VERSION ""

NS_ :

BS_:

BU_: SCM_Main SWM_Master

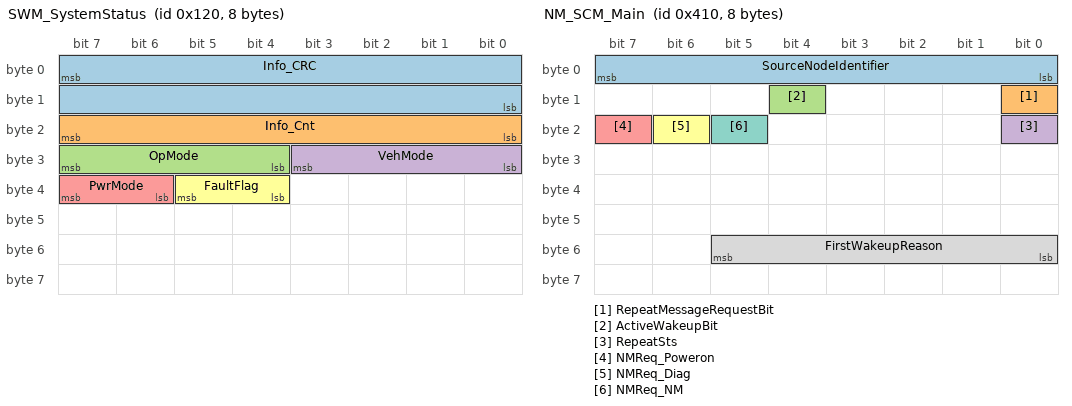
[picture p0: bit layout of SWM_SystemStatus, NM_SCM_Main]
BO_ 288 SWM_SystemStatus: 8 SWM_Master
 SG_ Info_CRC : 7|16@0+ (1,0) [0|65535] ""  SCM_Main
 SG_ Info_Cnt : 23|8@0+ (1,0) [0|255] ""  SCM_Main
 SG_ OpMode : 31|4@0+ (1,0) [0|15] ""  SCM_Main
 SG_ VehMode : 27|4@0+ (1,0) [0|15] ""  SCM_Main
 SG_ PwrMode : 39|2@0+ (1,0) [0|3] ""  SCM_Main
 SG_ FaultFlag : 37|2@0+ (1,0) [0|3] ""  SCM_Main

BO_ 528 SWM_ButtonCtrl: 32 SWM_Master
 SG_ BtnCtrl_CRC : 7|16@0+ (1,0) [0|65535] ""  SCM_Main
 SG_ BtnCtrl_RollCnt : 23|8@0+ (1,0) [0|255] ""  SCM_Main
 SG_ VolUp_Button : 29|2@0+ (1,0) [0|3] ""  SCM_Main
 SG_ VolUp_Intensity : 39|3@0+ (1,0) [0|7] "%"  SCM_Main
 SG_ VolUp_RampEnable : 50|3@0+ (1,0) [0|7] ""  SCM_Main
 SG_ VolDown_Button : 57|2@0+ (1,0) [0|3] ""  SCM_Main
 SG_ VolDown_Intensity : 69|7@0+ (1,0) [0|100] "%"  SCM_Main
 SG_ VolDown_RampEnable : 87|3@0+ (1,0) [0|7] ""  SCM_Main
 SG_ Mute_Button : 89|2@0+ (1,0) [0|3] ""  SCM_Main
 SG_ Mode_Button : 93|2@0+ (1,0) [0|3] ""  SCM_Main
 SG_ TrackNext_Button : 95|2@0+ (1,0) [0|3] ""  SCM_Main
 SG_ TrackPrev_Button : 123|4@0+ (1,0) [0|15] ""  SCM_Main
 SG_ Menu_Enter_Button : 131|4@0+ (1,0) [0|15] ""  SCM_Main
 SG_ Menu_Back_Button : 135|4@0+ (1,0) [0|15] ""  SCM_Main
 SG_ Menu_Up_Button : 139|2@0+ (1,0) [0|3] ""  SCM_Main
 SG_ Menu_Down_Button : 143|4@0+ (1,0) [0|15] ""  SCM_Main
 SG_ Menu_Left_Button : 149|2@0+ (1,0) [0|3] ""  SCM_Main
 SG_ Menu_Right_Button : 151|2@0+ (1,0) [0|3] ""  SCM_Main
 SG_ Cruise_OnOff : 155|2@0+ (1,0) [0|3] ""  SCM_Main
 SG_ Cruise_Set : 159|2@0+ (1,0) [0|3] ""  SCM_Main
 SG_ Cruise_Resume : 170|3@0+ (1,0) [0|7] ""  SCM_Main
 SG_ Cruise_Cancel : 172|2@0+ (1,0) [0|3] ""  SCM_Main
 SG_ Cruise_Accel : 203|3@0+ (1,0) [0|7] "%"  SCM_Main
 SG_ Cruise_Decel : 207|2@0+ (1,0) [0|3] ""  SCM_Main
 SG_ Phone_Answer : 213|3@0+ (1,0) [0|7] ""  SCM_Main
 SG_ Phone_Hangup : 199|3@0+ (1,0) [0|7] ""  SCM_Main
 SG_ Voice_Button : 251|4@0+ (1,0) [0|15] ""  SCM_Main

BO_ 480 EPS_SteeringData: 32 SWM_Master
 SG_ SteerData_CRC : 7|16@0+ (1,0) [0|65535] ""  SCM_Main
 SG_ SteerData_RollCnt : 23|8@0+ (1,0) [0|255] ""  SCM_Main
 SG_ TorqueSensor1 : 31|10@0+ (10,0) [0|6000] ""  SCM_Main
 SG_ TorqueSensor2 : 37|10@0+ (10,0) [0|8000] ""  SCM_Main
 SG_ SteerAngle : 62|14@0+ (0.1,-780) [-780|858.3] "deg"  SCM_Main
 SG_ SteerAngleSpeed : 64|15@0+ (0.1,-1024) [-1024|2252.7] "deg/s"  SCM_Main
 SG_ VehSpeedValid : 175|1@0+ (1,0) [0|1] ""  SCM_Main
 SG_ VehSpeed : 174|13@0+ (0.05625,0) [0|460.74375] "km/h"  SCM_Main
 SG_ RackForce_Left : 191|8@0+ (1,-80) [-80|175] "mm"  SCM_Main
 SG_ RackForce_Right : 199|8@0+ (1,-80) [-80|175] "mm"  SCM_Main
 SG_ RackForce_RearL : 207|8@0+ (1,-80) [-80|175] "mm"  SCM_Main
 SG_ RackForce_RearR : 215|8@0+ (1,-80) [-80|175] "mm"  SCM_Main
 SG_ GearPosition : 236|2@0+ (1,0) [0|3] ""  SCM_Main
 SG_ GearPosValid : 234|1@0+ (1,0) [0|1] ""  SCM_Main

BO_ 1216 SCM_AngleStatus: 32 SCM_Main
 SG_ AngleSts_CRC : 7|16@0+ (1,0) [0|65535] ""  SWM_Master
 SG_ AngleSts_RollCnt : 23|8@0+ (1,0) [0|255] ""  SWM_Master
 SG_ SteerAngleStatus : 31|2@0+ (1,0) [0|3] ""  SWM_Master
 SG_ SteerAngleValid : 39|3@0+ (1,0) [0|7] "%"  SWM_Master
 SG_ SteerAngleFault : 52|3@0+ (1,0) [0|7] ""  SWM_Master
 SG_ ClockSpringAngle : 59|2@0+ (1,0) [0|3] ""  SWM_Master
 SG_ ClockSpringFault : 69|2@0+ (1,0) [0|3] ""  SWM_Master
 SG_ ReturnLevel : 65|7@0+ (1,0) [0|100] "%"  SWM_Master
 SG_ ReturnFault : 83|3@0+ (1,0) [0|7] ""  SWM_Master
 SG_ TiltPosition : 89|2@0+ (1,0) [0|3] ""  SWM_Master
 SG_ TiltFault : 93|2@0+ (1,0) [0|3] ""  SWM_Master
 SG_ TelescopePosition : 99|2@0+ (1,0) [0|3] ""  SWM_Master
 SG_ TelescopeFault : 101|2@0+ (1,0) [0|3] ""  SWM_Master
 SG_ HeatingStatus : 103|2@0+ (1,0) [0|3] ""  SWM_Master
 SG_ HeatingFault : 133|4@0+ (1,0) [0|15] ""  SWM_Master
 SG_ LockStatus : 137|2@0+ (1,0) [0|3] ""  SWM_Master
 SG_ LockFault : 139|2@0+ (1,0) [0|3] ""  SWM_Master
 SG_ CalibrationStatus : 143|4@0+ (1,0) [0|15] ""  SWM_Master
 SG_ CalibrationFault : 145|2@0+ (1,0) [0|3] ""  SWM_Master
 SG_ ButtonSwitch_Status : 147|2@0+ (1,0) [0|3] ""  SWM_Master
 SG_ ButtonSwitch_Fault : 149|2@0+ (1,0) [0|3] ""  SWM_Master
 SG_ AFSFltSt : 151|2@0+ (1,0) [0|3] ""  SWM_Master
 SG_ SteerAssistEffectShowSt : 163|4@0+ (1,0) [0|15] ""  SWM_Master
 SG_ SWCEffectShowSt : 167|4@0+ (1,0) [0|15] ""  SWM_Master
 SG_ FLADSButtonFlt : 170|2@0+ (1,0) [0|3] ""  SWM_Master
 SG_ FLADSButtonBri : 173|3@0+ (1,0) [0|7] ""  SWM_Master
 SG_ FLADSButtonStatus : 175|2@0+ (1,0) [0|3] ""  SWM_Master
 SG_ MFLPosButtonStatus : 205|2@0+ (1,0) [0|3] ""  SWM_Master
 SG_ MFLPosButtonFlowStatus : 211|3@0+ (1,0) [0|7] ""  SWM_Master
 SG_ MFLPosButtonBri : 201|3@0+ (1,0) [0|7] "%"  SWM_Master
 SG_ MFLPosButtonFlt : 221|2@0+ (1,0) [0|3] ""  SWM_Master
 SG_ ALSPitchAg : 219|6@0+ (0.1,-4) [-4|2.3] ""  SWM_Master
 SG_ PosButtonVoiceSigSts : 189|4@0+ (1,0) [0|15] ""  SWM_Master

BO_ 1040 NM_SCM_Main: 8 SCM_Main
 SG_ SourceNodeIdentifier : 7|8@0+ (1,0) [0|255] "" Vector__XXX
 SG_ RepeatMessageRequestBit : 8|1@0+ (1,0) [0|1] "" Vector__XXX
 SG_ ActiveWakeupBit : 12|1@0+ (1,0) [0|1] "" Vector__XXX
 SG_ RepeatSts : 16|1@0+ (1,0) [0|1] "" Vector__XXX
 SG_ NMReq_Poweron : 23|1@0+ (1,0) [0|1] "" Vector__XXX
 SG_ NMReq_Diag : 22|1@0+ (1,0) [0|1] "" Vector__XXX
 SG_ NMReq_NM : 21|1@0+ (1,0) [0|1] "" Vector__XXX
 SG_ FirstWakeupReason : 53|6@0+ (1,0) [0|63] "" Vector__XXX

BO_ 2015 Diag_FunctionalReq: 64 SWM_Master
 SG_ FuncReq_Data : 7|64@0+ (1,0) [0|0] ""  SCM_Main

BO_ 1841 Diag_PhyReq_SCM: 64 SWM_Master
 SG_ PhyReq_SCM_Data : 7|64@0+ (1,0) [0|1.84467440737095E+019] ""  SCM_Main

BO_ 1969 Diag_Resp_SCM: 64 SCM_Main
 SG_ Resp_SCM_Data : 7|64@0+ (1,0) [0|1.84467440737095E+019] ""  SWM_Master

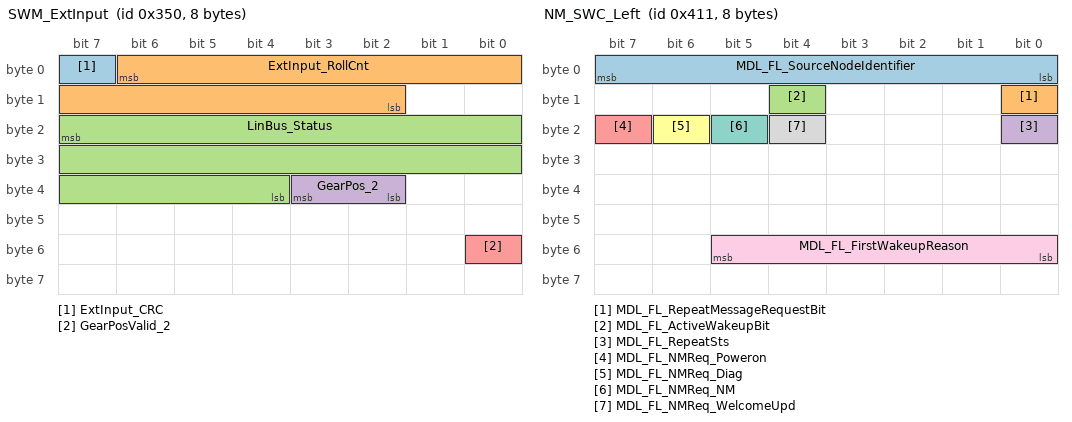
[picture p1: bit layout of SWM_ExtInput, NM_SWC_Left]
BO_ 848 SWM_ExtInput: 8 SWM_Master
 SG_ ExtInput_CRC : 7|1@0+ (1,0) [0|1] ""  SCM_Main
 SG_ ExtInput_RollCnt : 6|13@0+ (0.05625,0) [0|460.74375] "km/h"  SCM_Main
 SG_ LinBus_Status : 23|20@0+ (1,0) [0|1048575] "km"  SCM_Main
 SG_ GearPos_2 : 35|2@0+ (1,0) [0|3] ""  SCM_Main
 SG_ GearPosValid_2 : 48|1@0+ (1,0) [0|1] ""  SCM_Main

BO_ 336 SWM_Multimedia1: 32 SWM_Master
 SG_ Media1_CRC : 31|4@0+ (1,0) [0|15] ""  SCM_Main
 SG_ Media1_RollCnt : 27|4@0+ (1,0) [0|15] ""  SCM_Main
 SG_ DisplayBrightness : 39|4@0+ (1,0) [0|15] ""  SCM_Main
 SG_ DisplayContrast : 35|4@0+ (1,0) [0|15] ""  SCM_Main
 SG_ BackswitchLevel : 47|6@0+ (1,0) [0|63] ""  SCM_Main
 SG_ BackswitchAuto : 41|4@0+ (1,0) [0|15] ""  SCM_Main
 SG_ TouchSensitivity : 53|12@0+ (0.1,0) [0|409.5] "��"  SCM_Main
 SG_ TouchValid : 71|11@0+ (0.05,-40) [-40|62.35] "��"  SCM_Main
 SG_ GestureDetect : 76|11@0+ (0.05,-40) [-40|62.35] "��"  SCM_Main
 SG_ GestureType : 81|10@0+ (0.2,-50) [-50|154.6] "��/s"  SCM_Main
 SG_ ProximityDetect : 103|2@0+ (1,0) [0|3] ""  SCM_Main
 SG_ ProximityDist : 101|7@0+ (0.2,-12) [-12|13.4] "��"  SCM_Main
 SG_ AmbientSwitch_Left : 110|6@0+ (1,0) [0|63] ""  SCM_Main
 SG_ AmbientSwitch_Right : 104|4@0+ (1,0) [0|15] ""  SCM_Main
 SG_ ColorTemp_R : 116|12@0+ (0.1,0) [0|409.5] "��"  SCM_Main
 SG_ ColorTemp_G : 120|11@0+ (0.05,-40) [-40|62.35] "��"  SCM_Main
 SG_ ColorTemp_B : 141|11@0+ (0.05,-40) [-40|62.35] "��"  SCM_Main
 SG_ AnimSpeed : 146|10@0+ (0.2,-50) [-50|154.6] "��/s"  SCM_Main
 SG_ AnimMode : 152|2@0+ (1,0) [0|3] ""  SCM_Main
 SG_ ScreenSaver_On : 166|7@0+ (0.2,-12) [-12|13.4] "��"  SCM_Main
 SG_ ScreenSaver_Timeout : 175|6@0+ (1,0) [0|63] ""  SCM_Main
 SG_ ThemeSelect : 169|4@0+ (1,0) [0|15] ""  SCM_Main
 SG_ LayoutMode : 181|12@0+ (0.1,0) [0|409.5] "��"  SCM_Main
 SG_ FontSize : 185|11@0+ (0.05,-40) [-40|62.35] "��"  SCM_Main
 SG_ DensityMode : 206|11@0+ (0.05,-40) [-40|62.35] "��"  SCM_Main
 SG_ NightMode_Enable : 211|10@0+ (0.2,-50) [-50|154.6] "��/s"  SCM_Main
 SG_ NightMode_Sensor : 217|2@0+ (1,0) [0|3] ""  SCM_Main
 SG_ WakeupSource : 231|7@0+ (0.2,-12) [-12|13.4] "��"  SCM_Main
 SG_ SleepTimer : 224|7@0+ (0.2,-12) [-12|13.4] "��"  SCM_Main
 SG_ ADS_Adb2_Object_TopAngle : 233|7@0+ (0.2,-12) [-12|13.4] "��"  SCM_Main
 SG_ ADS_Adb3_Object_TopAngle : 242|7@0+ (0.2,-12) [-12|13.4] "��"  SCM_Main

BO_ 337 SWM_Multimedia2: 32 SWM_Master
 SG_ Media2_CRC : 47|6@0+ (1,0) [0|63] ""  SCM_Main
 SG_ Media2_RollCnt : 41|4@0+ (1,0) [0|15] ""  SCM_Main
 SG_ RadioPreset_1 : 53|12@0+ (0.1,0) [0|409.5] "��"  SCM_Main
 SG_ RadioPreset_2 : 71|11@0+ (0.05,-40) [-40|62.35] "��"  SCM_Main
 SG_ RadioPreset_3 : 76|11@0+ (0.05,-40) [-40|62.35] "��"  SCM_Main
 SG_ RadioPreset_4 : 81|10@0+ (0.2,-50) [-50|154.6] "��/s"  SCM_Main
 SG_ RadioPreset_5 : 103|2@0+ (1,0) [0|3] ""  SCM_Main
 SG_ RadioPreset_6 : 101|7@0+ (0.2,-12) [-12|13.4] "��"  SCM_Main
 SG_ SourceSelect : 110|6@0+ (1,0) [0|63] ""  SCM_Main
 SG_ SourceValid : 104|4@0+ (1,0) [0|15] ""  SCM_Main
 SG_ Volume_Master : 116|12@0+ (0.1,0) [0|409.5] "��"  SCM_Main
 SG_ Volume_Media : 120|11@0+ (0.05,-40) [-40|62.35] "��"  SCM_Main
 SG_ Volume_Nav : 141|11@0+ (0.05,-40) [-40|62.35] "��"  SCM_Main
 SG_ Volume_Phone : 146|10@0+ (0.2,-50) [-50|154.6] "��/s"  SCM_Main
 SG_ Bass_Level : 152|2@0+ (1,0) [0|3] ""  SCM_Main
 SG_ Treble_Level : 166|7@0+ (0.2,-12) [-12|13.4] "��"  SCM_Main
 SG_ Mid_Level : 175|6@0+ (1,0) [0|63] ""  SCM_Main
 SG_ Balance_Fade : 169|4@0+ (1,0) [0|15] ""  SCM_Main
 SG_ Surround_Mode : 181|12@0+ (0.1,0) [0|409.5] "��"  SCM_Main
 SG_ Surround_Level : 185|11@0+ (0.05,-40) [-40|62.35] "��"  SCM_Main
 SG_ EQ_Preset : 206|11@0+ (0.05,-40) [-40|62.35] "��"  SCM_Main
 SG_ EQ_Custom : 211|10@0+ (0.2,-50) [-50|154.6] "��/s"  SCM_Main
 SG_ Loudness_On : 217|2@0+ (1,0) [0|3] ""  SCM_Main
 SG_ Subwoofer_Level : 231|7@0+ (0.2,-12) [-12|13.4] "��"  SCM_Main
 SG_ Fader_Front : 224|7@0+ (0.2,-12) [-12|13.4] "��"  SCM_Main
 SG_ Fader_Rear : 233|7@0+ (0.2,-12) [-12|13.4] "��"  SCM_Main
 SG_ Balance_Left : 242|7@0+ (0.2,-12) [-12|13.4] "��"  SCM_Main

BO_ 338 SWM_Multimedia3: 32 SWM_Master
 SG_ Media3_CRC : 47|6@0+ (1,0) [0|63] ""  SCM_Main
 SG_ Media3_RollCnt : 41|4@0+ (1,0) [0|15] ""  SCM_Main
 SG_ Nav_ZoomIn : 53|12@0+ (0.1,0) [0|409.5] "��"  SCM_Main
 SG_ Nav_ZoomOut : 71|11@0+ (0.05,-40) [-40|62.35] "��"  SCM_Main
 SG_ Nav_Menu : 76|11@0+ (0.05,-40) [-40|62.35] "��"  SCM_Main
 SG_ Nav_Favorite : 81|10@0+ (0.2,-50) [-50|154.6] "��/s"  SCM_Main
 SG_ Nav_Home : 103|2@0+ (1,0) [0|3] ""  SCM_Main
 SG_ Nav_Destination : 101|7@0+ (0.2,-12) [-12|13.4] "��"  SCM_Main
 SG_ Nav_RouteCalc : 110|6@0+ (1,0) [0|63] ""  SCM_Main
 SG_ Nav_MuteGuidance : 104|4@0+ (1,0) [0|15] ""  SCM_Main
 SG_ Map_Orientation : 116|12@0+ (0.1,0) [0|409.5] "��"  SCM_Main
 SG_ Map_DayNight : 120|11@0+ (0.05,-40) [-40|62.35] "��"  SCM_Main
 SG_ Map_TrafficOn : 141|11@0+ (0.05,-40) [-40|62.35] "��"  SCM_Main
 SG_ Map_POI_Select : 146|10@0+ (0.2,-50) [-50|154.6] "��/s"  SCM_Main
 SG_ SpeedLimit_Display : 152|2@0+ (1,0) [0|3] ""  SCM_Main
 SG_ SpeedLimit_Warn : 166|7@0+ (0.2,-12) [-12|13.4] "��"  SCM_Main
 SG_ LaneGuidance_On : 175|6@0+ (1,0) [0|63] ""  SCM_Main
 SG_ LaneGuidance_Brightness : 169|4@0+ (1,0) [0|15] ""  SCM_Main
 SG_ HeadUpDisplay_On : 181|12@0+ (0.1,0) [0|409.5] "��"  SCM_Main
 SG_ HeadUpDisplay_Brightness : 185|11@0+ (0.05,-40) [-40|62.35] "��"  SCM_Main
 SG_ HeadUpDisplay_Pos : 206|11@0+ (0.05,-40) [-40|62.35] "��"  SCM_Main
 SG_ HeadUpDisplay_Rotation : 211|10@0+ (0.2,-50) [-50|154.6] "��/s"  SCM_Main
 SG_ ClusterNav_On : 217|2@0+ (1,0) [0|3] ""  SCM_Main
 SG_ ClusterNav_Mode : 231|7@0+ (0.2,-12) [-12|13.4] "��"  SCM_Main
 SG_ VoiceNav_On : 224|7@0+ (0.2,-12) [-12|13.4] "��"  SCM_Main
 SG_ VoiceNav_Volume : 233|7@0+ (0.2,-12) [-12|13.4] "��"  SCM_Main
 SG_ TrafficInfo_On : 242|7@0+ (0.2,-12) [-12|13.4] "��"  SCM_Main

BO_ 339 SWM_Multimedia4: 32 SWM_Master
 SG_ Media4_CRC : 47|6@0+ (1,0) [0|63] ""  SCM_Main
 SG_ Media4_RollCnt : 41|4@0+ (1,0) [0|15] ""  SCM_Main
 SG_ ADAS_LDWS_On : 53|12@0+ (0.1,0) [0|409.5] "��"  SCM_Main
 SG_ ADAS_LDWS_Sensitivity : 71|11@0+ (0.05,-40) [-40|62.35] "��"  SCM_Main
 SG_ ADAS_FCW_On : 76|11@0+ (0.05,-40) [-40|62.35] "��"  SCM_Main
 SG_ ADAS_FCW_Distance : 81|10@0+ (0.2,-50) [-50|154.6] "��/s"  SCM_Main
 SG_ ADAS_AEB_On : 103|2@0+ (1,0) [0|3] ""  SCM_Main
 SG_ ADAS_AEB_Sensitivity : 110|7@0+ (0.2,-12) [-12|13.4] "��"  SCM_Main
 SG_ ADAS_ACC_On : 101|7@0+ (0.2,-12) [-12|13.4] "��"  SCM_Main
 SG_ ADAS_ACC_Speed : 119|64@0+ (1,0) [0|1.84467440737095E+019] ""  SCM_Main

BO_ 1312 SCM_FaultInfo: 32 SCM_Main
 SG_ FaultInfo_CRC : 7|8@0+ (1,0) [0|255] ""  SWM_Master
 SG_ FaultInfo_RollCnt : 12|5@0+ (1,0) [0|31] ""  SWM_Master
 SG_ DTC_Severity : 15|3@0+ (1,0) [0|7] ""  SWM_Master
 SG_ DTC_HighByte : 23|12@0+ (1,0) [0|4095] ""  SWM_Master
 SG_ DTC_LowByte : 27|12@0+ (1,0) [0|4095] ""  SWM_Master
 SG_ DTC_FaultType : 47|12@0+ (1,0) [0|4095] ""  SWM_Master
 SG_ DTC_Status : 51|12@0+ (1,0) [0|4095] ""  SWM_Master
 SG_ DTC_Type : 71|12@0+ (1,0) [0|4095] ""  SWM_Master
 SG_ Fault_Age : 75|12@0+ (1,0) [0|4095] ""  SWM_Master
 SG_ Fault_Mileage : 95|12@0+ (1,0) [0|4095] ""  SWM_Master
 SG_ WarnButton_Status : 99|12@0+ (1,0) [0|4095] ""  SWM_Master
 SG_ WarnButton_Fault : 119|12@0+ (1,0) [0|4095] ""  SWM_Master
 SG_ Degraded_Mode : 123|12@0+ (1,0) [0|4095] ""  SWM_Master
 SG_ Recovery_Status : 143|12@0+ (1,0) [0|4095] ""  SWM_Master
 SG_ SelfTest_Result : 147|12@0+ (1,0) [0|4095] ""  SWM_Master
 SG_ SelfTest_Progress : 167|12@0+ (1,0) [0|4095] ""  SWM_Master
 SG_ FaultNum14 : 171|12@0+ (1,0) [0|4095] ""  SWM_Master
 SG_ FaultNum15 : 191|12@0+ (1,0) [0|4095] ""  SWM_Master
 SG_ FaultNum16 : 195|12@0+ (1,0) [0|4095] ""  SWM_Master
 SG_ FaultNum17 : 215|12@0+ (1,0) [0|4095] ""  SWM_Master
 SG_ FaultNum18 : 219|12@0+ (1,0) [0|4095] ""  SWM_Master
 SG_ FaultNum19 : 239|12@0+ (1,0) [0|4095] ""  SWM_Master
 SG_ FaultNum20 : 243|12@0+ (1,0) [0|4095] ""  SWM_Master

BO_ 1041 NM_SWC_Left: 8 Vector__XXX
 SG_ MDL_FL_SourceNodeIdentifier : 7|8@0+ (1,0) [0|255] ""  SWM_Master,SCM_Main
 SG_ MDL_FL_RepeatMessageRequestBit : 8|1@0+ (1,0) [0|1] ""  SWM_Master,SCM_Main
 SG_ MDL_FL_ActiveWakeupBit : 12|1@0+ (1,0) [0|1] ""  SWM_Master,SCM_Main
 SG_ MDL_FL_RepeatSts : 16|1@0+ (1,0) [0|1] ""  SWM_Master,SCM_Main
 SG_ MDL_FL_NMReq_Poweron : 23|1@0+ (1,0) [0|1] ""  SWM_Master,SCM_Main
 SG_ MDL_FL_NMReq_Diag : 22|1@0+ (1,0) [0|1] ""  SWM_Master,SCM_Main
 SG_ MDL_FL_NMReq_NM : 21|1@0+ (1,0) [0|1] ""  SWM_Master,SCM_Main
 SG_ MDL_FL_NMReq_WelcomeUpd : 20|1@0+ (1,0) [0|1] ""  SWM_Master,SCM_Main
 SG_ MDL_FL_FirstWakeupReason : 53|6@0+ (1,0) [0|63] ""  SWM_Master,SCM_Main

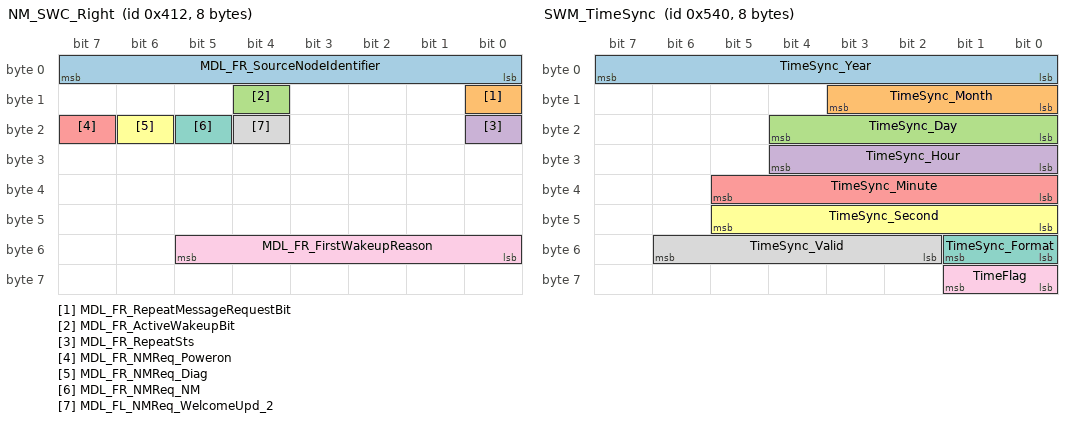
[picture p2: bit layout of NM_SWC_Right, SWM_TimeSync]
BO_ 1042 NM_SWC_Right: 8 Vector__XXX
 SG_ MDL_FR_SourceNodeIdentifier : 7|8@0+ (1,0) [0|255] ""  SWM_Master,SCM_Main
 SG_ MDL_FR_RepeatMessageRequestBit : 8|1@0+ (1,0) [0|1] ""  SWM_Master,SCM_Main
 SG_ MDL_FR_ActiveWakeupBit : 12|1@0+ (1,0) [0|1] ""  SWM_Master,SCM_Main
 SG_ MDL_FR_RepeatSts : 16|1@0+ (1,0) [0|1] ""  SWM_Master,SCM_Main
 SG_ MDL_FR_NMReq_Poweron : 23|1@0+ (1,0) [0|1] ""  SWM_Master,SCM_Main
 SG_ MDL_FR_NMReq_Diag : 22|1@0+ (1,0) [0|1] ""  SWM_Master,SCM_Main
 SG_ MDL_FR_NMReq_NM : 21|1@0+ (1,0) [0|1] ""  SWM_Master,SCM_Main
 SG_ MDL_FL_NMReq_WelcomeUpd_2 : 20|1@0+ (1,0) [0|1] ""  SWM_Master,SCM_Main
 SG_ MDL_FR_FirstWakeupReason : 53|6@0+ (1,0) [0|63] ""  SWM_Master,SCM_Main

BO_ 1344 SWM_TimeSync: 8 SWM_Master
 SG_ TimeSync_Year : 7|8@0+ (1,2000) [2000|2255] "Year"  SCM_Main
 SG_ TimeSync_Month : 11|4@0+ (1,0) [1|12] "Month"  SCM_Main
 SG_ TimeSync_Day : 20|5@0+ (1,0) [1|31] "Day"  SCM_Main
 SG_ TimeSync_Hour : 28|5@0+ (1,0) [0|23] "h"  SCM_Main
 SG_ TimeSync_Minute : 37|6@0+ (1,0) [0|59] "min"  SCM_Main
 SG_ TimeSync_Second : 45|6@0+ (1,0) [0|59] "s"  SCM_Main
 SG_ TimeSync_Format : 49|2@0+ (1,0) [0|3] ""  SCM_Main
 SG_ TimeSync_Valid : 54|5@0+ (1,0) [0|31] ""  SCM_Main
 SG_ TimeFlag : 57|2@0+ (1,0) [0|3] ""  SCM_Main

CM_ "Version:V1.2,Date:2026/2/6,Author:Pengwanli��lican,wangzhilin,Review:,Approval:,Description:(SCM_FL)1��0x280�ź�SWM_FrontADSButtonBriSet���ö��ֵ--Ѧ����;
Version:V1.2,Date:2026/2/6,Author:Pengwanli��lican,wangzhilin,Review:,Approval:,Description:(SCM_FL)SCM_FL���0x500�ź�SCM_FL_FLADSButtonBri��ö��ֵ--Ѧ����;
 ";
CM_ BO_ 288 "�����û�ģʽ����Դģʽ";
CM_ SG_ 288 Info_CRC "CRC16 Checksum (Data ID: 0x41D2)";
CM_ SG_ 288 Info_Cnt "RollingCounter";
CM_ SG_ 288 OpMode "�����û�ģʽ";
CM_ SG_ 288 VehMode "����ģʽ";
CM_ SG_ 288 PwrMode "������Դģʽ";
CM_ SG_ 288 FaultFlag "��Դģʽ����״̬";
CM_ BO_ 528 "VIU�ձ๦��";
CM_ SG_ 528 BtnCtrl_CRC "CRC16 checksum��Data ID: 0x4378��";
CM_ SG_ 528 BtnCtrl_RollCnt "Rolling Counter";
CM_ SG_ 528 VolUp_Button "��ǰλ�Ƶ����ر�����";
CM_ SG_ 528 VolUp_Intensity "��ǰλ����������";
CM_ SG_ 528 VolUp_RampEnable "��ǰλ����ˮʹ��";
CM_ SG_ 528 VolDown_Button "��ǰת��Ƶ����ر�����";
CM_ SG_ 528 VolDown_Intensity "��ǰת�����������";
CM_ SG_ 528 VolDown_RampEnable "��ǰת�����ˮʹ��";
CM_ SG_ 528 Mute_Button "Զ��Ƶ����ر�����";
CM_ SG_ 528 Mode_Button "����Ƶ����ر�����";
CM_ SG_ 528 TrackNext_Button "����Ӧǰ�յ�ϵͳʹ��";
CM_ SG_ 528 TrackPrev_Button "ǰ�ᴩ�Ƶ���Ч����������";
CM_ SG_ 528 Menu_Enter_Button "����Ƶ���Ч����������";
CM_ SG_ 528 Menu_Back_Button "ǰ�ᴩ�Ƶ���Ч��ѡ��";
CM_ SG_ 528 Menu_Up_Button "λ�õƹ���״̬";
CM_ SG_ 528 Menu_Down_Button "����Ƶ���Ч��ѡ��";
CM_ SG_ 528 Menu_Left_Button "����ӦԶ��ƹ��ܼ�������";
CM_ SG_ 528 Menu_Right_Button "����ƹ���״̬";
CM_ SG_ 528 Cruise_OnOff "ǰ�ᴩ�Ƶ���Ч��ģʽ����";
CM_ SG_ 528 Cruise_Set "����Ƶ���Ч��ģʽ����";
CM_ SG_ 528 Cruise_Resume "ǰADS����������";
CM_ SG_ 528 Cruise_Cancel "ǰADS�Ƶ����ر�����";
CM_ SG_ 528 Cruise_Accel "��ǰ��λ����������";
CM_ SG_ 528 Cruise_Decel "��ǰ��λ�Ƶ����ر�����";
CM_ SG_ 528 Phone_Answer "��ǰ��λ����ˮʹ������";
CM_ SG_ 528 Phone_Hangup "����Ƹ߶ȵ�λ";
CM_ SG_ 528 Voice_Button "��ǰλ��������������";
CM_ BO_ 480 "�ź�·��";
CM_ SG_ 480 SteerData_CRC "CRC16 checksum��Data ID: 0x42A4��";
CM_ SG_ 480 SteerData_RollCnt "Rolling Counter";
CM_ SG_ 480 TorqueSensor1 "ǰ���ֵ";
CM_ SG_ 480 TorqueSensor2 "����������ֵ";
CM_ SG_ 480 SteerAngle "ת��(���λ��ת�������ֳ������ϵ�ĽǶȣ������Ҹ�)Pinion angle(0x3CF1~0x3FFE:reserved)";
CM_ SG_ 480 SteerAngleSpeed "ת���ٶ�(���λ��ת�������ֳ������ϵ�ĽǶȣ������Ҹ�)Pinion angle(0x5001~0x7FFE:reserved)";
CM_ SG_ 480 VehSpeedValid "vehicle reference speed Valid
������Чλ";
CM_ SG_ 480 VehSpeed "vehicle reference speed
����";
CM_ SG_ 480 RackForce_Left "ʵ����ǰ������Ը߶�(����ڿջɱ�׼�߶����������½��ĸ߶�ֵ)";
CM_ SG_ 480 RackForce_Right "ʵ����ǰ������Ը߶�(����ڿջɱ�׼�߶����������½��ĸ߶�ֵ)";
CM_ SG_ 480 RackForce_RearL "ʵ���������Ը߶�(����ڿջɱ�׼�߶����������½��ĸ߶�ֵ)";
CM_ SG_ 480 RackForce_RearR "ʵ���Һ�����Ը߶�(����ڿջɱ�׼�߶����������½��ĸ߶�ֵ)";
CM_ SG_ 480 GearPosition "Actual gear engaged
��ʵ��λ";
CM_ SG_ 480 GearPosValid "Actual gear valid signal
��ʵ��λ��Чλ";
CM_ SG_ 1216 AngleSts_CRC "CRC16 checksum��Data ID: 0x455F��";
CM_ SG_ 1216 AngleSts_RollCnt "Rolling Counter";
CM_ SG_ 1216 SteerAngleStatus "��ǰλ�Ƶ����ر�״̬";
CM_ SG_ 1216 SteerAngleValid "��ǰλ������";
CM_ SG_ 1216 SteerAngleFault "��ǰλ����ˮ״̬";
CM_ SG_ 1216 ClockSpringAngle "��ǰλ�ƹ���";
CM_ SG_ 1216 ClockSpringFault "��ǰת��Ƶ����ر�״̬";
CM_ SG_ 1216 ReturnLevel "��ǰת�������";
CM_ SG_ 1216 ReturnFault "��ǰת�����ˮ״̬";
CM_ SG_ 1216 TiltPosition "�����Ƶ����ر�״̬";
CM_ SG_ 1216 TiltFault "��ǰת��ƹ���";
CM_ SG_ 1216 TelescopePosition "��Զ��ƹ���״̬";
CM_ SG_ 1216 TelescopeFault "��Զ��Ƶ����ر�״̬";
CM_ SG_ 1216 HeatingStatus "�����ƹ���";
CM_ SG_ 1216 HeatingFault "��ǰ�ᴩ�Ƶ���Ч��״̬";
CM_ SG_ 1216 LockStatus "������ӦԶ��ƹ��ܹ���״̬";
CM_ SG_ 1216 LockFault "������ӦԶ��ƹ��ܿ���״̬";
CM_ SG_ 1216 CalibrationStatus "�����Ƶ���Ч��״̬";
CM_ SG_ 1216 CalibrationFault "��ALS���ܹ���״̬";
CM_ SG_ 1216 ButtonSwitch_Status "��AFS����ʵ��ʹ��״̬";
CM_ SG_ 1216 ButtonSwitch_Fault "��AFS���ܿ���״̬";
CM_ SG_ 1216 AFSFltSt "��AFS���ܹ���״̬";
CM_ SG_ 1216 SteerAssistEffectShowSt "�����Ƶ�����ʾ״̬";
CM_ SG_ 1216 SWCEffectShowSt "��ǰ�ᴩ�Ƶ�����ʾ״̬";
CM_ SG_ 1216 FLADSButtonFlt "��ǰADS�ƹ���";
CM_ SG_ 1216 FLADSButtonBri "��ǰADS������";
CM_ SG_ 1216 FLADSButtonStatus "��ǰADS�Ƶ����ر�״̬";
CM_ SG_ 1216 MFLPosButtonStatus "��ǰ��λ�Ƶ����ر�״̬";
CM_ SG_ 1216 MFLPosButtonFlowStatus "��ǰ��λ����ˮ״̬";
CM_ SG_ 1216 MFLPosButtonBri "��ǰ��λ������";
CM_ SG_ 1216 MFLPosButtonFlt "��ǰ��λ�ƹ���";
CM_ SG_ 1216 ALSPitchAg "�󳵵Ƹ����Ƕ�";
CM_ SG_ 1216 PosButtonVoiceSigSts "��ǰ������Ч״̬";
CM_ SG_ 1040 SourceNodeIdentifier "Դ�ڵ�ID";
CM_ SG_ 1040 RepeatMessageRequestBit "�ظ���������λ";
CM_ SG_ 1040 ActiveWakeupBit "�������ѱ�־λ";
CM_ SG_ 1040 RepeatSts "�ظ�����״̬";
CM_ SG_ 1040 NMReq_Poweron "����Ӳ��ON��������";
CM_ SG_ 1040 NMReq_Diag "�������������";
CM_ SG_ 1040 NMReq_NM "��NM���Ļ�����������";
CM_ SG_ 1040 FirstWakeupReason "SCM_FL�״λ���ԭ��";
CM_ SG_ 2015 FuncReq_Data "Diagnostic Functional Request Data";
CM_ SG_ 1841 PhyReq_SCM_Data "Diag_PhyReq_SCM_FL_Data";
CM_ SG_ 1969 Resp_SCM_Data "Diag_Resp_SCM_FL_Data";
CM_ SG_ 848 ExtInput_CRC "vehicle reference speed Valid
������Чλ";
CM_ SG_ 848 ExtInput_RollCnt "vehicle reference speed
����";
CM_ SG_ 848 LinBus_Status "���������ڵĳ�������ʻ���";
CM_ SG_ 848 GearPos_2 "Actual gear engaged
��ʵ��λ";
CM_ SG_ 848 GearPosValid_2 "Actual gear valid signal
��ʵ��λ��Чλ";
CM_ SG_ 336 Media1_CRC "�����״̬";
CM_ SG_ 336 Media1_RollCnt "̽��Ŀ����";
CM_ SG_ 336 DisplayBrightness "��������";
CM_ SG_ 336 DisplayContrast "��ͨ����";
CM_ SG_ 336 BackswitchLevel "Ŀ��1���";
CM_ SG_ 336 BackswitchAuto "����";
CM_ SG_ 336 TouchSensitivity "����";
CM_ SG_ 336 TouchValid "��߽�Ƕ�";
CM_ SG_ 336 GestureDetect "�ұ߽�Ƕ�";
CM_ SG_ 336 GestureType "ˮƽ���ٶ�";
CM_ SG_ 336 ProximityDetect "����";
CM_ SG_ 336 ProximityDist "�±߽�Ƕ�";
CM_ SG_ 336 AmbientSwitch_Left "Ŀ��2���";
CM_ SG_ 336 AmbientSwitch_Right "����";
CM_ SG_ 336 ColorTemp_R "����";
CM_ SG_ 336 ColorTemp_G "��߽�Ƕ�";
CM_ SG_ 336 ColorTemp_B "�ұ߽�Ƕ�";
CM_ SG_ 336 AnimSpeed "ˮƽ���ٶ�";
CM_ SG_ 336 AnimMode "����";
CM_ SG_ 336 ScreenSaver_On "�±߽�Ƕ�";
CM_ SG_ 336 ScreenSaver_Timeout "Ŀ��3���";
CM_ SG_ 336 ThemeSelect "����";
CM_ SG_ 336 LayoutMode "����";
CM_ SG_ 336 FontSize "��߽�Ƕ�";
CM_ SG_ 336 DensityMode "�ұ߽�Ƕ�";
CM_ SG_ 336 NightMode_Enable "ˮƽ���ٶ�";
CM_ SG_ 336 NightMode_Sensor "����";
CM_ SG_ 336 WakeupSource "�±߽�Ƕ�";
CM_ SG_ 336 SleepTimer "Ŀ��1�ϱ߽�Ƕ�";
CM_ SG_ 336 ADS_Adb2_Object_TopAngle "Ŀ��2�ϱ߽�Ƕ�";
CM_ SG_ 336 ADS_Adb3_Object_TopAngle "Ŀ��3�ϱ߽�Ƕ�";
CM_ SG_ 337 Media2_CRC "Ŀ��4���";
CM_ SG_ 337 Media2_RollCnt "����";
CM_ SG_ 337 RadioPreset_1 "����";
CM_ SG_ 337 RadioPreset_2 "��߽�Ƕ�";
CM_ SG_ 337 RadioPreset_3 "�ұ߽�Ƕ�";
CM_ SG_ 337 RadioPreset_4 "ˮƽ���ٶ�";
CM_ SG_ 337 RadioPreset_5 "����";
CM_ SG_ 337 RadioPreset_6 "�±߽�Ƕ�";
CM_ SG_ 337 SourceSelect "Ŀ��5���";
CM_ SG_ 337 SourceValid "����";
CM_ SG_ 337 Volume_Master "����";
CM_ SG_ 337 Volume_Media "��߽�Ƕ�";
CM_ SG_ 337 Volume_Nav "�ұ߽�Ƕ�";
CM_ SG_ 337 Volume_Phone "ˮƽ���ٶ�";
CM_ SG_ 337 Bass_Level "����";
CM_ SG_ 337 Treble_Level "�±߽�Ƕ�";
CM_ SG_ 337 Mid_Level "Ŀ��6���";
CM_ SG_ 337 Balance_Fade "����";
CM_ SG_ 337 Surround_Mode "����";
CM_ SG_ 337 Surround_Level "��߽�Ƕ�";
CM_ SG_ 337 EQ_Preset "�ұ߽�Ƕ�";
CM_ SG_ 337 EQ_Custom "ˮƽ���ٶ�";
CM_ SG_ 337 Loudness_On "����";
CM_ SG_ 337 Subwoofer_Level "�±߽�Ƕ�";
CM_ SG_ 337 Fader_Front "Ŀ��4�ϱ߽�Ƕ�";
CM_ SG_ 337 Fader_Rear "Ŀ��5�ϱ߽�Ƕ�";
CM_ SG_ 337 Balance_Left "Ŀ��6�ϱ߽�Ƕ�";
CM_ SG_ 338 Media3_CRC "Ŀ��7���";
CM_ SG_ 338 Media3_RollCnt "����";
CM_ SG_ 338 Nav_ZoomIn "����";
CM_ SG_ 338 Nav_ZoomOut "��߽�Ƕ�";
CM_ SG_ 338 Nav_Menu "�ұ߽�Ƕ�";
CM_ SG_ 338 Nav_Favorite "ˮƽ���ٶ�";
CM_ SG_ 338 Nav_Home "����";
CM_ SG_ 338 Nav_Destination "�±߽�Ƕ�";
CM_ SG_ 338 Nav_RouteCalc "Ŀ��8���";
CM_ SG_ 338 Nav_MuteGuidance "����";
CM_ SG_ 338 Map_Orientation "����";
CM_ SG_ 338 Map_DayNight "��߽�Ƕ�";
CM_ SG_ 338 Map_TrafficOn "�ұ߽�Ƕ�";
CM_ SG_ 338 Map_POI_Select "ˮƽ���ٶ�";
CM_ SG_ 338 SpeedLimit_Display "����";
CM_ SG_ 338 SpeedLimit_Warn "�±߽�Ƕ�";
CM_ SG_ 338 LaneGuidance_On "Ŀ��9���";
CM_ SG_ 338 LaneGuidance_Brightness "����";
CM_ SG_ 338 HeadUpDisplay_On "����";
CM_ SG_ 338 HeadUpDisplay_Brightness "��߽�Ƕ�";
CM_ SG_ 338 HeadUpDisplay_Pos "�ұ߽�Ƕ�";
CM_ SG_ 338 HeadUpDisplay_Rotation "ˮƽ���ٶ�";
CM_ SG_ 338 ClusterNav_On "����";
CM_ SG_ 338 ClusterNav_Mode "�±߽�Ƕ�";
CM_ SG_ 338 VoiceNav_On "Ŀ��7�ϱ߽�Ƕ�";
CM_ SG_ 338 VoiceNav_Volume "Ŀ��8�ϱ߽�Ƕ�";
CM_ SG_ 338 TrafficInfo_On "Ŀ��9�ϱ߽�Ƕ�";
CM_ SG_ 339 Media4_CRC "Ŀ��10���";
CM_ SG_ 339 Media4_RollCnt "����";
CM_ SG_ 339 ADAS_LDWS_On "����";
CM_ SG_ 339 ADAS_LDWS_Sensitivity "��߽�Ƕ�";
CM_ SG_ 339 ADAS_FCW_On "�ұ߽�Ƕ�";
CM_ SG_ 339 ADAS_FCW_Distance "ˮƽ���ٶ�";
CM_ SG_ 339 ADAS_AEB_On "����";
CM_ SG_ 339 ADAS_AEB_Sensitivity "Ŀ��10�ϱ߽�Ƕ�";
CM_ SG_ 339 ADAS_ACC_On "�±߽�Ƕ�";
CM_ SG_ 339 ADAS_ACC_Speed "��֪ʱ���";
CM_ BO_ 1312 "SCM_FLԶ�̹�������ź�";
CM_ SG_ 1312 FaultInfo_CRC "��ǰ��������";
CM_ SG_ 1312 FaultInfo_RollCnt "֡���";
CM_ SG_ 1312 DTC_Severity "��Ӧ�̴���";
CM_ SG_ 1312 DTC_HighByte "���ϱ��1";
CM_ SG_ 1312 DTC_LowByte "���ϱ��2";
CM_ SG_ 1312 DTC_FaultType "���ϱ��3";
CM_ SG_ 1312 DTC_Status "���ϱ��4";
CM_ SG_ 1312 DTC_Type "���ϱ��5";
CM_ SG_ 1312 Fault_Age "���ϱ��6";
CM_ SG_ 1312 Fault_Mileage "���ϱ��7";
CM_ SG_ 1312 WarnButton_Status "���ϱ��8";
CM_ SG_ 1312 WarnButton_Fault "���ϱ��9";
CM_ SG_ 1312 Degraded_Mode "���ϱ��10";
CM_ SG_ 1312 Recovery_Status "���ϱ��11";
CM_ SG_ 1312 SelfTest_Result "���ϱ��12";
CM_ SG_ 1312 SelfTest_Progress "���ϱ��13";
CM_ SG_ 1312 FaultNum14 "���ϱ��14";
CM_ SG_ 1312 FaultNum15 "���ϱ��15";
CM_ SG_ 1312 FaultNum16 "���ϱ��16";
CM_ SG_ 1312 FaultNum17 "���ϱ��17";
CM_ SG_ 1312 FaultNum18 "���ϱ��18";
CM_ SG_ 1312 FaultNum19 "���ϱ��19";
CM_ SG_ 1312 FaultNum20 "���ϱ��20";
CM_ SG_ 1041 MDL_FL_SourceNodeIdentifier "Դ�ڵ�ID";
CM_ SG_ 1041 MDL_FL_RepeatMessageRequestBit "�ظ���������λ";
CM_ SG_ 1041 MDL_FL_ActiveWakeupBit "�������ѱ�־λ";
CM_ SG_ 1041 MDL_FL_RepeatSts "�ظ�����״̬";
CM_ SG_ 1041 MDL_FL_NMReq_Poweron "����Ӳ��ON��������";
CM_ SG_ 1041 MDL_FL_NMReq_Diag "�������������";
CM_ SG_ 1041 MDL_FL_NMReq_NM "��NM���Ļ�����������";
CM_ SG_ 1041 MDL_FL_NMReq_WelcomeUpd "��ӭ��������������";
CM_ SG_ 1041 MDL_FL_FirstWakeupReason "MDL_FL�״λ���ԭ��";
CM_ SG_ 1042 MDL_FR_SourceNodeIdentifier "Դ�ڵ�ID";
CM_ SG_ 1042 MDL_FR_RepeatMessageRequestBit "�ظ���������λ";
CM_ SG_ 1042 MDL_FR_ActiveWakeupBit "�������ѱ�־λ";
CM_ SG_ 1042 MDL_FR_RepeatSts "�ظ�����״̬";
CM_ SG_ 1042 MDL_FR_NMReq_Poweron "����Ӳ��ON��������";
CM_ SG_ 1042 MDL_FR_NMReq_Diag "�������������";
CM_ SG_ 1042 MDL_FR_NMReq_NM "��NM���Ļ�����������";
CM_ SG_ 1042 MDL_FL_NMReq_WelcomeUpd_2 "��ӭ��������������";
CM_ SG_ 1042 MDL_FR_FirstWakeupReason "MDL_FR�״λ���ԭ��";
CM_ SG_ 1344 TimeSync_Year "����ʱ��_��";
CM_ SG_ 1344 TimeSync_Month "����ʱ��_��";
CM_ SG_ 1344 TimeSync_Day "����ʱ��_��";
CM_ SG_ 1344 TimeSync_Hour "����ʱ��_ʱ";
CM_ SG_ 1344 TimeSync_Minute "����ʱ��_��";
CM_ SG_ 1344 TimeSync_Second "����ʱ��_��";
CM_ SG_ 1344 TimeSync_Format "��/��ʱ��";
CM_ SG_ 1344 TimeSync_Valid "ʱ�����";
CM_ SG_ 1344 TimeFlag "ʱ����Ч�Ա�־";
BA_DEF_ BO_  "NmMessage" ENUM  "No","Yes";
BA_DEF_ BO_  "DiagState" ENUM  "No","Yes";
BA_DEF_ BO_  "DiagResponse" ENUM  "No","Yes";
BA_DEF_ BO_  "GenMsgSendType" ENUM  "Cyclic","Event","IfActive","CE","CA","NoMsgSendType";
BA_DEF_ BO_  "GenMsgCycleTime" INT 0 0;
BA_DEF_ SG_  "GenSigSendType" ENUM  "Cyclic","OnChange","OnWrite","IfActive","OnChangeWithRepetition","OnWriteWithRepetition","IfActiveWithRepetition","NoSigSendType","OnChangeAndIfActive","OnChangeAndIfActiveWithRepetition","CA","CE","Event";
BA_DEF_ SG_  "GenSigStartValue" INT 0 0;
BA_DEF_ BO_  "GenMsgCycleTimeFast" INT 0 0;
BA_DEF_ BO_  "GenMsgNrOfRepetition" INT 0 0;
BA_DEF_  "DBName" STRING ;
BA_DEF_ BO_  "CANFD_BRS" ENUM  "0","1";
BA_DEF_ BO_  "VFrameFormat" ENUM  "StandardCAN","ExtendedCAN","reserved","reserved","reserved","reserved","reserved","reserved","reserved","reserved","reserved","reserved","reserved","reserved","StandardCAN_FD","ExtendedCAN_FD";
BA_DEF_  "NmMessageCount" INT 0 255;
BA_DEF_  "NmBaseAddress" HEX 1024 1087;
BA_DEF_  "BusType" STRING ;
BA_DEF_ SG_  "sigSecLevel" ENUM  "QM","A","B","C","D";
BA_DEF_DEF_  "NmMessage" "No";
BA_DEF_DEF_  "DiagState" "No";
BA_DEF_DEF_  "DiagResponse" "No";
BA_DEF_DEF_  "GenMsgSendType" "Cyclic";
BA_DEF_DEF_  "GenMsgCycleTime" 0;
BA_DEF_DEF_  "GenSigSendType" "Cyclic";
BA_DEF_DEF_  "GenSigStartValue" 0;
BA_DEF_DEF_  "GenMsgCycleTimeFast" 0;
BA_DEF_DEF_  "GenMsgNrOfRepetition" 0;
BA_DEF_DEF_  "DBName" "";
BA_DEF_DEF_  "CANFD_BRS" "1";
BA_DEF_DEF_  "VFrameFormat" "StandardCAN_FD";
BA_DEF_DEF_  "NmMessageCount" 128;
BA_DEF_DEF_  "NmBaseAddress" 1024;
BA_DEF_DEF_  "BusType" "CAN FD";
BA_DEF_DEF_  "sigSecLevel" "QM";
BA_ "DBName" "BAIC_X90KS_FBUS_Matrix_CANFD_V12";
BA_ "GenMsgCycleTime" BO_ 288 20;
BA_ "GenMsgNrOfRepetition" BO_ 528 3;
BA_ "GenMsgCycleTimeFast" BO_ 528 20;
BA_ "GenMsgCycleTime" BO_ 528 100;
BA_ "GenMsgSendType" BO_ 528 3;
BA_ "GenMsgCycleTime" BO_ 480 50;
BA_ "GenMsgNrOfRepetition" BO_ 1216 3;
BA_ "GenMsgCycleTimeFast" BO_ 1216 20;
BA_ "GenMsgCycleTime" BO_ 1216 100;
BA_ "GenMsgSendType" BO_ 1216 3;
BA_ "VFrameFormat" BO_ 1040 0;
BA_ "CANFD_BRS" BO_ 1040 0;
BA_ "GenMsgSendType" BO_ 1040 1;
BA_ "NmMessage" BO_ 1040 1;
BA_ "GenMsgSendType" BO_ 2015 1;
BA_ "DiagResponse" BO_ 2015 1;
BA_ "DiagState" BO_ 2015 1;
BA_ "GenMsgSendType" BO_ 1841 1;
BA_ "DiagResponse" BO_ 1841 1;
BA_ "DiagState" BO_ 1841 1;
BA_ "GenMsgSendType" BO_ 1969 1;
BA_ "DiagResponse" BO_ 1969 1;
BA_ "DiagState" BO_ 1969 1;
BA_ "GenMsgCycleTime" BO_ 848 100;
BA_ "GenMsgCycleTime" BO_ 336 20;
BA_ "GenMsgCycleTime" BO_ 337 20;
BA_ "GenMsgCycleTime" BO_ 338 20;
BA_ "GenMsgCycleTime" BO_ 339 20;
BA_ "GenMsgCycleTime" BO_ 1312 500;
BA_ "VFrameFormat" BO_ 1041 0;
BA_ "CANFD_BRS" BO_ 1041 0;
BA_ "GenMsgSendType" BO_ 1041 1;
BA_ "NmMessage" BO_ 1041 1;
BA_ "VFrameFormat" BO_ 1042 0;
BA_ "CANFD_BRS" BO_ 1042 0;
BA_ "GenMsgSendType" BO_ 1042 1;
BA_ "NmMessage" BO_ 1042 1;
BA_ "GenMsgCycleTime" BO_ 1344 500;
BA_ "GenSigStartValue" SG_ 288 OpMode 1;
BA_ "GenSigStartValue" SG_ 288 VehMode 14;
BA_ "GenSigSendType" SG_ 528 VolUp_Button 4;
BA_ "GenSigSendType" SG_ 528 VolUp_Intensity 4;
BA_ "GenSigSendType" SG_ 528 VolUp_RampEnable 4;
BA_ "GenSigSendType" SG_ 528 VolDown_Button 4;
BA_ "GenSigSendType" SG_ 528 VolDown_Intensity 4;
BA_ "GenSigSendType" SG_ 528 VolDown_RampEnable 4;
BA_ "GenSigSendType" SG_ 528 Mute_Button 4;
BA_ "GenSigSendType" SG_ 528 Mode_Button 4;
BA_ "GenSigSendType" SG_ 528 TrackNext_Button 4;
BA_ "GenSigSendType" SG_ 528 TrackPrev_Button 4;
BA_ "GenSigSendType" SG_ 528 Menu_Enter_Button 4;
BA_ "GenSigSendType" SG_ 528 Menu_Back_Button 4;
BA_ "GenSigSendType" SG_ 528 Menu_Up_Button 4;
BA_ "GenSigSendType" SG_ 528 Menu_Down_Button 4;
BA_ "GenSigSendType" SG_ 528 Menu_Left_Button 4;
BA_ "GenSigSendType" SG_ 528 Menu_Right_Button 4;
BA_ "GenSigSendType" SG_ 528 Cruise_OnOff 4;
BA_ "GenSigSendType" SG_ 528 Cruise_Set 4;
BA_ "GenSigSendType" SG_ 528 Cruise_Resume 4;
BA_ "GenSigSendType" SG_ 528 Cruise_Cancel 4;
BA_ "GenSigSendType" SG_ 528 Cruise_Accel 4;
BA_ "GenSigSendType" SG_ 528 Cruise_Decel 4;
BA_ "GenSigSendType" SG_ 528 Phone_Answer 4;
BA_ "GenSigSendType" SG_ 528 Phone_Hangup 4;
BA_ "GenSigSendType" SG_ 528 Voice_Button 4;
BA_ "GenSigStartValue" SG_ 480 TorqueSensor1 1022;
BA_ "GenSigStartValue" SG_ 480 TorqueSensor2 1022;
BA_ "GenSigStartValue" SG_ 480 SteerAngle 7800;
BA_ "GenSigStartValue" SG_ 480 SteerAngleSpeed 10240;
BA_ "GenSigSendType" SG_ 1216 SteerAngleStatus 4;
BA_ "GenSigSendType" SG_ 1216 SteerAngleValid 4;
BA_ "GenSigSendType" SG_ 1216 SteerAngleFault 4;
BA_ "GenSigSendType" SG_ 1216 ClockSpringAngle 4;
BA_ "GenSigSendType" SG_ 1216 ClockSpringFault 4;
BA_ "GenSigSendType" SG_ 1216 ReturnLevel 4;
BA_ "GenSigSendType" SG_ 1216 ReturnFault 4;
BA_ "GenSigSendType" SG_ 1216 TiltPosition 4;
BA_ "GenSigSendType" SG_ 1216 TiltFault 4;
BA_ "GenSigSendType" SG_ 1216 TelescopePosition 4;
BA_ "GenSigSendType" SG_ 1216 TelescopeFault 4;
BA_ "GenSigSendType" SG_ 1216 HeatingStatus 4;
BA_ "GenSigSendType" SG_ 1216 HeatingFault 4;
BA_ "GenSigSendType" SG_ 1216 LockStatus 4;
BA_ "GenSigSendType" SG_ 1216 LockFault 4;
BA_ "GenSigSendType" SG_ 1216 CalibrationStatus 4;
BA_ "GenSigSendType" SG_ 1216 CalibrationFault 4;
BA_ "GenSigSendType" SG_ 1216 ButtonSwitch_Status 4;
BA_ "GenSigSendType" SG_ 1216 ButtonSwitch_Fault 4;
BA_ "GenSigSendType" SG_ 1216 AFSFltSt 4;
BA_ "GenSigSendType" SG_ 1216 SteerAssistEffectShowSt 4;
BA_ "GenSigSendType" SG_ 1216 SWCEffectShowSt 4;
BA_ "GenSigSendType" SG_ 1216 FLADSButtonFlt 4;
BA_ "GenSigSendType" SG_ 1216 FLADSButtonBri 4;
BA_ "GenSigSendType" SG_ 1216 FLADSButtonStatus 4;
BA_ "GenSigSendType" SG_ 1216 MFLPosButtonStatus 4;
BA_ "GenSigSendType" SG_ 1216 MFLPosButtonFlowStatus 4;
BA_ "GenSigSendType" SG_ 1216 MFLPosButtonBri 4;
BA_ "GenSigSendType" SG_ 1216 MFLPosButtonFlt 4;
BA_ "GenSigSendType" SG_ 1216 ALSPitchAg 4;
BA_ "GenSigSendType" SG_ 1216 PosButtonVoiceSigSts 4;
BA_ "GenSigSendType" SG_ 1040 SourceNodeIdentifier 2;
BA_ "GenSigSendType" SG_ 1040 RepeatMessageRequestBit 2;
BA_ "GenSigSendType" SG_ 1040 ActiveWakeupBit 2;
BA_ "GenSigSendType" SG_ 1040 RepeatSts 2;
BA_ "GenSigSendType" SG_ 1040 NMReq_Poweron 2;
BA_ "GenSigSendType" SG_ 1040 NMReq_Diag 2;
BA_ "GenSigSendType" SG_ 1040 NMReq_NM 2;
BA_ "GenSigSendType" SG_ 1040 FirstWakeupReason 2;
BA_ "GenSigSendType" SG_ 2015 FuncReq_Data 2;
BA_ "GenSigSendType" SG_ 1841 PhyReq_SCM_Data 2;
BA_ "GenSigSendType" SG_ 1969 Resp_SCM_Data 2;
BA_ "GenSigStartValue" SG_ 1041 MDL_FL_SourceNodeIdentifier 93;
BA_ "GenSigSendType" SG_ 1041 MDL_FL_SourceNodeIdentifier 2;
BA_ "GenSigSendType" SG_ 1041 MDL_FL_RepeatMessageRequestBit 2;
BA_ "GenSigSendType" SG_ 1041 MDL_FL_ActiveWakeupBit 2;
BA_ "GenSigSendType" SG_ 1041 MDL_FL_RepeatSts 2;
BA_ "GenSigSendType" SG_ 1041 MDL_FL_NMReq_Poweron 2;
BA_ "GenSigSendType" SG_ 1041 MDL_FL_NMReq_Diag 2;
BA_ "GenSigSendType" SG_ 1041 MDL_FL_NMReq_NM 2;
BA_ "GenSigSendType" SG_ 1041 MDL_FL_NMReq_WelcomeUpd 2;
BA_ "GenSigSendType" SG_ 1041 MDL_FL_FirstWakeupReason 2;
BA_ "GenSigStartValue" SG_ 1042 MDL_FR_SourceNodeIdentifier 98;
BA_ "GenSigSendType" SG_ 1042 MDL_FR_SourceNodeIdentifier 2;
BA_ "GenSigSendType" SG_ 1042 MDL_FR_RepeatMessageRequestBit 2;
BA_ "GenSigSendType" SG_ 1042 MDL_FR_ActiveWakeupBit 2;
BA_ "GenSigSendType" SG_ 1042 MDL_FR_RepeatSts 2;
BA_ "GenSigSendType" SG_ 1042 MDL_FR_NMReq_Poweron 2;
BA_ "GenSigSendType" SG_ 1042 MDL_FR_NMReq_Diag 2;
BA_ "GenSigSendType" SG_ 1042 MDL_FR_NMReq_NM 2;
BA_ "GenSigSendType" SG_ 1042 MDL_FL_NMReq_WelcomeUpd_2 2;
BA_ "GenSigSendType" SG_ 1042 MDL_FR_FirstWakeupReason 2;
BA_ "GenSigStartValue" SG_ 1344 TimeSync_Month 1;
BA_ "GenSigStartValue" SG_ 1344 TimeSync_Day 1;
VAL_ 288 OpMode 15 " Invalid" 14 " reserved" 13 " reserved" 12 " reserved" 11 " reserved" 10 " reserved" 9 " reserved" 8 " reserved" 7 " reserved" 6 " RemoteDriving" 5 " Remote" 4 " OTA Updating" 3 " Driving" 2 " Convenience" 1 " Inactive" 0 " Abandoned" ;
VAL_ 288 VehMode 15 " Invalid" 14 " Initial" 13 " Reserved" 12 " Reserved" 11 " Reserved" 10 " Reserved" 9 " Reserved" 8 " Reserved" 7 " Reserved" 6 " Reserved" 5 " ExhibitionOutDoor" 4 " ExhibitionInDoor" 3 " Normal" 2 " Dynotest" 1 " Transport" 0 " Factory" ;
VAL_ 288 PwrMode 3 " Invalid" 2 " Reserved" 1 " ON" 0 " OFF" ;
VAL_ 288 FaultFlag 3 " Invalid" 2 " Reserved" 1 " True" 0 " False" ;
VAL_ 528 VolUp_Button 3 " Invalid" 2 " On" 1 " Off" 0 " Initial" ;
VAL_ 528 VolUp_Intensity 7 " Invalid" 3 " Daytime2" 2 " Daytime1" 1 " Night" 0 " Initial" ;
VAL_ 528 VolUp_RampEnable 7 " Invalid" 6 " Reserved" 5 " Reserved" 4 " Reserved" 3 " Enable(Right To Left)" 2 " Enable(Left To Right)" 1 " Disable" 0 " Initial" ;
VAL_ 528 VolDown_Button 3 " Invalid" 2 " On" 1 " Off" 0 " Initial" ;
VAL_ 528 VolDown_Intensity 127 " Invalid" 126 " Reserved" 125 " Reserved" 124 " Reserved" 123 " Reserved" 122 " Reserved" 121 " Reserved" 120 " Reserved" 119 " Reserved" 118 " Reserved" 117 " Reserved" 116 " Reserved" 115 " Reserved" 114 " Reserved" 113 " Reserved" 112 " Reserved" 111 " Reserved" 110 " Reserved" 109 " Reserved" 108 " Reserved" 107 " Reserved" 106 " Reserved" 105 " Reserved" 104 " Reserved" 103 " Reserved" 102 " Reserved" 101 " 100%" 100 " 99%" 1 " 0%" 0 " Initial" ;
VAL_ 528 VolDown_RampEnable 7 " Invalid" 6 " Reserved" 5 " Reserved" 4 " Reserved" 3 " Enable(Right To Left)" 2 " Enable(Left To Right)" 1 " Disable" 0 " Initial" ;
VAL_ 528 Mute_Button 3 " Invalid" 2 " On" 1 " Off" 0 " Initial" ;
VAL_ 528 Mode_Button 3 " Invalid" 2 " On" 1 " Off" 0 " Initial" ;
VAL_ 528 TrackNext_Button 3 " Invalid" 2 " Enable" 1 " Disable" 0 " Initial" ;
VAL_ 528 TrackPrev_Button 15 " Invalid" 5 " Again" 4 " Pause" 3 " On" 2 " Off" 1 " No Request" 0 " Initial" ;
VAL_ 528 Menu_Enter_Button 15 " Invalid" 5 " Again" 4 " Pause" 3 " On" 2 " Off" 1 " No Request" 0 " Initial" ;
VAL_ 528 Menu_Back_Button 15 " Invalid" 14 " Effect 14" 3 " Effect 3" 2 " Effect 2" 1 " Effect 1" 0 " Initial" ;
VAL_ 528 Menu_Up_Button 3 " Invalid" 2 " On" 1 " Off" 0 " Initial" ;
VAL_ 528 Menu_Down_Button 15 " Invalid" 14 " Effect 14" 3 " Effect 3" 2 " Effect 2" 1 " Effect 1" 0 " Initial" ;
VAL_ 528 Menu_Left_Button 3 " Invalid" 2 " On" 1 " Off" 0 " Initial" ;
VAL_ 528 Menu_Right_Button 3 " Invalid" 2 " On" 1 " Off" 0 " Initial" ;
VAL_ 528 Cruise_OnOff 3 " Repeat" 2 " Hold" 1 " Off" 0 " Initial" ;
VAL_ 528 Cruise_Set 3 " Repeat" 2 " Hold" 1 " Off" 0 " Initial" ;
VAL_ 528 Cruise_Resume 7 " Invalid" 2 " Daytime1" 1 " Night" 0 " Initial" ;
VAL_ 528 Cruise_Cancel 3 " Invalid" 2 " On " 1 " Off" 0 " Initial" ;
VAL_ 528 Cruise_Accel 7 " Invalid" 3 " Daytime2" 2 " Daytime1" 1 " Night" 0 " Initial" ;
VAL_ 528 Cruise_Decel 3 " Invalid" 2 " On" 1 " Off" 0 " Initial" ;
VAL_ 528 Phone_Answer 7 " Invalid" 6 " Reserved" 5 " Reserved" 4 " Reserved" 3 " Enable(Right To Left)" 2 " Enable(Left To Right)" 1 " Disable" 0 " Initial" ;
VAL_ 528 Phone_Hangup 7 " Invalid" 4 "��" 3 "�Ͻ�" 2 "��Զ" 1 "?Զ" 0 " Initial" ;
VAL_ 528 Voice_Button 15 " Invalid" 11 "Standby" 10 "Sleep" 9 "active_service" 8 "weather_report" 7 "broadcast" 6 "listen_weakly" 5 "CustomSwitch" 4 "listen" 3 "calling_wake_up " 2 "wake_up" 1 "Exit" 0 "Initial" ;
VAL_ 480 TorqueSensor1 1023 "Invalid" ;
VAL_ 480 TorqueSensor2 1023 "Invalid" ;
VAL_ 480 SteerAngle 16383 "Invalid" ;
VAL_ 480 SteerAngleSpeed 32767 "Invalid" ;
VAL_ 480 VehSpeedValid 1 "Valid" 0 "Invalid" ;
VAL_ 480 VehSpeed 8191 "Invalid" ;
VAL_ 480 RackForce_Left 255 "Invalid" ;
VAL_ 480 RackForce_Right 255 "Invalid" ;
VAL_ 480 RackForce_RearL 255 "Invalid" ;
VAL_ 480 RackForce_RearR 255 "Invalid" ;
VAL_ 480 GearPosition 3 "D" 2 "N" 1 "R" 0 "P" ;
VAL_ 480 GearPosValid 1 "Valid" 0 "Invalid" ;
VAL_ 1216 SteerAngleStatus 3 " Invalid" 2 " On" 1 " Off" 0 " Initial" ;
VAL_ 1216 SteerAngleValid 7 " Invalid" 3 " Daytime2" 2 " Daytime1" 1 " Night" 0 " Initial" ;
VAL_ 1216 SteerAngleFault 7 " Invalid" 6 " Reserved" 5 " Reserved" 4 " Flow Finished" 3 " Flow (Right To Left)" 2 " Flow(Left To Right)" 1 " Disable" 0 " Initial" ;
VAL_ 1216 ClockSpringAngle 3 " Invalid" 2 " Fault" 1 " No Fault" 0 " Initial" ;
VAL_ 1216 ClockSpringFault 3 " Invalid" 2 " On" 1 " Off" 0 " Initial" ;
VAL_ 1216 ReturnLevel 127 " Invalid" 126 " Reserved" 125 " Reserved" 124 " Reserved" 123 " Reserved" 122 " Reserved" 121 " Reserved" 120 " Reserved" 119 " Reserved" 118 " Reserved" 117 " Reserved" 116 " Reserved" 115 " Reserved" 114 " Reserved" 113 " Reserved" 112 " Reserved" 111 " Reserved" 110 " Reserved" 109 " Reserved" 108 " Reserved" 107 " Reserved" 106 " Reserved" 105 " Reserved" 104 " Reserved" 103 " Reserved" 102 " Reserved" 101 " 100%" 100 " 99%" 1 " 0%" 0 " Initial" ;
VAL_ 1216 ReturnFault 7 " Invalid" 6 " Reserved" 5 " Reserved" 4 " Flow Finished" 3 " Flow (Right To Left)" 2 " Flow(Left To Right)" 1 " Disable" 0 " Initial" ;
VAL_ 1216 TiltPosition 3 " Invalid" 2 " On" 1 " Off" 0 " Initial" ;
VAL_ 1216 TiltFault 3 " Invalid" 2 " Fault" 1 " No Fault" 0 " Initial" ;
VAL_ 1216 TelescopePosition 3 " Invalid" 2 " Fault" 1 " No Fault" 0 " Initial" ;
VAL_ 1216 TelescopeFault 3 " Invalid" 2 " On" 1 " Off" 0 " Initial" ;
VAL_ 1216 HeatingStatus 3 " Invalid" 2 " Fault" 1 " No Fault" 0 " Initial" ;
VAL_ 1216 HeatingFault 15 " Invalid" 14 " Effect 14" 3 " Effect 3" 2 " Effect 2" 1 " Effect 1" 0 " Initial" ;
VAL_ 1216 LockStatus 3 " MotorFault" 2 " LockFault" 1 " No Fault" 0 " Initial" ;
VAL_ 1216 LockFault 3 " Fault" 2 " On" 1 " Off" 0 " Initial" ;
VAL_ 1216 CalibrationStatus 15 " Invalid" 14 " Effect 14" 3 " Effect 3" 2 " Effect 2" 1 " Effect 1" 0 " Initial" ;
VAL_ 1216 CalibrationFault 3 " Invalid" 2 " Fault" 1 " No Fault" 0 " Initial" ;
VAL_ 1216 ButtonSwitch_Status 3 " Invalid" 2 " Enable" 1 " Disable" 0 " Initial" ;
VAL_ 1216 ButtonSwitch_Fault 3 " Invalid" 2 " On" 1 " Off" 0 " Initial" ;
VAL_ 1216 AFSFltSt 3 " Invalid" 2 " Fault" 1 " No Fault" 0 " Initial" ;
VAL_ 1216 SteerAssistEffectShowSt 15 " Invalid" 3 " Hold" 2 " Pause" 1 " Running" 0 " OFF" ;
VAL_ 1216 SWCEffectShowSt 15 " Invalid" 3 " Hold" 2 " Pause" 1 " Running" 0 " OFF" ;
VAL_ 1216 FLADSButtonFlt 3 "Invalid" 2 "Fault" 1 "No Fault" 0 "Initial" ;
VAL_ 1216 FLADSButtonBri 7 " Invalid" 2 " Daytime1" 1 " Night" 0 " Initial" ;
VAL_ 1216 FLADSButtonStatus 3 "Invalid" 2 "On " 1 "Off" 0 "Initial" ;
VAL_ 1216 MFLPosButtonStatus 3 " Invalid" 2 " On" 1 " Off" 0 " Initial" ;
VAL_ 1216 MFLPosButtonFlowStatus 7 " Invalid" 6 " Reserved" 5 " Reserved" 4 " Flow Finished" 3 " Flow (Right To Left)" 2 " Flow(Left To Right)" 1 " Disable" 0 " Initial" ;
VAL_ 1216 MFLPosButtonBri 7 " Invalid" 3 " Daytime2" 2 " Daytime1" 1 " Night" 0 " Initial" ;
VAL_ 1216 MFLPosButtonFlt 3 " Invalid" 2 " Fault" 1 " No Fault" 0 " Initial" ;
VAL_ 1216 ALSPitchAg 63 " Invalid" 60 " 2.0" 59 " 1.9" 1 " -3.9" 0 " -4.0" ;
VAL_ 1216 PosButtonVoiceSigSts 15 " Invalid" 11 "Standby" 10 "Sleep" 9 "active_service" 8 "weather_report" 7 "broadcast" 6 "listen_weakly" 5 "CustomSwitch" 4 "listen" 3 "calling_wake_up " 2 "wake_up" 1 "Exit" 0 "Initial" ;
VAL_ 1040 RepeatMessageRequestBit 1 "�ñ��ķ��ͽڵ����������ڵ�����ظ�����״̬" 0 "�ñ��ķ��ͽڵ�δ���������ڵ�����ظ�����״̬" ;
VAL_ 1040 ActiveWakeupBit 1 "�ñ��ķ��ͽڵ�������������" 0 "�ñ��ķ��ͽڵ�δ�����������磨�������ڵ㻽�ѣ�" ;
VAL_ 1040 RepeatSts 1 "�ڵ㴦���ظ�����״̬" 0 "�ڵ㲻���ظ�����״̬" ;
VAL_ 1040 NMReq_Poweron 1 " Active" 0 " Inactive" ;
VAL_ 1040 NMReq_Diag 1 " Active" 0 " Inactive" ;
VAL_ 1040 NMReq_NM 1 " Active" 0 " Inactive" ;
VAL_ 1040 FirstWakeupReason 63 " Invalid" 2 " NM����" 1 " ����Ӳ��ON" 0 " Initial" ;
VAL_ 848 ExtInput_CRC 1 "Valid" 0 "Invalid" ;
VAL_ 848 ExtInput_RollCnt 8191 "Invalid" ;
VAL_ 848 LinBus_Status 1048575 "Invalid" ;
VAL_ 848 GearPos_2 3 "D" 2 "N" 1 "R" 0 "P" ;
VAL_ 848 GearPosValid_2 1 "Valid" 0 "Invalid" ;
VAL_ 336 Media1_CRC 15 " Not Available" 14 " Initating" 13 " Reserved" 12 " Reserved" 11 " Reserved" 10 " Reserved" 9 " Reserved" 8 " Reserved" 7 " Reserved" 6 " Reserved" 5 " Reserved" 4 " Off" 3 " On Faliure" 2 " On Reduced Sight" 1 " On Active" 0 " On Passive" ;
VAL_ 336 Media1_RollCnt 15 " Not Available" 14 " Initating" 13 " Reserved" 12 " Reserved" 11 " >10 Object Detected" 10 " 10 Object Detected" 9 " 9 Object Detected" 8 " 8 Object Detected" 7 " 7 Object Detected" 6 " 6 Object Detected" 5 " 5 Object Detected" 4 " 4 Object Detected" 3 " 3 Object Detected" 2 " 2 Object Detected" 1 " 1 Object Detected" 0 " No Object Detected" ;
VAL_ 336 DisplayBrightness 15 " Not Available" 14 " Initating" 13 " Reserved" 12 " Reserved" 11 " Reserved" 10 " Reserved" 9 " Reserved" 8 " Reserved" 7 " Reserved" 6 " Reserved" 5 " Reserved" 4 " Reserved" 3 " Night without Road Button" 2 " Night with Road Button" 1 " Day" 0 " No Object Detected" ;
VAL_ 336 DisplayContrast 15 " Not Available" 14 " Initating" 13 " Reserved" 12 " Reserved" 11 " Reserved" 10 " Reserved" 9 " Reserved" 8 " Reserved" 7 " Reserved" 6 " Reserved" 5 " Reserved" 4 " Reserved" 3 " Reserved" 2 " Left Hand Traffic" 1 " Right Hand Traffic" 0 " Unknow" ;
VAL_ 336 BackswitchLevel 63 " Not Available" 62 " Initating" 0 " No Object" ;
VAL_ 336 BackswitchAuto 12 " β��˫��" 11 " β�Ƶ���" 10 " ǰ��˫��" 9 " ǰ�Ƶ���" 8 " Unknown" 7 " Billboard" 6 " Mixed" 5 " Pedestrain" 4 " Bike" 3 " Bus" 2 " Truck" 1 " Car" 0 " NoVehicle" ;
VAL_ 336 TouchValid 2047 "reserved" 2046 "reserved" 2045 "reserved" 2044 "reserved" 2043 "reserved" 2042 "reserved" 2041 "reserved" 2040 "reserved" 2039 "reserved" 2038 "reserved" 2037 "reserved" 2036 "reserved" 2035 "reserved" 2034 "reserved" 2033 "reserved" 2032 "reserved" 2031 "reserved" 2030 "reserved" 2029 "reserved" 2028 "reserved" 2027 "reserved" 2026 "reserved" 2025 "reserved" 2024 "reserved" 2023 "reserved" 2022 "reserved" 2021 "reserved" 2020 "reserved" 2019 "reserved" 2018 "reserved" 2017 "reserved" 2016 "reserved" 2015 "reserved" 2014 "reserved" 2013 "reserved" 2012 "reserved" 2011 "reserved" 2010 "reserved" 2009 "reserved" 2008 "reserved" 2007 "reserved" 2006 "reserved" 2005 "reserved" 2004 "reserved" 2003 "reserved" 2002 "reserved" 2001 "reserved" 2000 "reserved" 1999 "reserved" 1998 "reserved" 1997 "reserved" 1996 "reserved" 1995 "reserved" 1994 "reserved" 1993 "reserved" 1992 "reserved" 1991 "reserved" 1990 "reserved" 1989 "reserved" 1988 "reserved" 1987 "reserved" 1986 "reserved" 1985 "reserved" 1984 "reserved" 1983 "reserved" 1982 "reserved" 1981 "reserved" 1980 "reserved" 1979 "reserved" 1978 "reserved" 1977 "reserved" 1976 "reserved" 1975 "reserved" 1974 "reserved" 1973 "reserved" 1972 "reserved" 1971 "reserved" 1970 "reserved" 1969 "reserved" 1968 "reserved" 1967 "reserved" 1966 "reserved" 1965 "reserved" 1964 "reserved" 1963 "reserved" 1962 "reserved" 1961 "reserved" 1960 "reserved" 1959 "reserved" 1958 "reserved" 1957 "reserved" 1956 "reserved" 1955 "reserved" 1954 "reserved" 1953 "reserved" 1952 "reserved" 1951 "reserved" 1950 "reserved" 1949 "reserved" 1948 "reserved" 1947 "reserved" 1946 "reserved" 1945 "reserved" 1944 "reserved" 1943 "reserved" 1942 "reserved" 1941 "reserved" 1940 "reserved" 1939 "reserved" 1938 "reserved" 1937 "reserved" 1936 "reserved" 1935 "reserved" 1934 "reserved" 1933 "reserved" 1932 "reserved" 1931 "reserved" 1930 "reserved" 1929 "reserved" 1928 "reserved" 1927 "reserved" 1926 "reserved" 1925 "reserved" 1924 "reserved" 1923 "reserved" 1922 "reserved" 1921 "reserved" 1920 "reserved" 1919 "reserved" 1918 "reserved" 1917 "reserved" 1916 "reserved" 1915 "reserved" 1914 "reserved" 1913 "reserved" 1912 "reserved" 1911 "reserved" 1910 "reserved" 1909 "reserved" 1908 "reserved" 1907 "reserved" 1906 "reserved" 1905 "reserved" 1904 "reserved" 1903 "reserved" 1902 "reserved" 1901 "reserved" 1900 "reserved" 1899 "reserved" 1898 "reserved" 1897 "reserved" 1896 "reserved" 1895 "reserved" 1894 "reserved" 1893 "reserved" 1892 "reserved" 1891 "reserved" 1890 "reserved" 1889 "reserved" 1888 "reserved" 1887 "reserved" 1886 "reserved" 1885 "reserved" 1884 "reserved" 1883 "reserved" 1882 "reserved" 1881 "reserved" 1880 "reserved" 1879 "reserved" 1878 "reserved" 1877 "reserved" 1876 "reserved" 1875 "reserved" 1874 "reserved" 1873 "reserved" 1872 "reserved" 1871 "reserved" 1870 "reserved" 1869 "reserved" 1868 "reserved" 1867 "reserved" 1866 "reserved" 1865 "reserved" 1864 "reserved" 1863 "reserved" 1862 "reserved" 1861 "reserved" 1860 "reserved" 1859 "reserved" 1858 "reserved" 1857 "reserved" 1856 "reserved" 1855 "reserved" 1854 "reserved" 1853 "reserved" 1852 "reserved" 1851 "reserved" 1850 "reserved" 1849 "reserved" 1848 "reserved" 1847 "reserved" 1846 "reserved" 1845 "reserved" 1844 "reserved" 1843 "reserved" 1842 "reserved" 1841 "reserved" 1840 "reserved" 1839 "reserved" 1838 "reserved" 1837 "reserved" 1836 "reserved" 1835 "reserved" 1834 "reserved" 1833 "reserved" 1832 "reserved" 1831 "reserved" 1830 "reserved" 1829 "reserved" 1828 "reserved" 1827 "reserved" 1826 "reserved" 1825 "reserved" 1824 "reserved" 1823 "reserved" 1822 "reserved" 1821 "reserved" 1820 "reserved" 1819 "reserved" 1818 "reserved" 1817 "reserved" 1816 "reserved" 1815 "reserved" 1814 "reserved" 1813 "reserved" 1812 "reserved" 1811 "reserved" 1810 "reserved" 1809 "reserved" 1808 "reserved" 1807 "reserved" 1806 "reserved" 1805 "reserved" 1804 "reserved" 1803 "reserved" 1802 "reserved" 1801 "reserved" 1800 "reserved" 1799 "reserved" 1798 "reserved" 1797 "reserved" 1796 "reserved" 1795 "reserved" 1794 "reserved" 1793 "reserved" 1792 "reserved" 1791 "reserved" 1790 "reserved" 1789 "reserved" 1788 "reserved" 1787 "reserved" 1786 "reserved" 1785 "reserved" 1784 "reserved" 1783 "reserved" 1782 "reserved" 1781 "reserved" 1780 "reserved" 1779 "reserved" 1778 "reserved" 1777 "reserved" 1776 "reserved" 1775 "reserved" 1774 "reserved" 1773 "reserved" 1772 "reserved" 1771 "reserved" 1770 "reserved" 1769 "reserved" 1768 "reserved" 1767 "reserved" 1766 "reserved" 1765 "reserved" 1764 "reserved" 1763 "reserved" 1762 "reserved" 1761 "reserved" 1760 "reserved" 1759 "reserved" 1758 "reserved" 1757 "reserved" 1756 "reserved" 1755 "reserved" 1754 "reserved" 1753 "reserved" 1752 "reserved" 1751 "reserved" 1750 "reserved" 1749 "reserved" 1748 "reserved" 1747 "reserved" 1746 "reserved" 1745 "reserved" 1744 "reserved" 1743 "reserved" 1742 "reserved" 1741 "reserved" 1740 "reserved" 1739 "reserved" 1738 "reserved" 1737 "reserved" 1736 "reserved" 1735 "reserved" 1734 "reserved" 1733 "reserved" 1732 "reserved" 1731 "reserved" 1730 "reserved" 1729 "reserved" 1728 "reserved" 1727 "reserved" 1726 "reserved" 1725 "reserved" 1724 "reserved" 1723 "reserved" 1722 "reserved" 1721 "reserved" 1720 "reserved" 1719 "reserved" 1718 "reserved" 1717 "reserved" 1716 "reserved" 1715 "reserved" 1714 "reserved" 1713 "reserved" 1712 "reserved" 1711 "reserved" 1710 "reserved" 1709 "reserved" 1708 "reserved" 1707 "reserved" 1706 "reserved" 1705 "reserved" 1704 "reserved" 1703 "reserved" 1702 "reserved" 1701 "reserved" 1700 "reserved" 1699 "reserved" 1698 "reserved" 1697 "reserved" 1696 "reserved" 1695 "reserved" 1694 "reserved" 1693 "reserved" 1692 "reserved" 1691 "reserved" 1690 "reserved" 1689 "reserved" 1688 "reserved" 1687 "reserved" 1686 "reserved" 1685 "reserved" 1684 "reserved" 1683 "reserved" 1682 "reserved" 1681 "reserved" 1680 "reserved" 1679 "reserved" 1678 "reserved" 1677 "reserved" 1676 "reserved" 1675 "reserved" 1674 "reserved" 1673 "reserved" 1672 "reserved" 1671 "reserved" 1670 "reserved" 1669 "reserved" 1668 "reserved" 1667 "reserved" 1666 "reserved" 1665 "reserved" 1664 "reserved" 1663 "reserved" 1662 "reserved" 1661 "reserved" 1660 "reserved" 1659 "reserved" 1658 "reserved" 1657 "reserved" 1656 "reserved" 1655 "reserved" 1654 "reserved" 1653 "reserved" 1652 "reserved" 1651 "reserved" 1650 "reserved" 1649 "reserved" 1648 "reserved" 1647 "reserved" 1646 "reserved" 1645 "reserved" 1644 "reserved" 1643 "reserved" 1642 "reserved" 1641 "reserved" 1640 "reserved" 1639 "reserved" 1638 "reserved" 1637 "reserved" 1636 "reserved" 1635 "reserved" 1634 "reserved" 1633 "reserved" 1632 "reserved" 1631 "reserved" 1630 "reserved" 1629 "reserved" 1628 "reserved" 1627 "reserved" 1626 "reserved" 1625 "reserved" 1624 "reserved" 1623 "reserved" 1622 "reserved" 1621 "reserved" 1620 "reserved" 1619 "reserved" 1618 "reserved" 1617 "reserved" 1616 "reserved" 1615 "reserved" 1614 "reserved" 1613 "reserved" 1612 "reserved" 1611 "reserved" 1610 "reserved" 1609 "reserved" 1608 "reserved" 1607 "reserved" 1606 "reserved" 1605 "reserved" 1604 "reserved" 1603 "reserved" 1602 "reserved" 1601 "reserved" ;
VAL_ 336 GestureDetect 2047 "reserved" 2046 "reserved" 2045 "reserved" 2044 "reserved" 2043 "reserved" 2042 "reserved" 2041 "reserved" 2040 "reserved" 2039 "reserved" 2038 "reserved" 2037 "reserved" 2036 "reserved" 2035 "reserved" 2034 "reserved" 2033 "reserved" 2032 "reserved" 2031 "reserved" 2030 "reserved" 2029 "reserved" 2028 "reserved" 2027 "reserved" 2026 "reserved" 2025 "reserved" 2024 "reserved" 2023 "reserved" 2022 "reserved" 2021 "reserved" 2020 "reserved" 2019 "reserved" 2018 "reserved" 2017 "reserved" 2016 "reserved" 2015 "reserved" 2014 "reserved" 2013 "reserved" 2012 "reserved" 2011 "reserved" 2010 "reserved" 2009 "reserved" 2008 "reserved" 2007 "reserved" 2006 "reserved" 2005 "reserved" 2004 "reserved" 2003 "reserved" 2002 "reserved" 2001 "reserved" 2000 "reserved" 1999 "reserved" 1998 "reserved" 1997 "reserved" 1996 "reserved" 1995 "reserved" 1994 "reserved" 1993 "reserved" 1992 "reserved" 1991 "reserved" 1990 "reserved" 1989 "reserved" 1988 "reserved" 1987 "reserved" 1986 "reserved" 1985 "reserved" 1984 "reserved" 1983 "reserved" 1982 "reserved" 1981 "reserved" 1980 "reserved" 1979 "reserved" 1978 "reserved" 1977 "reserved" 1976 "reserved" 1975 "reserved" 1974 "reserved" 1973 "reserved" 1972 "reserved" 1971 "reserved" 1970 "reserved" 1969 "reserved" 1968 "reserved" 1967 "reserved" 1966 "reserved" 1965 "reserved" 1964 "reserved" 1963 "reserved" 1962 "reserved" 1961 "reserved" 1960 "reserved" 1959 "reserved" 1958 "reserved" 1957 "reserved" 1956 "reserved" 1955 "reserved" 1954 "reserved" 1953 "reserved" 1952 "reserved" 1951 "reserved" 1950 "reserved" 1949 "reserved" 1948 "reserved" 1947 "reserved" 1946 "reserved" 1945 "reserved" 1944 "reserved" 1943 "reserved" 1942 "reserved" 1941 "reserved" 1940 "reserved" 1939 "reserved" 1938 "reserved" 1937 "reserved" 1936 "reserved" 1935 "reserved" 1934 "reserved" 1933 "reserved" 1932 "reserved" 1931 "reserved" 1930 "reserved" 1929 "reserved" 1928 "reserved" 1927 "reserved" 1926 "reserved" 1925 "reserved" 1924 "reserved" 1923 "reserved" 1922 "reserved" 1921 "reserved" 1920 "reserved" 1919 "reserved" 1918 "reserved" 1917 "reserved" 1916 "reserved" 1915 "reserved" 1914 "reserved" 1913 "reserved" 1912 "reserved" 1911 "reserved" 1910 "reserved" 1909 "reserved" 1908 "reserved" 1907 "reserved" 1906 "reserved" 1905 "reserved" 1904 "reserved" 1903 "reserved" 1902 "reserved" 1901 "reserved" 1900 "reserved" 1899 "reserved" 1898 "reserved" 1897 "reserved" 1896 "reserved" 1895 "reserved" 1894 "reserved" 1893 "reserved" 1892 "reserved" 1891 "reserved" 1890 "reserved" 1889 "reserved" 1888 "reserved" 1887 "reserved" 1886 "reserved" 1885 "reserved" 1884 "reserved" 1883 "reserved" 1882 "reserved" 1881 "reserved" 1880 "reserved" 1879 "reserved" 1878 "reserved" 1877 "reserved" 1876 "reserved" 1875 "reserved" 1874 "reserved" 1873 "reserved" 1872 "reserved" 1871 "reserved" 1870 "reserved" 1869 "reserved" 1868 "reserved" 1867 "reserved" 1866 "reserved" 1865 "reserved" 1864 "reserved" 1863 "reserved" 1862 "reserved" 1861 "reserved" 1860 "reserved" 1859 "reserved" 1858 "reserved" 1857 "reserved" 1856 "reserved" 1855 "reserved" 1854 "reserved" 1853 "reserved" 1852 "reserved" 1851 "reserved" 1850 "reserved" 1849 "reserved" 1848 "reserved" 1847 "reserved" 1846 "reserved" 1845 "reserved" 1844 "reserved" 1843 "reserved" 1842 "reserved" 1841 "reserved" 1840 "reserved" 1839 "reserved" 1838 "reserved" 1837 "reserved" 1836 "reserved" 1835 "reserved" 1834 "reserved" 1833 "reserved" 1832 "reserved" 1831 "reserved" 1830 "reserved" 1829 "reserved" 1828 "reserved" 1827 "reserved" 1826 "reserved" 1825 "reserved" 1824 "reserved" 1823 "reserved" 1822 "reserved" 1821 "reserved" 1820 "reserved" 1819 "reserved" 1818 "reserved" 1817 "reserved" 1816 "reserved" 1815 "reserved" 1814 "reserved" 1813 "reserved" 1812 "reserved" 1811 "reserved" 1810 "reserved" 1809 "reserved" 1808 "reserved" 1807 "reserved" 1806 "reserved" 1805 "reserved" 1804 "reserved" 1803 "reserved" 1802 "reserved" 1801 "reserved" 1800 "reserved" 1799 "reserved" 1798 "reserved" 1797 "reserved" 1796 "reserved" 1795 "reserved" 1794 "reserved" 1793 "reserved" 1792 "reserved" 1791 "reserved" 1790 "reserved" 1789 "reserved" 1788 "reserved" 1787 "reserved" 1786 "reserved" 1785 "reserved" 1784 "reserved" 1783 "reserved" 1782 "reserved" 1781 "reserved" 1780 "reserved" 1779 "reserved" 1778 "reserved" 1777 "reserved" 1776 "reserved" 1775 "reserved" 1774 "reserved" 1773 "reserved" 1772 "reserved" 1771 "reserved" 1770 "reserved" 1769 "reserved" 1768 "reserved" 1767 "reserved" 1766 "reserved" 1765 "reserved" 1764 "reserved" 1763 "reserved" 1762 "reserved" 1761 "reserved" 1760 "reserved" 1759 "reserved" 1758 "reserved" 1757 "reserved" 1756 "reserved" 1755 "reserved" 1754 "reserved" 1753 "reserved" 1752 "reserved" 1751 "reserved" 1750 "reserved" 1749 "reserved" 1748 "reserved" 1747 "reserved" 1746 "reserved" 1745 "reserved" 1744 "reserved" 1743 "reserved" 1742 "reserved" 1741 "reserved" 1740 "reserved" 1739 "reserved" 1738 "reserved" 1737 "reserved" 1736 "reserved" 1735 "reserved" 1734 "reserved" 1733 "reserved" 1732 "reserved" 1731 "reserved" 1730 "reserved" 1729 "reserved" 1728 "reserved" 1727 "reserved" 1726 "reserved" 1725 "reserved" 1724 "reserved" 1723 "reserved" 1722 "reserved" 1721 "reserved" 1720 "reserved" 1719 "reserved" 1718 "reserved" 1717 "reserved" 1716 "reserved" 1715 "reserved" 1714 "reserved" 1713 "reserved" 1712 "reserved" 1711 "reserved" 1710 "reserved" 1709 "reserved" 1708 "reserved" 1707 "reserved" 1706 "reserved" 1705 "reserved" 1704 "reserved" 1703 "reserved" 1702 "reserved" 1701 "reserved" 1700 "reserved" 1699 "reserved" 1698 "reserved" 1697 "reserved" 1696 "reserved" 1695 "reserved" 1694 "reserved" 1693 "reserved" 1692 "reserved" 1691 "reserved" 1690 "reserved" 1689 "reserved" 1688 "reserved" 1687 "reserved" 1686 "reserved" 1685 "reserved" 1684 "reserved" 1683 "reserved" 1682 "reserved" 1681 "reserved" 1680 "reserved" 1679 "reserved" 1678 "reserved" 1677 "reserved" 1676 "reserved" 1675 "reserved" 1674 "reserved" 1673 "reserved" 1672 "reserved" 1671 "reserved" 1670 "reserved" 1669 "reserved" 1668 "reserved" 1667 "reserved" 1666 "reserved" 1665 "reserved" 1664 "reserved" 1663 "reserved" 1662 "reserved" 1661 "reserved" 1660 "reserved" 1659 "reserved" 1658 "reserved" 1657 "reserved" 1656 "reserved" 1655 "reserved" 1654 "reserved" 1653 "reserved" 1652 "reserved" 1651 "reserved" 1650 "reserved" 1649 "reserved" 1648 "reserved" 1647 "reserved" 1646 "reserved" 1645 "reserved" 1644 "reserved" 1643 "reserved" 1642 "reserved" 1641 "reserved" 1640 "reserved" 1639 "reserved" 1638 "reserved" 1637 "reserved" 1636 "reserved" 1635 "reserved" 1634 "reserved" 1633 "reserved" 1632 "reserved" 1631 "reserved" 1630 "reserved" 1629 "reserved" 1628 "reserved" 1627 "reserved" 1626 "reserved" 1625 "reserved" 1624 "reserved" 1623 "reserved" 1622 "reserved" 1621 "reserved" 1620 "reserved" 1619 "reserved" 1618 "reserved" 1617 "reserved" 1616 "reserved" 1615 "reserved" 1614 "reserved" 1613 "reserved" 1612 "reserved" 1611 "reserved" 1610 "reserved" 1609 "reserved" 1608 "reserved" 1607 "reserved" 1606 "reserved" 1605 "reserved" 1604 "reserved" 1603 "reserved" 1602 "reserved" 1601 "reserved" ;
VAL_ 336 GestureType 1023 "reserved" 1022 "reserved" 1021 "reserved" 1020 "reserved" 1019 "reserved" 1018 "reserved" 1017 "reserved" 1016 "reserved" 1015 "reserved" 1014 "reserved" 1013 "reserved" 1012 "reserved" 1011 "reserved" 1010 "reserved" 1009 "reserved" 1008 "reserved" 1007 "reserved" 1006 "reserved" 1005 "reserved" 1004 "reserved" 1003 "reserved" 1002 "reserved" 1001 "reserved" ;
VAL_ 336 ProximityDetect 3 "Others" 2 "Preceding" 1 "Oncoming" 0 "Idle" ;
VAL_ 336 AmbientSwitch_Left 63 " Not Available" 62 " Initating" 0 " No Object" ;
VAL_ 336 AmbientSwitch_Right 12 " β��˫��" 11 " β�Ƶ���" 10 " ǰ��˫��" 9 " ǰ�Ƶ���" 8 " Unknown" 7 " Billboard" 6 " Mixed" 5 " Pedestrain" 4 " Bike" 3 " Bus" 2 " Truck" 1 " Car" 0 " NoVehicle" ;
VAL_ 336 ColorTemp_G 2047 "reserved" 2046 "reserved" 2045 "reserved" 2044 "reserved" 2043 "reserved" 2042 "reserved" 2041 "reserved" 2040 "reserved" 2039 "reserved" 2038 "reserved" 2037 "reserved" 2036 "reserved" 2035 "reserved" 2034 "reserved" 2033 "reserved" 2032 "reserved" 2031 "reserved" 2030 "reserved" 2029 "reserved" 2028 "reserved" 2027 "reserved" 2026 "reserved" 2025 "reserved" 2024 "reserved" 2023 "reserved" 2022 "reserved" 2021 "reserved" 2020 "reserved" 2019 "reserved" 2018 "reserved" 2017 "reserved" 2016 "reserved" 2015 "reserved" 2014 "reserved" 2013 "reserved" 2012 "reserved" 2011 "reserved" 2010 "reserved" 2009 "reserved" 2008 "reserved" 2007 "reserved" 2006 "reserved" 2005 "reserved" 2004 "reserved" 2003 "reserved" 2002 "reserved" 2001 "reserved" 2000 "reserved" 1999 "reserved" 1998 "reserved" 1997 "reserved" 1996 "reserved" 1995 "reserved" 1994 "reserved" 1993 "reserved" 1992 "reserved" 1991 "reserved" 1990 "reserved" 1989 "reserved" 1988 "reserved" 1987 "reserved" 1986 "reserved" 1985 "reserved" 1984 "reserved" 1983 "reserved" 1982 "reserved" 1981 "reserved" 1980 "reserved" 1979 "reserved" 1978 "reserved" 1977 "reserved" 1976 "reserved" 1975 "reserved" 1974 "reserved" 1973 "reserved" 1972 "reserved" 1971 "reserved" 1970 "reserved" 1969 "reserved" 1968 "reserved" 1967 "reserved" 1966 "reserved" 1965 "reserved" 1964 "reserved" 1963 "reserved" 1962 "reserved" 1961 "reserved" 1960 "reserved" 1959 "reserved" 1958 "reserved" 1957 "reserved" 1956 "reserved" 1955 "reserved" 1954 "reserved" 1953 "reserved" 1952 "reserved" 1951 "reserved" 1950 "reserved" 1949 "reserved" 1948 "reserved" 1947 "reserved" 1946 "reserved" 1945 "reserved" 1944 "reserved" 1943 "reserved" 1942 "reserved" 1941 "reserved" 1940 "reserved" 1939 "reserved" 1938 "reserved" 1937 "reserved" 1936 "reserved" 1935 "reserved" 1934 "reserved" 1933 "reserved" 1932 "reserved" 1931 "reserved" 1930 "reserved" 1929 "reserved" 1928 "reserved" 1927 "reserved" 1926 "reserved" 1925 "reserved" 1924 "reserved" 1923 "reserved" 1922 "reserved" 1921 "reserved" 1920 "reserved" 1919 "reserved" 1918 "reserved" 1917 "reserved" 1916 "reserved" 1915 "reserved" 1914 "reserved" 1913 "reserved" 1912 "reserved" 1911 "reserved" 1910 "reserved" 1909 "reserved" 1908 "reserved" 1907 "reserved" 1906 "reserved" 1905 "reserved" 1904 "reserved" 1903 "reserved" 1902 "reserved" 1901 "reserved" 1900 "reserved" 1899 "reserved" 1898 "reserved" 1897 "reserved" 1896 "reserved" 1895 "reserved" 1894 "reserved" 1893 "reserved" 1892 "reserved" 1891 "reserved" 1890 "reserved" 1889 "reserved" 1888 "reserved" 1887 "reserved" 1886 "reserved" 1885 "reserved" 1884 "reserved" 1883 "reserved" 1882 "reserved" 1881 "reserved" 1880 "reserved" 1879 "reserved" 1878 "reserved" 1877 "reserved" 1876 "reserved" 1875 "reserved" 1874 "reserved" 1873 "reserved" 1872 "reserved" 1871 "reserved" 1870 "reserved" 1869 "reserved" 1868 "reserved" 1867 "reserved" 1866 "reserved" 1865 "reserved" 1864 "reserved" 1863 "reserved" 1862 "reserved" 1861 "reserved" 1860 "reserved" 1859 "reserved" 1858 "reserved" 1857 "reserved" 1856 "reserved" 1855 "reserved" 1854 "reserved" 1853 "reserved" 1852 "reserved" 1851 "reserved" 1850 "reserved" 1849 "reserved" 1848 "reserved" 1847 "reserved" 1846 "reserved" 1845 "reserved" 1844 "reserved" 1843 "reserved" 1842 "reserved" 1841 "reserved" 1840 "reserved" 1839 "reserved" 1838 "reserved" 1837 "reserved" 1836 "reserved" 1835 "reserved" 1834 "reserved" 1833 "reserved" 1832 "reserved" 1831 "reserved" 1830 "reserved" 1829 "reserved" 1828 "reserved" 1827 "reserved" 1826 "reserved" 1825 "reserved" 1824 "reserved" 1823 "reserved" 1822 "reserved" 1821 "reserved" 1820 "reserved" 1819 "reserved" 1818 "reserved" 1817 "reserved" 1816 "reserved" 1815 "reserved" 1814 "reserved" 1813 "reserved" 1812 "reserved" 1811 "reserved" 1810 "reserved" 1809 "reserved" 1808 "reserved" 1807 "reserved" 1806 "reserved" 1805 "reserved" 1804 "reserved" 1803 "reserved" 1802 "reserved" 1801 "reserved" 1800 "reserved" 1799 "reserved" 1798 "reserved" 1797 "reserved" 1796 "reserved" 1795 "reserved" 1794 "reserved" 1793 "reserved" 1792 "reserved" 1791 "reserved" 1790 "reserved" 1789 "reserved" 1788 "reserved" 1787 "reserved" 1786 "reserved" 1785 "reserved" 1784 "reserved" 1783 "reserved" 1782 "reserved" 1781 "reserved" 1780 "reserved" 1779 "reserved" 1778 "reserved" 1777 "reserved" 1776 "reserved" 1775 "reserved" 1774 "reserved" 1773 "reserved" 1772 "reserved" 1771 "reserved" 1770 "reserved" 1769 "reserved" 1768 "reserved" 1767 "reserved" 1766 "reserved" 1765 "reserved" 1764 "reserved" 1763 "reserved" 1762 "reserved" 1761 "reserved" 1760 "reserved" 1759 "reserved" 1758 "reserved" 1757 "reserved" 1756 "reserved" 1755 "reserved" 1754 "reserved" 1753 "reserved" 1752 "reserved" 1751 "reserved" 1750 "reserved" 1749 "reserved" 1748 "reserved" 1747 "reserved" 1746 "reserved" 1745 "reserved" 1744 "reserved" 1743 "reserved" 1742 "reserved" 1741 "reserved" 1740 "reserved" 1739 "reserved" 1738 "reserved" 1737 "reserved" 1736 "reserved" 1735 "reserved" 1734 "reserved" 1733 "reserved" 1732 "reserved" 1731 "reserved" 1730 "reserved" 1729 "reserved" 1728 "reserved" 1727 "reserved" 1726 "reserved" 1725 "reserved" 1724 "reserved" 1723 "reserved" 1722 "reserved" 1721 "reserved" 1720 "reserved" 1719 "reserved" 1718 "reserved" 1717 "reserved" 1716 "reserved" 1715 "reserved" 1714 "reserved" 1713 "reserved" 1712 "reserved" 1711 "reserved" 1710 "reserved" 1709 "reserved" 1708 "reserved" 1707 "reserved" 1706 "reserved" 1705 "reserved" 1704 "reserved" 1703 "reserved" 1702 "reserved" 1701 "reserved" 1700 "reserved" 1699 "reserved" 1698 "reserved" 1697 "reserved" 1696 "reserved" 1695 "reserved" 1694 "reserved" 1693 "reserved" 1692 "reserved" 1691 "reserved" 1690 "reserved" 1689 "reserved" 1688 "reserved" 1687 "reserved" 1686 "reserved" 1685 "reserved" 1684 "reserved" 1683 "reserved" 1682 "reserved" 1681 "reserved" 1680 "reserved" 1679 "reserved" 1678 "reserved" 1677 "reserved" 1676 "reserved" 1675 "reserved" 1674 "reserved" 1673 "reserved" 1672 "reserved" 1671 "reserved" 1670 "reserved" 1669 "reserved" 1668 "reserved" 1667 "reserved" 1666 "reserved" 1665 "reserved" 1664 "reserved" 1663 "reserved" 1662 "reserved" 1661 "reserved" 1660 "reserved" 1659 "reserved" 1658 "reserved" 1657 "reserved" 1656 "reserved" 1655 "reserved" 1654 "reserved" 1653 "reserved" 1652 "reserved" 1651 "reserved" 1650 "reserved" 1649 "reserved" 1648 "reserved" 1647 "reserved" 1646 "reserved" 1645 "reserved" 1644 "reserved" 1643 "reserved" 1642 "reserved" 1641 "reserved" 1640 "reserved" 1639 "reserved" 1638 "reserved" 1637 "reserved" 1636 "reserved" 1635 "reserved" 1634 "reserved" 1633 "reserved" 1632 "reserved" 1631 "reserved" 1630 "reserved" 1629 "reserved" 1628 "reserved" 1627 "reserved" 1626 "reserved" 1625 "reserved" 1624 "reserved" 1623 "reserved" 1622 "reserved" 1621 "reserved" 1620 "reserved" 1619 "reserved" 1618 "reserved" 1617 "reserved" 1616 "reserved" 1615 "reserved" 1614 "reserved" 1613 "reserved" 1612 "reserved" 1611 "reserved" 1610 "reserved" 1609 "reserved" 1608 "reserved" 1607 "reserved" 1606 "reserved" 1605 "reserved" 1604 "reserved" 1603 "reserved" 1602 "reserved" 1601 "reserved" ;
VAL_ 336 ColorTemp_B 2047 "reserved" 2046 "reserved" 2045 "reserved" 2044 "reserved" 2043 "reserved" 2042 "reserved" 2041 "reserved" 2040 "reserved" 2039 "reserved" 2038 "reserved" 2037 "reserved" 2036 "reserved" 2035 "reserved" 2034 "reserved" 2033 "reserved" 2032 "reserved" 2031 "reserved" 2030 "reserved" 2029 "reserved" 2028 "reserved" 2027 "reserved" 2026 "reserved" 2025 "reserved" 2024 "reserved" 2023 "reserved" 2022 "reserved" 2021 "reserved" 2020 "reserved" 2019 "reserved" 2018 "reserved" 2017 "reserved" 2016 "reserved" 2015 "reserved" 2014 "reserved" 2013 "reserved" 2012 "reserved" 2011 "reserved" 2010 "reserved" 2009 "reserved" 2008 "reserved" 2007 "reserved" 2006 "reserved" 2005 "reserved" 2004 "reserved" 2003 "reserved" 2002 "reserved" 2001 "reserved" 2000 "reserved" 1999 "reserved" 1998 "reserved" 1997 "reserved" 1996 "reserved" 1995 "reserved" 1994 "reserved" 1993 "reserved" 1992 "reserved" 1991 "reserved" 1990 "reserved" 1989 "reserved" 1988 "reserved" 1987 "reserved" 1986 "reserved" 1985 "reserved" 1984 "reserved" 1983 "reserved" 1982 "reserved" 1981 "reserved" 1980 "reserved" 1979 "reserved" 1978 "reserved" 1977 "reserved" 1976 "reserved" 1975 "reserved" 1974 "reserved" 1973 "reserved" 1972 "reserved" 1971 "reserved" 1970 "reserved" 1969 "reserved" 1968 "reserved" 1967 "reserved" 1966 "reserved" 1965 "reserved" 1964 "reserved" 1963 "reserved" 1962 "reserved" 1961 "reserved" 1960 "reserved" 1959 "reserved" 1958 "reserved" 1957 "reserved" 1956 "reserved" 1955 "reserved" 1954 "reserved" 1953 "reserved" 1952 "reserved" 1951 "reserved" 1950 "reserved" 1949 "reserved" 1948 "reserved" 1947 "reserved" 1946 "reserved" 1945 "reserved" 1944 "reserved" 1943 "reserved" 1942 "reserved" 1941 "reserved" 1940 "reserved" 1939 "reserved" 1938 "reserved" 1937 "reserved" 1936 "reserved" 1935 "reserved" 1934 "reserved" 1933 "reserved" 1932 "reserved" 1931 "reserved" 1930 "reserved" 1929 "reserved" 1928 "reserved" 1927 "reserved" 1926 "reserved" 1925 "reserved" 1924 "reserved" 1923 "reserved" 1922 "reserved" 1921 "reserved" 1920 "reserved" 1919 "reserved" 1918 "reserved" 1917 "reserved" 1916 "reserved" 1915 "reserved" 1914 "reserved" 1913 "reserved" 1912 "reserved" 1911 "reserved" 1910 "reserved" 1909 "reserved" 1908 "reserved" 1907 "reserved" 1906 "reserved" 1905 "reserved" 1904 "reserved" 1903 "reserved" 1902 "reserved" 1901 "reserved" 1900 "reserved" 1899 "reserved" 1898 "reserved" 1897 "reserved" 1896 "reserved" 1895 "reserved" 1894 "reserved" 1893 "reserved" 1892 "reserved" 1891 "reserved" 1890 "reserved" 1889 "reserved" 1888 "reserved" 1887 "reserved" 1886 "reserved" 1885 "reserved" 1884 "reserved" 1883 "reserved" 1882 "reserved" 1881 "reserved" 1880 "reserved" 1879 "reserved" 1878 "reserved" 1877 "reserved" 1876 "reserved" 1875 "reserved" 1874 "reserved" 1873 "reserved" 1872 "reserved" 1871 "reserved" 1870 "reserved" 1869 "reserved" 1868 "reserved" 1867 "reserved" 1866 "reserved" 1865 "reserved" 1864 "reserved" 1863 "reserved" 1862 "reserved" 1861 "reserved" 1860 "reserved" 1859 "reserved" 1858 "reserved" 1857 "reserved" 1856 "reserved" 1855 "reserved" 1854 "reserved" 1853 "reserved" 1852 "reserved" 1851 "reserved" 1850 "reserved" 1849 "reserved" 1848 "reserved" 1847 "reserved" 1846 "reserved" 1845 "reserved" 1844 "reserved" 1843 "reserved" 1842 "reserved" 1841 "reserved" 1840 "reserved" 1839 "reserved" 1838 "reserved" 1837 "reserved" 1836 "reserved" 1835 "reserved" 1834 "reserved" 1833 "reserved" 1832 "reserved" 1831 "reserved" 1830 "reserved" 1829 "reserved" 1828 "reserved" 1827 "reserved" 1826 "reserved" 1825 "reserved" 1824 "reserved" 1823 "reserved" 1822 "reserved" 1821 "reserved" 1820 "reserved" 1819 "reserved" 1818 "reserved" 1817 "reserved" 1816 "reserved" 1815 "reserved" 1814 "reserved" 1813 "reserved" 1812 "reserved" 1811 "reserved" 1810 "reserved" 1809 "reserved" 1808 "reserved" 1807 "reserved" 1806 "reserved" 1805 "reserved" 1804 "reserved" 1803 "reserved" 1802 "reserved" 1801 "reserved" 1800 "reserved" 1799 "reserved" 1798 "reserved" 1797 "reserved" 1796 "reserved" 1795 "reserved" 1794 "reserved" 1793 "reserved" 1792 "reserved" 1791 "reserved" 1790 "reserved" 1789 "reserved" 1788 "reserved" 1787 "reserved" 1786 "reserved" 1785 "reserved" 1784 "reserved" 1783 "reserved" 1782 "reserved" 1781 "reserved" 1780 "reserved" 1779 "reserved" 1778 "reserved" 1777 "reserved" 1776 "reserved" 1775 "reserved" 1774 "reserved" 1773 "reserved" 1772 "reserved" 1771 "reserved" 1770 "reserved" 1769 "reserved" 1768 "reserved" 1767 "reserved" 1766 "reserved" 1765 "reserved" 1764 "reserved" 1763 "reserved" 1762 "reserved" 1761 "reserved" 1760 "reserved" 1759 "reserved" 1758 "reserved" 1757 "reserved" 1756 "reserved" 1755 "reserved" 1754 "reserved" 1753 "reserved" 1752 "reserved" 1751 "reserved" 1750 "reserved" 1749 "reserved" 1748 "reserved" 1747 "reserved" 1746 "reserved" 1745 "reserved" 1744 "reserved" 1743 "reserved" 1742 "reserved" 1741 "reserved" 1740 "reserved" 1739 "reserved" 1738 "reserved" 1737 "reserved" 1736 "reserved" 1735 "reserved" 1734 "reserved" 1733 "reserved" 1732 "reserved" 1731 "reserved" 1730 "reserved" 1729 "reserved" 1728 "reserved" 1727 "reserved" 1726 "reserved" 1725 "reserved" 1724 "reserved" 1723 "reserved" 1722 "reserved" 1721 "reserved" 1720 "reserved" 1719 "reserved" 1718 "reserved" 1717 "reserved" 1716 "reserved" 1715 "reserved" 1714 "reserved" 1713 "reserved" 1712 "reserved" 1711 "reserved" 1710 "reserved" 1709 "reserved" 1708 "reserved" 1707 "reserved" 1706 "reserved" 1705 "reserved" 1704 "reserved" 1703 "reserved" 1702 "reserved" 1701 "reserved" 1700 "reserved" 1699 "reserved" 1698 "reserved" 1697 "reserved" 1696 "reserved" 1695 "reserved" 1694 "reserved" 1693 "reserved" 1692 "reserved" 1691 "reserved" 1690 "reserved" 1689 "reserved" 1688 "reserved" 1687 "reserved" 1686 "reserved" 1685 "reserved" 1684 "reserved" 1683 "reserved" 1682 "reserved" 1681 "reserved" 1680 "reserved" 1679 "reserved" 1678 "reserved" 1677 "reserved" 1676 "reserved" 1675 "reserved" 1674 "reserved" 1673 "reserved" 1672 "reserved" 1671 "reserved" 1670 "reserved" 1669 "reserved" 1668 "reserved" 1667 "reserved" 1666 "reserved" 1665 "reserved" 1664 "reserved" 1663 "reserved" 1662 "reserved" 1661 "reserved" 1660 "reserved" 1659 "reserved" 1658 "reserved" 1657 "reserved" 1656 "reserved" 1655 "reserved" 1654 "reserved" 1653 "reserved" 1652 "reserved" 1651 "reserved" 1650 "reserved" 1649 "reserved" 1648 "reserved" 1647 "reserved" 1646 "reserved" 1645 "reserved" 1644 "reserved" 1643 "reserved" 1642 "reserved" 1641 "reserved" 1640 "reserved" 1639 "reserved" 1638 "reserved" 1637 "reserved" 1636 "reserved" 1635 "reserved" 1634 "reserved" 1633 "reserved" 1632 "reserved" 1631 "reserved" 1630 "reserved" 1629 "reserved" 1628 "reserved" 1627 "reserved" 1626 "reserved" 1625 "reserved" 1624 "reserved" 1623 "reserved" 1622 "reserved" 1621 "reserved" 1620 "reserved" 1619 "reserved" 1618 "reserved" 1617 "reserved" 1616 "reserved" 1615 "reserved" 1614 "reserved" 1613 "reserved" 1612 "reserved" 1611 "reserved" 1610 "reserved" 1609 "reserved" 1608 "reserved" 1607 "reserved" 1606 "reserved" 1605 "reserved" 1604 "reserved" 1603 "reserved" 1602 "reserved" 1601 "reserved" ;
VAL_ 336 AnimSpeed 1023 "reserved" 1022 "reserved" 1021 "reserved" 1020 "reserved" 1019 "reserved" 1018 "reserved" 1017 "reserved" 1016 "reserved" 1015 "reserved" 1014 "reserved" 1013 "reserved" 1012 "reserved" 1011 "reserved" 1010 "reserved" 1009 "reserved" 1008 "reserved" 1007 "reserved" 1006 "reserved" 1005 "reserved" 1004 "reserved" 1003 "reserved" 1002 "reserved" 1001 "reserved" ;
VAL_ 336 AnimMode 3 "Others" 2 "Preceding" 1 "Oncoming" 0 "Idle" ;
VAL_ 336 ScreenSaver_Timeout 63 " Not Available" 62 " Initating" 0 " No Object" ;
VAL_ 336 ThemeSelect 12 " β��˫��" 11 " β�Ƶ���" 10 " ǰ��˫��" 9 " ǰ�Ƶ���" 8 " Unknown" 7 " Billboard" 6 " Mixed" 5 " Pedestrain" 4 " Bike" 3 " Bus" 2 " Truck" 1 " Car" 0 " NoVehicle" ;
VAL_ 336 FontSize 2047 "reserved" 2046 "reserved" 2045 "reserved" 2044 "reserved" 2043 "reserved" 2042 "reserved" 2041 "reserved" 2040 "reserved" 2039 "reserved" 2038 "reserved" 2037 "reserved" 2036 "reserved" 2035 "reserved" 2034 "reserved" 2033 "reserved" 2032 "reserved" 2031 "reserved" 2030 "reserved" 2029 "reserved" 2028 "reserved" 2027 "reserved" 2026 "reserved" 2025 "reserved" 2024 "reserved" 2023 "reserved" 2022 "reserved" 2021 "reserved" 2020 "reserved" 2019 "reserved" 2018 "reserved" 2017 "reserved" 2016 "reserved" 2015 "reserved" 2014 "reserved" 2013 "reserved" 2012 "reserved" 2011 "reserved" 2010 "reserved" 2009 "reserved" 2008 "reserved" 2007 "reserved" 2006 "reserved" 2005 "reserved" 2004 "reserved" 2003 "reserved" 2002 "reserved" 2001 "reserved" 2000 "reserved" 1999 "reserved" 1998 "reserved" 1997 "reserved" 1996 "reserved" 1995 "reserved" 1994 "reserved" 1993 "reserved" 1992 "reserved" 1991 "reserved" 1990 "reserved" 1989 "reserved" 1988 "reserved" 1987 "reserved" 1986 "reserved" 1985 "reserved" 1984 "reserved" 1983 "reserved" 1982 "reserved" 1981 "reserved" 1980 "reserved" 1979 "reserved" 1978 "reserved" 1977 "reserved" 1976 "reserved" 1975 "reserved" 1974 "reserved" 1973 "reserved" 1972 "reserved" 1971 "reserved" 1970 "reserved" 1969 "reserved" 1968 "reserved" 1967 "reserved" 1966 "reserved" 1965 "reserved" 1964 "reserved" 1963 "reserved" 1962 "reserved" 1961 "reserved" 1960 "reserved" 1959 "reserved" 1958 "reserved" 1957 "reserved" 1956 "reserved" 1955 "reserved" 1954 "reserved" 1953 "reserved" 1952 "reserved" 1951 "reserved" 1950 "reserved" 1949 "reserved" 1948 "reserved" 1947 "reserved" 1946 "reserved" 1945 "reserved" 1944 "reserved" 1943 "reserved" 1942 "reserved" 1941 "reserved" 1940 "reserved" 1939 "reserved" 1938 "reserved" 1937 "reserved" 1936 "reserved" 1935 "reserved" 1934 "reserved" 1933 "reserved" 1932 "reserved" 1931 "reserved" 1930 "reserved" 1929 "reserved" 1928 "reserved" 1927 "reserved" 1926 "reserved" 1925 "reserved" 1924 "reserved" 1923 "reserved" 1922 "reserved" 1921 "reserved" 1920 "reserved" 1919 "reserved" 1918 "reserved" 1917 "reserved" 1916 "reserved" 1915 "reserved" 1914 "reserved" 1913 "reserved" 1912 "reserved" 1911 "reserved" 1910 "reserved" 1909 "reserved" 1908 "reserved" 1907 "reserved" 1906 "reserved" 1905 "reserved" 1904 "reserved" 1903 "reserved" 1902 "reserved" 1901 "reserved" 1900 "reserved" 1899 "reserved" 1898 "reserved" 1897 "reserved" 1896 "reserved" 1895 "reserved" 1894 "reserved" 1893 "reserved" 1892 "reserved" 1891 "reserved" 1890 "reserved" 1889 "reserved" 1888 "reserved" 1887 "reserved" 1886 "reserved" 1885 "reserved" 1884 "reserved" 1883 "reserved" 1882 "reserved" 1881 "reserved" 1880 "reserved" 1879 "reserved" 1878 "reserved" 1877 "reserved" 1876 "reserved" 1875 "reserved" 1874 "reserved" 1873 "reserved" 1872 "reserved" 1871 "reserved" 1870 "reserved" 1869 "reserved" 1868 "reserved" 1867 "reserved" 1866 "reserved" 1865 "reserved" 1864 "reserved" 1863 "reserved" 1862 "reserved" 1861 "reserved" 1860 "reserved" 1859 "reserved" 1858 "reserved" 1857 "reserved" 1856 "reserved" 1855 "reserved" 1854 "reserved" 1853 "reserved" 1852 "reserved" 1851 "reserved" 1850 "reserved" 1849 "reserved" 1848 "reserved" 1847 "reserved" 1846 "reserved" 1845 "reserved" 1844 "reserved" 1843 "reserved" 1842 "reserved" 1841 "reserved" 1840 "reserved" 1839 "reserved" 1838 "reserved" 1837 "reserved" 1836 "reserved" 1835 "reserved" 1834 "reserved" 1833 "reserved" 1832 "reserved" 1831 "reserved" 1830 "reserved" 1829 "reserved" 1828 "reserved" 1827 "reserved" 1826 "reserved" 1825 "reserved" 1824 "reserved" 1823 "reserved" 1822 "reserved" 1821 "reserved" 1820 "reserved" 1819 "reserved" 1818 "reserved" 1817 "reserved" 1816 "reserved" 1815 "reserved" 1814 "reserved" 1813 "reserved" 1812 "reserved" 1811 "reserved" 1810 "reserved" 1809 "reserved" 1808 "reserved" 1807 "reserved" 1806 "reserved" 1805 "reserved" 1804 "reserved" 1803 "reserved" 1802 "reserved" 1801 "reserved" 1800 "reserved" 1799 "reserved" 1798 "reserved" 1797 "reserved" 1796 "reserved" 1795 "reserved" 1794 "reserved" 1793 "reserved" 1792 "reserved" 1791 "reserved" 1790 "reserved" 1789 "reserved" 1788 "reserved" 1787 "reserved" 1786 "reserved" 1785 "reserved" 1784 "reserved" 1783 "reserved" 1782 "reserved" 1781 "reserved" 1780 "reserved" 1779 "reserved" 1778 "reserved" 1777 "reserved" 1776 "reserved" 1775 "reserved" 1774 "reserved" 1773 "reserved" 1772 "reserved" 1771 "reserved" 1770 "reserved" 1769 "reserved" 1768 "reserved" 1767 "reserved" 1766 "reserved" 1765 "reserved" 1764 "reserved" 1763 "reserved" 1762 "reserved" 1761 "reserved" 1760 "reserved" 1759 "reserved" 1758 "reserved" 1757 "reserved" 1756 "reserved" 1755 "reserved" 1754 "reserved" 1753 "reserved" 1752 "reserved" 1751 "reserved" 1750 "reserved" 1749 "reserved" 1748 "reserved" 1747 "reserved" 1746 "reserved" 1745 "reserved" 1744 "reserved" 1743 "reserved" 1742 "reserved" 1741 "reserved" 1740 "reserved" 1739 "reserved" 1738 "reserved" 1737 "reserved" 1736 "reserved" 1735 "reserved" 1734 "reserved" 1733 "reserved" 1732 "reserved" 1731 "reserved" 1730 "reserved" 1729 "reserved" 1728 "reserved" 1727 "reserved" 1726 "reserved" 1725 "reserved" 1724 "reserved" 1723 "reserved" 1722 "reserved" 1721 "reserved" 1720 "reserved" 1719 "reserved" 1718 "reserved" 1717 "reserved" 1716 "reserved" 1715 "reserved" 1714 "reserved" 1713 "reserved" 1712 "reserved" 1711 "reserved" 1710 "reserved" 1709 "reserved" 1708 "reserved" 1707 "reserved" 1706 "reserved" 1705 "reserved" 1704 "reserved" 1703 "reserved" 1702 "reserved" 1701 "reserved" 1700 "reserved" 1699 "reserved" 1698 "reserved" 1697 "reserved" 1696 "reserved" 1695 "reserved" 1694 "reserved" 1693 "reserved" 1692 "reserved" 1691 "reserved" 1690 "reserved" 1689 "reserved" 1688 "reserved" 1687 "reserved" 1686 "reserved" 1685 "reserved" 1684 "reserved" 1683 "reserved" 1682 "reserved" 1681 "reserved" 1680 "reserved" 1679 "reserved" 1678 "reserved" 1677 "reserved" 1676 "reserved" 1675 "reserved" 1674 "reserved" 1673 "reserved" 1672 "reserved" 1671 "reserved" 1670 "reserved" 1669 "reserved" 1668 "reserved" 1667 "reserved" 1666 "reserved" 1665 "reserved" 1664 "reserved" 1663 "reserved" 1662 "reserved" 1661 "reserved" 1660 "reserved" 1659 "reserved" 1658 "reserved" 1657 "reserved" 1656 "reserved" 1655 "reserved" 1654 "reserved" 1653 "reserved" 1652 "reserved" 1651 "reserved" 1650 "reserved" 1649 "reserved" 1648 "reserved" 1647 "reserved" 1646 "reserved" 1645 "reserved" 1644 "reserved" 1643 "reserved" 1642 "reserved" 1641 "reserved" 1640 "reserved" 1639 "reserved" 1638 "reserved" 1637 "reserved" 1636 "reserved" 1635 "reserved" 1634 "reserved" 1633 "reserved" 1632 "reserved" 1631 "reserved" 1630 "reserved" 1629 "reserved" 1628 "reserved" 1627 "reserved" 1626 "reserved" 1625 "reserved" 1624 "reserved" 1623 "reserved" 1622 "reserved" 1621 "reserved" 1620 "reserved" 1619 "reserved" 1618 "reserved" 1617 "reserved" 1616 "reserved" 1615 "reserved" 1614 "reserved" 1613 "reserved" 1612 "reserved" 1611 "reserved" 1610 "reserved" 1609 "reserved" 1608 "reserved" 1607 "reserved" 1606 "reserved" 1605 "reserved" 1604 "reserved" 1603 "reserved" 1602 "reserved" 1601 "reserved" ;
VAL_ 336 DensityMode 2047 "reserved" 2046 "reserved" 2045 "reserved" 2044 "reserved" 2043 "reserved" 2042 "reserved" 2041 "reserved" 2040 "reserved" 2039 "reserved" 2038 "reserved" 2037 "reserved" 2036 "reserved" 2035 "reserved" 2034 "reserved" 2033 "reserved" 2032 "reserved" 2031 "reserved" 2030 "reserved" 2029 "reserved" 2028 "reserved" 2027 "reserved" 2026 "reserved" 2025 "reserved" 2024 "reserved" 2023 "reserved" 2022 "reserved" 2021 "reserved" 2020 "reserved" 2019 "reserved" 2018 "reserved" 2017 "reserved" 2016 "reserved" 2015 "reserved" 2014 "reserved" 2013 "reserved" 2012 "reserved" 2011 "reserved" 2010 "reserved" 2009 "reserved" 2008 "reserved" 2007 "reserved" 2006 "reserved" 2005 "reserved" 2004 "reserved" 2003 "reserved" 2002 "reserved" 2001 "reserved" 2000 "reserved" 1999 "reserved" 1998 "reserved" 1997 "reserved" 1996 "reserved" 1995 "reserved" 1994 "reserved" 1993 "reserved" 1992 "reserved" 1991 "reserved" 1990 "reserved" 1989 "reserved" 1988 "reserved" 1987 "reserved" 1986 "reserved" 1985 "reserved" 1984 "reserved" 1983 "reserved" 1982 "reserved" 1981 "reserved" 1980 "reserved" 1979 "reserved" 1978 "reserved" 1977 "reserved" 1976 "reserved" 1975 "reserved" 1974 "reserved" 1973 "reserved" 1972 "reserved" 1971 "reserved" 1970 "reserved" 1969 "reserved" 1968 "reserved" 1967 "reserved" 1966 "reserved" 1965 "reserved" 1964 "reserved" 1963 "reserved" 1962 "reserved" 1961 "reserved" 1960 "reserved" 1959 "reserved" 1958 "reserved" 1957 "reserved" 1956 "reserved" 1955 "reserved" 1954 "reserved" 1953 "reserved" 1952 "reserved" 1951 "reserved" 1950 "reserved" 1949 "reserved" 1948 "reserved" 1947 "reserved" 1946 "reserved" 1945 "reserved" 1944 "reserved" 1943 "reserved" 1942 "reserved" 1941 "reserved" 1940 "reserved" 1939 "reserved" 1938 "reserved" 1937 "reserved" 1936 "reserved" 1935 "reserved" 1934 "reserved" 1933 "reserved" 1932 "reserved" 1931 "reserved" 1930 "reserved" 1929 "reserved" 1928 "reserved" 1927 "reserved" 1926 "reserved" 1925 "reserved" 1924 "reserved" 1923 "reserved" 1922 "reserved" 1921 "reserved" 1920 "reserved" 1919 "reserved" 1918 "reserved" 1917 "reserved" 1916 "reserved" 1915 "reserved" 1914 "reserved" 1913 "reserved" 1912 "reserved" 1911 "reserved" 1910 "reserved" 1909 "reserved" 1908 "reserved" 1907 "reserved" 1906 "reserved" 1905 "reserved" 1904 "reserved" 1903 "reserved" 1902 "reserved" 1901 "reserved" 1900 "reserved" 1899 "reserved" 1898 "reserved" 1897 "reserved" 1896 "reserved" 1895 "reserved" 1894 "reserved" 1893 "reserved" 1892 "reserved" 1891 "reserved" 1890 "reserved" 1889 "reserved" 1888 "reserved" 1887 "reserved" 1886 "reserved" 1885 "reserved" 1884 "reserved" 1883 "reserved" 1882 "reserved" 1881 "reserved" 1880 "reserved" 1879 "reserved" 1878 "reserved" 1877 "reserved" 1876 "reserved" 1875 "reserved" 1874 "reserved" 1873 "reserved" 1872 "reserved" 1871 "reserved" 1870 "reserved" 1869 "reserved" 1868 "reserved" 1867 "reserved" 1866 "reserved" 1865 "reserved" 1864 "reserved" 1863 "reserved" 1862 "reserved" 1861 "reserved" 1860 "reserved" 1859 "reserved" 1858 "reserved" 1857 "reserved" 1856 "reserved" 1855 "reserved" 1854 "reserved" 1853 "reserved" 1852 "reserved" 1851 "reserved" 1850 "reserved" 1849 "reserved" 1848 "reserved" 1847 "reserved" 1846 "reserved" 1845 "reserved" 1844 "reserved" 1843 "reserved" 1842 "reserved" 1841 "reserved" 1840 "reserved" 1839 "reserved" 1838 "reserved" 1837 "reserved" 1836 "reserved" 1835 "reserved" 1834 "reserved" 1833 "reserved" 1832 "reserved" 1831 "reserved" 1830 "reserved" 1829 "reserved" 1828 "reserved" 1827 "reserved" 1826 "reserved" 1825 "reserved" 1824 "reserved" 1823 "reserved" 1822 "reserved" 1821 "reserved" 1820 "reserved" 1819 "reserved" 1818 "reserved" 1817 "reserved" 1816 "reserved" 1815 "reserved" 1814 "reserved" 1813 "reserved" 1812 "reserved" 1811 "reserved" 1810 "reserved" 1809 "reserved" 1808 "reserved" 1807 "reserved" 1806 "reserved" 1805 "reserved" 1804 "reserved" 1803 "reserved" 1802 "reserved" 1801 "reserved" 1800 "reserved" 1799 "reserved" 1798 "reserved" 1797 "reserved" 1796 "reserved" 1795 "reserved" 1794 "reserved" 1793 "reserved" 1792 "reserved" 1791 "reserved" 1790 "reserved" 1789 "reserved" 1788 "reserved" 1787 "reserved" 1786 "reserved" 1785 "reserved" 1784 "reserved" 1783 "reserved" 1782 "reserved" 1781 "reserved" 1780 "reserved" 1779 "reserved" 1778 "reserved" 1777 "reserved" 1776 "reserved" 1775 "reserved" 1774 "reserved" 1773 "reserved" 1772 "reserved" 1771 "reserved" 1770 "reserved" 1769 "reserved" 1768 "reserved" 1767 "reserved" 1766 "reserved" 1765 "reserved" 1764 "reserved" 1763 "reserved" 1762 "reserved" 1761 "reserved" 1760 "reserved" 1759 "reserved" 1758 "reserved" 1757 "reserved" 1756 "reserved" 1755 "reserved" 1754 "reserved" 1753 "reserved" 1752 "reserved" 1751 "reserved" 1750 "reserved" 1749 "reserved" 1748 "reserved" 1747 "reserved" 1746 "reserved" 1745 "reserved" 1744 "reserved" 1743 "reserved" 1742 "reserved" 1741 "reserved" 1740 "reserved" 1739 "reserved" 1738 "reserved" 1737 "reserved" 1736 "reserved" 1735 "reserved" 1734 "reserved" 1733 "reserved" 1732 "reserved" 1731 "reserved" 1730 "reserved" 1729 "reserved" 1728 "reserved" 1727 "reserved" 1726 "reserved" 1725 "reserved" 1724 "reserved" 1723 "reserved" 1722 "reserved" 1721 "reserved" 1720 "reserved" 1719 "reserved" 1718 "reserved" 1717 "reserved" 1716 "reserved" 1715 "reserved" 1714 "reserved" 1713 "reserved" 1712 "reserved" 1711 "reserved" 1710 "reserved" 1709 "reserved" 1708 "reserved" 1707 "reserved" 1706 "reserved" 1705 "reserved" 1704 "reserved" 1703 "reserved" 1702 "reserved" 1701 "reserved" 1700 "reserved" 1699 "reserved" 1698 "reserved" 1697 "reserved" 1696 "reserved" 1695 "reserved" 1694 "reserved" 1693 "reserved" 1692 "reserved" 1691 "reserved" 1690 "reserved" 1689 "reserved" 1688 "reserved" 1687 "reserved" 1686 "reserved" 1685 "reserved" 1684 "reserved" 1683 "reserved" 1682 "reserved" 1681 "reserved" 1680 "reserved" 1679 "reserved" 1678 "reserved" 1677 "reserved" 1676 "reserved" 1675 "reserved" 1674 "reserved" 1673 "reserved" 1672 "reserved" 1671 "reserved" 1670 "reserved" 1669 "reserved" 1668 "reserved" 1667 "reserved" 1666 "reserved" 1665 "reserved" 1664 "reserved" 1663 "reserved" 1662 "reserved" 1661 "reserved" 1660 "reserved" 1659 "reserved" 1658 "reserved" 1657 "reserved" 1656 "reserved" 1655 "reserved" 1654 "reserved" 1653 "reserved" 1652 "reserved" 1651 "reserved" 1650 "reserved" 1649 "reserved" 1648 "reserved" 1647 "reserved" 1646 "reserved" 1645 "reserved" 1644 "reserved" 1643 "reserved" 1642 "reserved" 1641 "reserved" 1640 "reserved" 1639 "reserved" 1638 "reserved" 1637 "reserved" 1636 "reserved" 1635 "reserved" 1634 "reserved" 1633 "reserved" 1632 "reserved" 1631 "reserved" 1630 "reserved" 1629 "reserved" 1628 "reserved" 1627 "reserved" 1626 "reserved" 1625 "reserved" 1624 "reserved" 1623 "reserved" 1622 "reserved" 1621 "reserved" 1620 "reserved" 1619 "reserved" 1618 "reserved" 1617 "reserved" 1616 "reserved" 1615 "reserved" 1614 "reserved" 1613 "reserved" 1612 "reserved" 1611 "reserved" 1610 "reserved" 1609 "reserved" 1608 "reserved" 1607 "reserved" 1606 "reserved" 1605 "reserved" 1604 "reserved" 1603 "reserved" 1602 "reserved" 1601 "reserved" ;
VAL_ 336 NightMode_Enable 1023 "reserved" 1022 "reserved" 1021 "reserved" 1020 "reserved" 1019 "reserved" 1018 "reserved" 1017 "reserved" 1016 "reserved" 1015 "reserved" 1014 "reserved" 1013 "reserved" 1012 "reserved" 1011 "reserved" 1010 "reserved" 1009 "reserved" 1008 "reserved" 1007 "reserved" 1006 "reserved" 1005 "reserved" 1004 "reserved" 1003 "reserved" 1002 "reserved" 1001 "reserved" ;
VAL_ 336 NightMode_Sensor 3 "Others" 2 "Preceding" 1 "Oncoming" 0 "Idle" ;
VAL_ 337 Media2_CRC 63 " Not Available" 62 " Initating" 0 " No Object" ;
VAL_ 337 Media2_RollCnt 12 " β��˫��" 11 " β�Ƶ���" 10 " ǰ��˫��" 9 " ǰ�Ƶ���" 8 " Unknown" 7 " Billboard" 6 " Mixed" 5 " Pedestrain" 4 " Bike" 3 " Bus" 2 " Truck" 1 " Car" 0 " NoVehicle" ;
VAL_ 337 RadioPreset_2 2047 "reserved" 2046 "reserved" 2045 "reserved" 2044 "reserved" 2043 "reserved" 2042 "reserved" 2041 "reserved" 2040 "reserved" 2039 "reserved" 2038 "reserved" 2037 "reserved" 2036 "reserved" 2035 "reserved" 2034 "reserved" 2033 "reserved" 2032 "reserved" 2031 "reserved" 2030 "reserved" 2029 "reserved" 2028 "reserved" 2027 "reserved" 2026 "reserved" 2025 "reserved" 2024 "reserved" 2023 "reserved" 2022 "reserved" 2021 "reserved" 2020 "reserved" 2019 "reserved" 2018 "reserved" 2017 "reserved" 2016 "reserved" 2015 "reserved" 2014 "reserved" 2013 "reserved" 2012 "reserved" 2011 "reserved" 2010 "reserved" 2009 "reserved" 2008 "reserved" 2007 "reserved" 2006 "reserved" 2005 "reserved" 2004 "reserved" 2003 "reserved" 2002 "reserved" 2001 "reserved" 2000 "reserved" 1999 "reserved" 1998 "reserved" 1997 "reserved" 1996 "reserved" 1995 "reserved" 1994 "reserved" 1993 "reserved" 1992 "reserved" 1991 "reserved" 1990 "reserved" 1989 "reserved" 1988 "reserved" 1987 "reserved" 1986 "reserved" 1985 "reserved" 1984 "reserved" 1983 "reserved" 1982 "reserved" 1981 "reserved" 1980 "reserved" 1979 "reserved" 1978 "reserved" 1977 "reserved" 1976 "reserved" 1975 "reserved" 1974 "reserved" 1973 "reserved" 1972 "reserved" 1971 "reserved" 1970 "reserved" 1969 "reserved" 1968 "reserved" 1967 "reserved" 1966 "reserved" 1965 "reserved" 1964 "reserved" 1963 "reserved" 1962 "reserved" 1961 "reserved" 1960 "reserved" 1959 "reserved" 1958 "reserved" 1957 "reserved" 1956 "reserved" 1955 "reserved" 1954 "reserved" 1953 "reserved" 1952 "reserved" 1951 "reserved" 1950 "reserved" 1949 "reserved" 1948 "reserved" 1947 "reserved" 1946 "reserved" 1945 "reserved" 1944 "reserved" 1943 "reserved" 1942 "reserved" 1941 "reserved" 1940 "reserved" 1939 "reserved" 1938 "reserved" 1937 "reserved" 1936 "reserved" 1935 "reserved" 1934 "reserved" 1933 "reserved" 1932 "reserved" 1931 "reserved" 1930 "reserved" 1929 "reserved" 1928 "reserved" 1927 "reserved" 1926 "reserved" 1925 "reserved" 1924 "reserved" 1923 "reserved" 1922 "reserved" 1921 "reserved" 1920 "reserved" 1919 "reserved" 1918 "reserved" 1917 "reserved" 1916 "reserved" 1915 "reserved" 1914 "reserved" 1913 "reserved" 1912 "reserved" 1911 "reserved" 1910 "reserved" 1909 "reserved" 1908 "reserved" 1907 "reserved" 1906 "reserved" 1905 "reserved" 1904 "reserved" 1903 "reserved" 1902 "reserved" 1901 "reserved" 1900 "reserved" 1899 "reserved" 1898 "reserved" 1897 "reserved" 1896 "reserved" 1895 "reserved" 1894 "reserved" 1893 "reserved" 1892 "reserved" 1891 "reserved" 1890 "reserved" 1889 "reserved" 1888 "reserved" 1887 "reserved" 1886 "reserved" 1885 "reserved" 1884 "reserved" 1883 "reserved" 1882 "reserved" 1881 "reserved" 1880 "reserved" 1879 "reserved" 1878 "reserved" 1877 "reserved" 1876 "reserved" 1875 "reserved" 1874 "reserved" 1873 "reserved" 1872 "reserved" 1871 "reserved" 1870 "reserved" 1869 "reserved" 1868 "reserved" 1867 "reserved" 1866 "reserved" 1865 "reserved" 1864 "reserved" 1863 "reserved" 1862 "reserved" 1861 "reserved" 1860 "reserved" 1859 "reserved" 1858 "reserved" 1857 "reserved" 1856 "reserved" 1855 "reserved" 1854 "reserved" 1853 "reserved" 1852 "reserved" 1851 "reserved" 1850 "reserved" 1849 "reserved" 1848 "reserved" 1847 "reserved" 1846 "reserved" 1845 "reserved" 1844 "reserved" 1843 "reserved" 1842 "reserved" 1841 "reserved" 1840 "reserved" 1839 "reserved" 1838 "reserved" 1837 "reserved" 1836 "reserved" 1835 "reserved" 1834 "reserved" 1833 "reserved" 1832 "reserved" 1831 "reserved" 1830 "reserved" 1829 "reserved" 1828 "reserved" 1827 "reserved" 1826 "reserved" 1825 "reserved" 1824 "reserved" 1823 "reserved" 1822 "reserved" 1821 "reserved" 1820 "reserved" 1819 "reserved" 1818 "reserved" 1817 "reserved" 1816 "reserved" 1815 "reserved" 1814 "reserved" 1813 "reserved" 1812 "reserved" 1811 "reserved" 1810 "reserved" 1809 "reserved" 1808 "reserved" 1807 "reserved" 1806 "reserved" 1805 "reserved" 1804 "reserved" 1803 "reserved" 1802 "reserved" 1801 "reserved" 1800 "reserved" 1799 "reserved" 1798 "reserved" 1797 "reserved" 1796 "reserved" 1795 "reserved" 1794 "reserved" 1793 "reserved" 1792 "reserved" 1791 "reserved" 1790 "reserved" 1789 "reserved" 1788 "reserved" 1787 "reserved" 1786 "reserved" 1785 "reserved" 1784 "reserved" 1783 "reserved" 1782 "reserved" 1781 "reserved" 1780 "reserved" 1779 "reserved" 1778 "reserved" 1777 "reserved" 1776 "reserved" 1775 "reserved" 1774 "reserved" 1773 "reserved" 1772 "reserved" 1771 "reserved" 1770 "reserved" 1769 "reserved" 1768 "reserved" 1767 "reserved" 1766 "reserved" 1765 "reserved" 1764 "reserved" 1763 "reserved" 1762 "reserved" 1761 "reserved" 1760 "reserved" 1759 "reserved" 1758 "reserved" 1757 "reserved" 1756 "reserved" 1755 "reserved" 1754 "reserved" 1753 "reserved" 1752 "reserved" 1751 "reserved" 1750 "reserved" 1749 "reserved" 1748 "reserved" 1747 "reserved" 1746 "reserved" 1745 "reserved" 1744 "reserved" 1743 "reserved" 1742 "reserved" 1741 "reserved" 1740 "reserved" 1739 "reserved" 1738 "reserved" 1737 "reserved" 1736 "reserved" 1735 "reserved" 1734 "reserved" 1733 "reserved" 1732 "reserved" 1731 "reserved" 1730 "reserved" 1729 "reserved" 1728 "reserved" 1727 "reserved" 1726 "reserved" 1725 "reserved" 1724 "reserved" 1723 "reserved" 1722 "reserved" 1721 "reserved" 1720 "reserved" 1719 "reserved" 1718 "reserved" 1717 "reserved" 1716 "reserved" 1715 "reserved" 1714 "reserved" 1713 "reserved" 1712 "reserved" 1711 "reserved" 1710 "reserved" 1709 "reserved" 1708 "reserved" 1707 "reserved" 1706 "reserved" 1705 "reserved" 1704 "reserved" 1703 "reserved" 1702 "reserved" 1701 "reserved" 1700 "reserved" 1699 "reserved" 1698 "reserved" 1697 "reserved" 1696 "reserved" 1695 "reserved" 1694 "reserved" 1693 "reserved" 1692 "reserved" 1691 "reserved" 1690 "reserved" 1689 "reserved" 1688 "reserved" 1687 "reserved" 1686 "reserved" 1685 "reserved" 1684 "reserved" 1683 "reserved" 1682 "reserved" 1681 "reserved" 1680 "reserved" 1679 "reserved" 1678 "reserved" 1677 "reserved" 1676 "reserved" 1675 "reserved" 1674 "reserved" 1673 "reserved" 1672 "reserved" 1671 "reserved" 1670 "reserved" 1669 "reserved" 1668 "reserved" 1667 "reserved" 1666 "reserved" 1665 "reserved" 1664 "reserved" 1663 "reserved" 1662 "reserved" 1661 "reserved" 1660 "reserved" 1659 "reserved" 1658 "reserved" 1657 "reserved" 1656 "reserved" 1655 "reserved" 1654 "reserved" 1653 "reserved" 1652 "reserved" 1651 "reserved" 1650 "reserved" 1649 "reserved" 1648 "reserved" 1647 "reserved" 1646 "reserved" 1645 "reserved" 1644 "reserved" 1643 "reserved" 1642 "reserved" 1641 "reserved" 1640 "reserved" 1639 "reserved" 1638 "reserved" 1637 "reserved" 1636 "reserved" 1635 "reserved" 1634 "reserved" 1633 "reserved" 1632 "reserved" 1631 "reserved" 1630 "reserved" 1629 "reserved" 1628 "reserved" 1627 "reserved" 1626 "reserved" 1625 "reserved" 1624 "reserved" 1623 "reserved" 1622 "reserved" 1621 "reserved" 1620 "reserved" 1619 "reserved" 1618 "reserved" 1617 "reserved" 1616 "reserved" 1615 "reserved" 1614 "reserved" 1613 "reserved" 1612 "reserved" 1611 "reserved" 1610 "reserved" 1609 "reserved" 1608 "reserved" 1607 "reserved" 1606 "reserved" 1605 "reserved" 1604 "reserved" 1603 "reserved" 1602 "reserved" 1601 "reserved" ;
VAL_ 337 RadioPreset_3 2047 "reserved" 2046 "reserved" 2045 "reserved" 2044 "reserved" 2043 "reserved" 2042 "reserved" 2041 "reserved" 2040 "reserved" 2039 "reserved" 2038 "reserved" 2037 "reserved" 2036 "reserved" 2035 "reserved" 2034 "reserved" 2033 "reserved" 2032 "reserved" 2031 "reserved" 2030 "reserved" 2029 "reserved" 2028 "reserved" 2027 "reserved" 2026 "reserved" 2025 "reserved" 2024 "reserved" 2023 "reserved" 2022 "reserved" 2021 "reserved" 2020 "reserved" 2019 "reserved" 2018 "reserved" 2017 "reserved" 2016 "reserved" 2015 "reserved" 2014 "reserved" 2013 "reserved" 2012 "reserved" 2011 "reserved" 2010 "reserved" 2009 "reserved" 2008 "reserved" 2007 "reserved" 2006 "reserved" 2005 "reserved" 2004 "reserved" 2003 "reserved" 2002 "reserved" 2001 "reserved" 2000 "reserved" 1999 "reserved" 1998 "reserved" 1997 "reserved" 1996 "reserved" 1995 "reserved" 1994 "reserved" 1993 "reserved" 1992 "reserved" 1991 "reserved" 1990 "reserved" 1989 "reserved" 1988 "reserved" 1987 "reserved" 1986 "reserved" 1985 "reserved" 1984 "reserved" 1983 "reserved" 1982 "reserved" 1981 "reserved" 1980 "reserved" 1979 "reserved" 1978 "reserved" 1977 "reserved" 1976 "reserved" 1975 "reserved" 1974 "reserved" 1973 "reserved" 1972 "reserved" 1971 "reserved" 1970 "reserved" 1969 "reserved" 1968 "reserved" 1967 "reserved" 1966 "reserved" 1965 "reserved" 1964 "reserved" 1963 "reserved" 1962 "reserved" 1961 "reserved" 1960 "reserved" 1959 "reserved" 1958 "reserved" 1957 "reserved" 1956 "reserved" 1955 "reserved" 1954 "reserved" 1953 "reserved" 1952 "reserved" 1951 "reserved" 1950 "reserved" 1949 "reserved" 1948 "reserved" 1947 "reserved" 1946 "reserved" 1945 "reserved" 1944 "reserved" 1943 "reserved" 1942 "reserved" 1941 "reserved" 1940 "reserved" 1939 "reserved" 1938 "reserved" 1937 "reserved" 1936 "reserved" 1935 "reserved" 1934 "reserved" 1933 "reserved" 1932 "reserved" 1931 "reserved" 1930 "reserved" 1929 "reserved" 1928 "reserved" 1927 "reserved" 1926 "reserved" 1925 "reserved" 1924 "reserved" 1923 "reserved" 1922 "reserved" 1921 "reserved" 1920 "reserved" 1919 "reserved" 1918 "reserved" 1917 "reserved" 1916 "reserved" 1915 "reserved" 1914 "reserved" 1913 "reserved" 1912 "reserved" 1911 "reserved" 1910 "reserved" 1909 "reserved" 1908 "reserved" 1907 "reserved" 1906 "reserved" 1905 "reserved" 1904 "reserved" 1903 "reserved" 1902 "reserved" 1901 "reserved" 1900 "reserved" 1899 "reserved" 1898 "reserved" 1897 "reserved" 1896 "reserved" 1895 "reserved" 1894 "reserved" 1893 "reserved" 1892 "reserved" 1891 "reserved" 1890 "reserved" 1889 "reserved" 1888 "reserved" 1887 "reserved" 1886 "reserved" 1885 "reserved" 1884 "reserved" 1883 "reserved" 1882 "reserved" 1881 "reserved" 1880 "reserved" 1879 "reserved" 1878 "reserved" 1877 "reserved" 1876 "reserved" 1875 "reserved" 1874 "reserved" 1873 "reserved" 1872 "reserved" 1871 "reserved" 1870 "reserved" 1869 "reserved" 1868 "reserved" 1867 "reserved" 1866 "reserved" 1865 "reserved" 1864 "reserved" 1863 "reserved" 1862 "reserved" 1861 "reserved" 1860 "reserved" 1859 "reserved" 1858 "reserved" 1857 "reserved" 1856 "reserved" 1855 "reserved" 1854 "reserved" 1853 "reserved" 1852 "reserved" 1851 "reserved" 1850 "reserved" 1849 "reserved" 1848 "reserved" 1847 "reserved" 1846 "reserved" 1845 "reserved" 1844 "reserved" 1843 "reserved" 1842 "reserved" 1841 "reserved" 1840 "reserved" 1839 "reserved" 1838 "reserved" 1837 "reserved" 1836 "reserved" 1835 "reserved" 1834 "reserved" 1833 "reserved" 1832 "reserved" 1831 "reserved" 1830 "reserved" 1829 "reserved" 1828 "reserved" 1827 "reserved" 1826 "reserved" 1825 "reserved" 1824 "reserved" 1823 "reserved" 1822 "reserved" 1821 "reserved" 1820 "reserved" 1819 "reserved" 1818 "reserved" 1817 "reserved" 1816 "reserved" 1815 "reserved" 1814 "reserved" 1813 "reserved" 1812 "reserved" 1811 "reserved" 1810 "reserved" 1809 "reserved" 1808 "reserved" 1807 "reserved" 1806 "reserved" 1805 "reserved" 1804 "reserved" 1803 "reserved" 1802 "reserved" 1801 "reserved" 1800 "reserved" 1799 "reserved" 1798 "reserved" 1797 "reserved" 1796 "reserved" 1795 "reserved" 1794 "reserved" 1793 "reserved" 1792 "reserved" 1791 "reserved" 1790 "reserved" 1789 "reserved" 1788 "reserved" 1787 "reserved" 1786 "reserved" 1785 "reserved" 1784 "reserved" 1783 "reserved" 1782 "reserved" 1781 "reserved" 1780 "reserved" 1779 "reserved" 1778 "reserved" 1777 "reserved" 1776 "reserved" 1775 "reserved" 1774 "reserved" 1773 "reserved" 1772 "reserved" 1771 "reserved" 1770 "reserved" 1769 "reserved" 1768 "reserved" 1767 "reserved" 1766 "reserved" 1765 "reserved" 1764 "reserved" 1763 "reserved" 1762 "reserved" 1761 "reserved" 1760 "reserved" 1759 "reserved" 1758 "reserved" 1757 "reserved" 1756 "reserved" 1755 "reserved" 1754 "reserved" 1753 "reserved" 1752 "reserved" 1751 "reserved" 1750 "reserved" 1749 "reserved" 1748 "reserved" 1747 "reserved" 1746 "reserved" 1745 "reserved" 1744 "reserved" 1743 "reserved" 1742 "reserved" 1741 "reserved" 1740 "reserved" 1739 "reserved" 1738 "reserved" 1737 "reserved" 1736 "reserved" 1735 "reserved" 1734 "reserved" 1733 "reserved" 1732 "reserved" 1731 "reserved" 1730 "reserved" 1729 "reserved" 1728 "reserved" 1727 "reserved" 1726 "reserved" 1725 "reserved" 1724 "reserved" 1723 "reserved" 1722 "reserved" 1721 "reserved" 1720 "reserved" 1719 "reserved" 1718 "reserved" 1717 "reserved" 1716 "reserved" 1715 "reserved" 1714 "reserved" 1713 "reserved" 1712 "reserved" 1711 "reserved" 1710 "reserved" 1709 "reserved" 1708 "reserved" 1707 "reserved" 1706 "reserved" 1705 "reserved" 1704 "reserved" 1703 "reserved" 1702 "reserved" 1701 "reserved" 1700 "reserved" 1699 "reserved" 1698 "reserved" 1697 "reserved" 1696 "reserved" 1695 "reserved" 1694 "reserved" 1693 "reserved" 1692 "reserved" 1691 "reserved" 1690 "reserved" 1689 "reserved" 1688 "reserved" 1687 "reserved" 1686 "reserved" 1685 "reserved" 1684 "reserved" 1683 "reserved" 1682 "reserved" 1681 "reserved" 1680 "reserved" 1679 "reserved" 1678 "reserved" 1677 "reserved" 1676 "reserved" 1675 "reserved" 1674 "reserved" 1673 "reserved" 1672 "reserved" 1671 "reserved" 1670 "reserved" 1669 "reserved" 1668 "reserved" 1667 "reserved" 1666 "reserved" 1665 "reserved" 1664 "reserved" 1663 "reserved" 1662 "reserved" 1661 "reserved" 1660 "reserved" 1659 "reserved" 1658 "reserved" 1657 "reserved" 1656 "reserved" 1655 "reserved" 1654 "reserved" 1653 "reserved" 1652 "reserved" 1651 "reserved" 1650 "reserved" 1649 "reserved" 1648 "reserved" 1647 "reserved" 1646 "reserved" 1645 "reserved" 1644 "reserved" 1643 "reserved" 1642 "reserved" 1641 "reserved" 1640 "reserved" 1639 "reserved" 1638 "reserved" 1637 "reserved" 1636 "reserved" 1635 "reserved" 1634 "reserved" 1633 "reserved" 1632 "reserved" 1631 "reserved" 1630 "reserved" 1629 "reserved" 1628 "reserved" 1627 "reserved" 1626 "reserved" 1625 "reserved" 1624 "reserved" 1623 "reserved" 1622 "reserved" 1621 "reserved" 1620 "reserved" 1619 "reserved" 1618 "reserved" 1617 "reserved" 1616 "reserved" 1615 "reserved" 1614 "reserved" 1613 "reserved" 1612 "reserved" 1611 "reserved" 1610 "reserved" 1609 "reserved" 1608 "reserved" 1607 "reserved" 1606 "reserved" 1605 "reserved" 1604 "reserved" 1603 "reserved" 1602 "reserved" 1601 "reserved" ;
VAL_ 337 RadioPreset_4 1023 "reserved" 1022 "reserved" 1021 "reserved" 1020 "reserved" 1019 "reserved" 1018 "reserved" 1017 "reserved" 1016 "reserved" 1015 "reserved" 1014 "reserved" 1013 "reserved" 1012 "reserved" 1011 "reserved" 1010 "reserved" 1009 "reserved" 1008 "reserved" 1007 "reserved" 1006 "reserved" 1005 "reserved" 1004 "reserved" 1003 "reserved" 1002 "reserved" 1001 "reserved" ;
VAL_ 337 RadioPreset_5 3 "Others" 2 "Preceding" 1 "Oncoming" 0 "Idle" ;
VAL_ 337 SourceSelect 63 " Not Available" 62 " Initating" 0 " No Object" ;
VAL_ 337 SourceValid 12 " β��˫��" 11 " β�Ƶ���" 10 " ǰ��˫��" 9 " ǰ�Ƶ���" 8 " Unknown" 7 " Billboard" 6 " Mixed" 5 " Pedestrain" 4 " Bike" 3 " Bus" 2 " Truck" 1 " Car" 0 " NoVehicle" ;
VAL_ 337 Volume_Media 2047 "reserved" 2046 "reserved" 2045 "reserved" 2044 "reserved" 2043 "reserved" 2042 "reserved" 2041 "reserved" 2040 "reserved" 2039 "reserved" 2038 "reserved" 2037 "reserved" 2036 "reserved" 2035 "reserved" 2034 "reserved" 2033 "reserved" 2032 "reserved" 2031 "reserved" 2030 "reserved" 2029 "reserved" 2028 "reserved" 2027 "reserved" 2026 "reserved" 2025 "reserved" 2024 "reserved" 2023 "reserved" 2022 "reserved" 2021 "reserved" 2020 "reserved" 2019 "reserved" 2018 "reserved" 2017 "reserved" 2016 "reserved" 2015 "reserved" 2014 "reserved" 2013 "reserved" 2012 "reserved" 2011 "reserved" 2010 "reserved" 2009 "reserved" 2008 "reserved" 2007 "reserved" 2006 "reserved" 2005 "reserved" 2004 "reserved" 2003 "reserved" 2002 "reserved" 2001 "reserved" 2000 "reserved" 1999 "reserved" 1998 "reserved" 1997 "reserved" 1996 "reserved" 1995 "reserved" 1994 "reserved" 1993 "reserved" 1992 "reserved" 1991 "reserved" 1990 "reserved" 1989 "reserved" 1988 "reserved" 1987 "reserved" 1986 "reserved" 1985 "reserved" 1984 "reserved" 1983 "reserved" 1982 "reserved" 1981 "reserved" 1980 "reserved" 1979 "reserved" 1978 "reserved" 1977 "reserved" 1976 "reserved" 1975 "reserved" 1974 "reserved" 1973 "reserved" 1972 "reserved" 1971 "reserved" 1970 "reserved" 1969 "reserved" 1968 "reserved" 1967 "reserved" 1966 "reserved" 1965 "reserved" 1964 "reserved" 1963 "reserved" 1962 "reserved" 1961 "reserved" 1960 "reserved" 1959 "reserved" 1958 "reserved" 1957 "reserved" 1956 "reserved" 1955 "reserved" 1954 "reserved" 1953 "reserved" 1952 "reserved" 1951 "reserved" 1950 "reserved" 1949 "reserved" 1948 "reserved" 1947 "reserved" 1946 "reserved" 1945 "reserved" 1944 "reserved" 1943 "reserved" 1942 "reserved" 1941 "reserved" 1940 "reserved" 1939 "reserved" 1938 "reserved" 1937 "reserved" 1936 "reserved" 1935 "reserved" 1934 "reserved" 1933 "reserved" 1932 "reserved" 1931 "reserved" 1930 "reserved" 1929 "reserved" 1928 "reserved" 1927 "reserved" 1926 "reserved" 1925 "reserved" 1924 "reserved" 1923 "reserved" 1922 "reserved" 1921 "reserved" 1920 "reserved" 1919 "reserved" 1918 "reserved" 1917 "reserved" 1916 "reserved" 1915 "reserved" 1914 "reserved" 1913 "reserved" 1912 "reserved" 1911 "reserved" 1910 "reserved" 1909 "reserved" 1908 "reserved" 1907 "reserved" 1906 "reserved" 1905 "reserved" 1904 "reserved" 1903 "reserved" 1902 "reserved" 1901 "reserved" 1900 "reserved" 1899 "reserved" 1898 "reserved" 1897 "reserved" 1896 "reserved" 1895 "reserved" 1894 "reserved" 1893 "reserved" 1892 "reserved" 1891 "reserved" 1890 "reserved" 1889 "reserved" 1888 "reserved" 1887 "reserved" 1886 "reserved" 1885 "reserved" 1884 "reserved" 1883 "reserved" 1882 "reserved" 1881 "reserved" 1880 "reserved" 1879 "reserved" 1878 "reserved" 1877 "reserved" 1876 "reserved" 1875 "reserved" 1874 "reserved" 1873 "reserved" 1872 "reserved" 1871 "reserved" 1870 "reserved" 1869 "reserved" 1868 "reserved" 1867 "reserved" 1866 "reserved" 1865 "reserved" 1864 "reserved" 1863 "reserved" 1862 "reserved" 1861 "reserved" 1860 "reserved" 1859 "reserved" 1858 "reserved" 1857 "reserved" 1856 "reserved" 1855 "reserved" 1854 "reserved" 1853 "reserved" 1852 "reserved" 1851 "reserved" 1850 "reserved" 1849 "reserved" 1848 "reserved" 1847 "reserved" 1846 "reserved" 1845 "reserved" 1844 "reserved" 1843 "reserved" 1842 "reserved" 1841 "reserved" 1840 "reserved" 1839 "reserved" 1838 "reserved" 1837 "reserved" 1836 "reserved" 1835 "reserved" 1834 "reserved" 1833 "reserved" 1832 "reserved" 1831 "reserved" 1830 "reserved" 1829 "reserved" 1828 "reserved" 1827 "reserved" 1826 "reserved" 1825 "reserved" 1824 "reserved" 1823 "reserved" 1822 "reserved" 1821 "reserved" 1820 "reserved" 1819 "reserved" 1818 "reserved" 1817 "reserved" 1816 "reserved" 1815 "reserved" 1814 "reserved" 1813 "reserved" 1812 "reserved" 1811 "reserved" 1810 "reserved" 1809 "reserved" 1808 "reserved" 1807 "reserved" 1806 "reserved" 1805 "reserved" 1804 "reserved" 1803 "reserved" 1802 "reserved" 1801 "reserved" 1800 "reserved" 1799 "reserved" 1798 "reserved" 1797 "reserved" 1796 "reserved" 1795 "reserved" 1794 "reserved" 1793 "reserved" 1792 "reserved" 1791 "reserved" 1790 "reserved" 1789 "reserved" 1788 "reserved" 1787 "reserved" 1786 "reserved" 1785 "reserved" 1784 "reserved" 1783 "reserved" 1782 "reserved" 1781 "reserved" 1780 "reserved" 1779 "reserved" 1778 "reserved" 1777 "reserved" 1776 "reserved" 1775 "reserved" 1774 "reserved" 1773 "reserved" 1772 "reserved" 1771 "reserved" 1770 "reserved" 1769 "reserved" 1768 "reserved" 1767 "reserved" 1766 "reserved" 1765 "reserved" 1764 "reserved" 1763 "reserved" 1762 "reserved" 1761 "reserved" 1760 "reserved" 1759 "reserved" 1758 "reserved" 1757 "reserved" 1756 "reserved" 1755 "reserved" 1754 "reserved" 1753 "reserved" 1752 "reserved" 1751 "reserved" 1750 "reserved" 1749 "reserved" 1748 "reserved" 1747 "reserved" 1746 "reserved" 1745 "reserved" 1744 "reserved" 1743 "reserved" 1742 "reserved" 1741 "reserved" 1740 "reserved" 1739 "reserved" 1738 "reserved" 1737 "reserved" 1736 "reserved" 1735 "reserved" 1734 "reserved" 1733 "reserved" 1732 "reserved" 1731 "reserved" 1730 "reserved" 1729 "reserved" 1728 "reserved" 1727 "reserved" 1726 "reserved" 1725 "reserved" 1724 "reserved" 1723 "reserved" 1722 "reserved" 1721 "reserved" 1720 "reserved" 1719 "reserved" 1718 "reserved" 1717 "reserved" 1716 "reserved" 1715 "reserved" 1714 "reserved" 1713 "reserved" 1712 "reserved" 1711 "reserved" 1710 "reserved" 1709 "reserved" 1708 "reserved" 1707 "reserved" 1706 "reserved" 1705 "reserved" 1704 "reserved" 1703 "reserved" 1702 "reserved" 1701 "reserved" 1700 "reserved" 1699 "reserved" 1698 "reserved" 1697 "reserved" 1696 "reserved" 1695 "reserved" 1694 "reserved" 1693 "reserved" 1692 "reserved" 1691 "reserved" 1690 "reserved" 1689 "reserved" 1688 "reserved" 1687 "reserved" 1686 "reserved" 1685 "reserved" 1684 "reserved" 1683 "reserved" 1682 "reserved" 1681 "reserved" 1680 "reserved" 1679 "reserved" 1678 "reserved" 1677 "reserved" 1676 "reserved" 1675 "reserved" 1674 "reserved" 1673 "reserved" 1672 "reserved" 1671 "reserved" 1670 "reserved" 1669 "reserved" 1668 "reserved" 1667 "reserved" 1666 "reserved" 1665 "reserved" 1664 "reserved" 1663 "reserved" 1662 "reserved" 1661 "reserved" 1660 "reserved" 1659 "reserved" 1658 "reserved" 1657 "reserved" 1656 "reserved" 1655 "reserved" 1654 "reserved" 1653 "reserved" 1652 "reserved" 1651 "reserved" 1650 "reserved" 1649 "reserved" 1648 "reserved" 1647 "reserved" 1646 "reserved" 1645 "reserved" 1644 "reserved" 1643 "reserved" 1642 "reserved" 1641 "reserved" 1640 "reserved" 1639 "reserved" 1638 "reserved" 1637 "reserved" 1636 "reserved" 1635 "reserved" 1634 "reserved" 1633 "reserved" 1632 "reserved" 1631 "reserved" 1630 "reserved" 1629 "reserved" 1628 "reserved" 1627 "reserved" 1626 "reserved" 1625 "reserved" 1624 "reserved" 1623 "reserved" 1622 "reserved" 1621 "reserved" 1620 "reserved" 1619 "reserved" 1618 "reserved" 1617 "reserved" 1616 "reserved" 1615 "reserved" 1614 "reserved" 1613 "reserved" 1612 "reserved" 1611 "reserved" 1610 "reserved" 1609 "reserved" 1608 "reserved" 1607 "reserved" 1606 "reserved" 1605 "reserved" 1604 "reserved" 1603 "reserved" 1602 "reserved" 1601 "reserved" ;
VAL_ 337 Volume_Nav 2047 "reserved" 2046 "reserved" 2045 "reserved" 2044 "reserved" 2043 "reserved" 2042 "reserved" 2041 "reserved" 2040 "reserved" 2039 "reserved" 2038 "reserved" 2037 "reserved" 2036 "reserved" 2035 "reserved" 2034 "reserved" 2033 "reserved" 2032 "reserved" 2031 "reserved" 2030 "reserved" 2029 "reserved" 2028 "reserved" 2027 "reserved" 2026 "reserved" 2025 "reserved" 2024 "reserved" 2023 "reserved" 2022 "reserved" 2021 "reserved" 2020 "reserved" 2019 "reserved" 2018 "reserved" 2017 "reserved" 2016 "reserved" 2015 "reserved" 2014 "reserved" 2013 "reserved" 2012 "reserved" 2011 "reserved" 2010 "reserved" 2009 "reserved" 2008 "reserved" 2007 "reserved" 2006 "reserved" 2005 "reserved" 2004 "reserved" 2003 "reserved" 2002 "reserved" 2001 "reserved" 2000 "reserved" 1999 "reserved" 1998 "reserved" 1997 "reserved" 1996 "reserved" 1995 "reserved" 1994 "reserved" 1993 "reserved" 1992 "reserved" 1991 "reserved" 1990 "reserved" 1989 "reserved" 1988 "reserved" 1987 "reserved" 1986 "reserved" 1985 "reserved" 1984 "reserved" 1983 "reserved" 1982 "reserved" 1981 "reserved" 1980 "reserved" 1979 "reserved" 1978 "reserved" 1977 "reserved" 1976 "reserved" 1975 "reserved" 1974 "reserved" 1973 "reserved" 1972 "reserved" 1971 "reserved" 1970 "reserved" 1969 "reserved" 1968 "reserved" 1967 "reserved" 1966 "reserved" 1965 "reserved" 1964 "reserved" 1963 "reserved" 1962 "reserved" 1961 "reserved" 1960 "reserved" 1959 "reserved" 1958 "reserved" 1957 "reserved" 1956 "reserved" 1955 "reserved" 1954 "reserved" 1953 "reserved" 1952 "reserved" 1951 "reserved" 1950 "reserved" 1949 "reserved" 1948 "reserved" 1947 "reserved" 1946 "reserved" 1945 "reserved" 1944 "reserved" 1943 "reserved" 1942 "reserved" 1941 "reserved" 1940 "reserved" 1939 "reserved" 1938 "reserved" 1937 "reserved" 1936 "reserved" 1935 "reserved" 1934 "reserved" 1933 "reserved" 1932 "reserved" 1931 "reserved" 1930 "reserved" 1929 "reserved" 1928 "reserved" 1927 "reserved" 1926 "reserved" 1925 "reserved" 1924 "reserved" 1923 "reserved" 1922 "reserved" 1921 "reserved" 1920 "reserved" 1919 "reserved" 1918 "reserved" 1917 "reserved" 1916 "reserved" 1915 "reserved" 1914 "reserved" 1913 "reserved" 1912 "reserved" 1911 "reserved" 1910 "reserved" 1909 "reserved" 1908 "reserved" 1907 "reserved" 1906 "reserved" 1905 "reserved" 1904 "reserved" 1903 "reserved" 1902 "reserved" 1901 "reserved" 1900 "reserved" 1899 "reserved" 1898 "reserved" 1897 "reserved" 1896 "reserved" 1895 "reserved" 1894 "reserved" 1893 "reserved" 1892 "reserved" 1891 "reserved" 1890 "reserved" 1889 "reserved" 1888 "reserved" 1887 "reserved" 1886 "reserved" 1885 "reserved" 1884 "reserved" 1883 "reserved" 1882 "reserved" 1881 "reserved" 1880 "reserved" 1879 "reserved" 1878 "reserved" 1877 "reserved" 1876 "reserved" 1875 "reserved" 1874 "reserved" 1873 "reserved" 1872 "reserved" 1871 "reserved" 1870 "reserved" 1869 "reserved" 1868 "reserved" 1867 "reserved" 1866 "reserved" 1865 "reserved" 1864 "reserved" 1863 "reserved" 1862 "reserved" 1861 "reserved" 1860 "reserved" 1859 "reserved" 1858 "reserved" 1857 "reserved" 1856 "reserved" 1855 "reserved" 1854 "reserved" 1853 "reserved" 1852 "reserved" 1851 "reserved" 1850 "reserved" 1849 "reserved" 1848 "reserved" 1847 "reserved" 1846 "reserved" 1845 "reserved" 1844 "reserved" 1843 "reserved" 1842 "reserved" 1841 "reserved" 1840 "reserved" 1839 "reserved" 1838 "reserved" 1837 "reserved" 1836 "reserved" 1835 "reserved" 1834 "reserved" 1833 "reserved" 1832 "reserved" 1831 "reserved" 1830 "reserved" 1829 "reserved" 1828 "reserved" 1827 "reserved" 1826 "reserved" 1825 "reserved" 1824 "reserved" 1823 "reserved" 1822 "reserved" 1821 "reserved" 1820 "reserved" 1819 "reserved" 1818 "reserved" 1817 "reserved" 1816 "reserved" 1815 "reserved" 1814 "reserved" 1813 "reserved" 1812 "reserved" 1811 "reserved" 1810 "reserved" 1809 "reserved" 1808 "reserved" 1807 "reserved" 1806 "reserved" 1805 "reserved" 1804 "reserved" 1803 "reserved" 1802 "reserved" 1801 "reserved" 1800 "reserved" 1799 "reserved" 1798 "reserved" 1797 "reserved" 1796 "reserved" 1795 "reserved" 1794 "reserved" 1793 "reserved" 1792 "reserved" 1791 "reserved" 1790 "reserved" 1789 "reserved" 1788 "reserved" 1787 "reserved" 1786 "reserved" 1785 "reserved" 1784 "reserved" 1783 "reserved" 1782 "reserved" 1781 "reserved" 1780 "reserved" 1779 "reserved" 1778 "reserved" 1777 "reserved" 1776 "reserved" 1775 "reserved" 1774 "reserved" 1773 "reserved" 1772 "reserved" 1771 "reserved" 1770 "reserved" 1769 "reserved" 1768 "reserved" 1767 "reserved" 1766 "reserved" 1765 "reserved" 1764 "reserved" 1763 "reserved" 1762 "reserved" 1761 "reserved" 1760 "reserved" 1759 "reserved" 1758 "reserved" 1757 "reserved" 1756 "reserved" 1755 "reserved" 1754 "reserved" 1753 "reserved" 1752 "reserved" 1751 "reserved" 1750 "reserved" 1749 "reserved" 1748 "reserved" 1747 "reserved" 1746 "reserved" 1745 "reserved" 1744 "reserved" 1743 "reserved" 1742 "reserved" 1741 "reserved" 1740 "reserved" 1739 "reserved" 1738 "reserved" 1737 "reserved" 1736 "reserved" 1735 "reserved" 1734 "reserved" 1733 "reserved" 1732 "reserved" 1731 "reserved" 1730 "reserved" 1729 "reserved" 1728 "reserved" 1727 "reserved" 1726 "reserved" 1725 "reserved" 1724 "reserved" 1723 "reserved" 1722 "reserved" 1721 "reserved" 1720 "reserved" 1719 "reserved" 1718 "reserved" 1717 "reserved" 1716 "reserved" 1715 "reserved" 1714 "reserved" 1713 "reserved" 1712 "reserved" 1711 "reserved" 1710 "reserved" 1709 "reserved" 1708 "reserved" 1707 "reserved" 1706 "reserved" 1705 "reserved" 1704 "reserved" 1703 "reserved" 1702 "reserved" 1701 "reserved" 1700 "reserved" 1699 "reserved" 1698 "reserved" 1697 "reserved" 1696 "reserved" 1695 "reserved" 1694 "reserved" 1693 "reserved" 1692 "reserved" 1691 "reserved" 1690 "reserved" 1689 "reserved" 1688 "reserved" 1687 "reserved" 1686 "reserved" 1685 "reserved" 1684 "reserved" 1683 "reserved" 1682 "reserved" 1681 "reserved" 1680 "reserved" 1679 "reserved" 1678 "reserved" 1677 "reserved" 1676 "reserved" 1675 "reserved" 1674 "reserved" 1673 "reserved" 1672 "reserved" 1671 "reserved" 1670 "reserved" 1669 "reserved" 1668 "reserved" 1667 "reserved" 1666 "reserved" 1665 "reserved" 1664 "reserved" 1663 "reserved" 1662 "reserved" 1661 "reserved" 1660 "reserved" 1659 "reserved" 1658 "reserved" 1657 "reserved" 1656 "reserved" 1655 "reserved" 1654 "reserved" 1653 "reserved" 1652 "reserved" 1651 "reserved" 1650 "reserved" 1649 "reserved" 1648 "reserved" 1647 "reserved" 1646 "reserved" 1645 "reserved" 1644 "reserved" 1643 "reserved" 1642 "reserved" 1641 "reserved" 1640 "reserved" 1639 "reserved" 1638 "reserved" 1637 "reserved" 1636 "reserved" 1635 "reserved" 1634 "reserved" 1633 "reserved" 1632 "reserved" 1631 "reserved" 1630 "reserved" 1629 "reserved" 1628 "reserved" 1627 "reserved" 1626 "reserved" 1625 "reserved" 1624 "reserved" 1623 "reserved" 1622 "reserved" 1621 "reserved" 1620 "reserved" 1619 "reserved" 1618 "reserved" 1617 "reserved" 1616 "reserved" 1615 "reserved" 1614 "reserved" 1613 "reserved" 1612 "reserved" 1611 "reserved" 1610 "reserved" 1609 "reserved" 1608 "reserved" 1607 "reserved" 1606 "reserved" 1605 "reserved" 1604 "reserved" 1603 "reserved" 1602 "reserved" 1601 "reserved" ;
VAL_ 337 Volume_Phone 1023 "reserved" 1022 "reserved" 1021 "reserved" 1020 "reserved" 1019 "reserved" 1018 "reserved" 1017 "reserved" 1016 "reserved" 1015 "reserved" 1014 "reserved" 1013 "reserved" 1012 "reserved" 1011 "reserved" 1010 "reserved" 1009 "reserved" 1008 "reserved" 1007 "reserved" 1006 "reserved" 1005 "reserved" 1004 "reserved" 1003 "reserved" 1002 "reserved" 1001 "reserved" ;
VAL_ 337 Bass_Level 3 "Others" 2 "Preceding" 1 "Oncoming" 0 "Idle" ;
VAL_ 337 Mid_Level 63 " Not Available" 62 " Initating" 0 " No Object" ;
VAL_ 337 Balance_Fade 12 " β��˫��" 11 " β�Ƶ���" 10 " ǰ��˫��" 9 " ǰ�Ƶ���" 8 " Unknown" 7 " Billboard" 6 " Mixed" 5 " Pedestrain" 4 " Bike" 3 " Bus" 2 " Truck" 1 " Car" 0 " NoVehicle" ;
VAL_ 337 Surround_Level 2047 "reserved" 2046 "reserved" 2045 "reserved" 2044 "reserved" 2043 "reserved" 2042 "reserved" 2041 "reserved" 2040 "reserved" 2039 "reserved" 2038 "reserved" 2037 "reserved" 2036 "reserved" 2035 "reserved" 2034 "reserved" 2033 "reserved" 2032 "reserved" 2031 "reserved" 2030 "reserved" 2029 "reserved" 2028 "reserved" 2027 "reserved" 2026 "reserved" 2025 "reserved" 2024 "reserved" 2023 "reserved" 2022 "reserved" 2021 "reserved" 2020 "reserved" 2019 "reserved" 2018 "reserved" 2017 "reserved" 2016 "reserved" 2015 "reserved" 2014 "reserved" 2013 "reserved" 2012 "reserved" 2011 "reserved" 2010 "reserved" 2009 "reserved" 2008 "reserved" 2007 "reserved" 2006 "reserved" 2005 "reserved" 2004 "reserved" 2003 "reserved" 2002 "reserved" 2001 "reserved" 2000 "reserved" 1999 "reserved" 1998 "reserved" 1997 "reserved" 1996 "reserved" 1995 "reserved" 1994 "reserved" 1993 "reserved" 1992 "reserved" 1991 "reserved" 1990 "reserved" 1989 "reserved" 1988 "reserved" 1987 "reserved" 1986 "reserved" 1985 "reserved" 1984 "reserved" 1983 "reserved" 1982 "reserved" 1981 "reserved" 1980 "reserved" 1979 "reserved" 1978 "reserved" 1977 "reserved" 1976 "reserved" 1975 "reserved" 1974 "reserved" 1973 "reserved" 1972 "reserved" 1971 "reserved" 1970 "reserved" 1969 "reserved" 1968 "reserved" 1967 "reserved" 1966 "reserved" 1965 "reserved" 1964 "reserved" 1963 "reserved" 1962 "reserved" 1961 "reserved" 1960 "reserved" 1959 "reserved" 1958 "reserved" 1957 "reserved" 1956 "reserved" 1955 "reserved" 1954 "reserved" 1953 "reserved" 1952 "reserved" 1951 "reserved" 1950 "reserved" 1949 "reserved" 1948 "reserved" 1947 "reserved" 1946 "reserved" 1945 "reserved" 1944 "reserved" 1943 "reserved" 1942 "reserved" 1941 "reserved" 1940 "reserved" 1939 "reserved" 1938 "reserved" 1937 "reserved" 1936 "reserved" 1935 "reserved" 1934 "reserved" 1933 "reserved" 1932 "reserved" 1931 "reserved" 1930 "reserved" 1929 "reserved" 1928 "reserved" 1927 "reserved" 1926 "reserved" 1925 "reserved" 1924 "reserved" 1923 "reserved" 1922 "reserved" 1921 "reserved" 1920 "reserved" 1919 "reserved" 1918 "reserved" 1917 "reserved" 1916 "reserved" 1915 "reserved" 1914 "reserved" 1913 "reserved" 1912 "reserved" 1911 "reserved" 1910 "reserved" 1909 "reserved" 1908 "reserved" 1907 "reserved" 1906 "reserved" 1905 "reserved" 1904 "reserved" 1903 "reserved" 1902 "reserved" 1901 "reserved" 1900 "reserved" 1899 "reserved" 1898 "reserved" 1897 "reserved" 1896 "reserved" 1895 "reserved" 1894 "reserved" 1893 "reserved" 1892 "reserved" 1891 "reserved" 1890 "reserved" 1889 "reserved" 1888 "reserved" 1887 "reserved" 1886 "reserved" 1885 "reserved" 1884 "reserved" 1883 "reserved" 1882 "reserved" 1881 "reserved" 1880 "reserved" 1879 "reserved" 1878 "reserved" 1877 "reserved" 1876 "reserved" 1875 "reserved" 1874 "reserved" 1873 "reserved" 1872 "reserved" 1871 "reserved" 1870 "reserved" 1869 "reserved" 1868 "reserved" 1867 "reserved" 1866 "reserved" 1865 "reserved" 1864 "reserved" 1863 "reserved" 1862 "reserved" 1861 "reserved" 1860 "reserved" 1859 "reserved" 1858 "reserved" 1857 "reserved" 1856 "reserved" 1855 "reserved" 1854 "reserved" 1853 "reserved" 1852 "reserved" 1851 "reserved" 1850 "reserved" 1849 "reserved" 1848 "reserved" 1847 "reserved" 1846 "reserved" 1845 "reserved" 1844 "reserved" 1843 "reserved" 1842 "reserved" 1841 "reserved" 1840 "reserved" 1839 "reserved" 1838 "reserved" 1837 "reserved" 1836 "reserved" 1835 "reserved" 1834 "reserved" 1833 "reserved" 1832 "reserved" 1831 "reserved" 1830 "reserved" 1829 "reserved" 1828 "reserved" 1827 "reserved" 1826 "reserved" 1825 "reserved" 1824 "reserved" 1823 "reserved" 1822 "reserved" 1821 "reserved" 1820 "reserved" 1819 "reserved" 1818 "reserved" 1817 "reserved" 1816 "reserved" 1815 "reserved" 1814 "reserved" 1813 "reserved" 1812 "reserved" 1811 "reserved" 1810 "reserved" 1809 "reserved" 1808 "reserved" 1807 "reserved" 1806 "reserved" 1805 "reserved" 1804 "reserved" 1803 "reserved" 1802 "reserved" 1801 "reserved" 1800 "reserved" 1799 "reserved" 1798 "reserved" 1797 "reserved" 1796 "reserved" 1795 "reserved" 1794 "reserved" 1793 "reserved" 1792 "reserved" 1791 "reserved" 1790 "reserved" 1789 "reserved" 1788 "reserved" 1787 "reserved" 1786 "reserved" 1785 "reserved" 1784 "reserved" 1783 "reserved" 1782 "reserved" 1781 "reserved" 1780 "reserved" 1779 "reserved" 1778 "reserved" 1777 "reserved" 1776 "reserved" 1775 "reserved" 1774 "reserved" 1773 "reserved" 1772 "reserved" 1771 "reserved" 1770 "reserved" 1769 "reserved" 1768 "reserved" 1767 "reserved" 1766 "reserved" 1765 "reserved" 1764 "reserved" 1763 "reserved" 1762 "reserved" 1761 "reserved" 1760 "reserved" 1759 "reserved" 1758 "reserved" 1757 "reserved" 1756 "reserved" 1755 "reserved" 1754 "reserved" 1753 "reserved" 1752 "reserved" 1751 "reserved" 1750 "reserved" 1749 "reserved" 1748 "reserved" 1747 "reserved" 1746 "reserved" 1745 "reserved" 1744 "reserved" 1743 "reserved" 1742 "reserved" 1741 "reserved" 1740 "reserved" 1739 "reserved" 1738 "reserved" 1737 "reserved" 1736 "reserved" 1735 "reserved" 1734 "reserved" 1733 "reserved" 1732 "reserved" 1731 "reserved" 1730 "reserved" 1729 "reserved" 1728 "reserved" 1727 "reserved" 1726 "reserved" 1725 "reserved" 1724 "reserved" 1723 "reserved" 1722 "reserved" 1721 "reserved" 1720 "reserved" 1719 "reserved" 1718 "reserved" 1717 "reserved" 1716 "reserved" 1715 "reserved" 1714 "reserved" 1713 "reserved" 1712 "reserved" 1711 "reserved" 1710 "reserved" 1709 "reserved" 1708 "reserved" 1707 "reserved" 1706 "reserved" 1705 "reserved" 1704 "reserved" 1703 "reserved" 1702 "reserved" 1701 "reserved" 1700 "reserved" 1699 "reserved" 1698 "reserved" 1697 "reserved" 1696 "reserved" 1695 "reserved" 1694 "reserved" 1693 "reserved" 1692 "reserved" 1691 "reserved" 1690 "reserved" 1689 "reserved" 1688 "reserved" 1687 "reserved" 1686 "reserved" 1685 "reserved" 1684 "reserved" 1683 "reserved" 1682 "reserved" 1681 "reserved" 1680 "reserved" 1679 "reserved" 1678 "reserved" 1677 "reserved" 1676 "reserved" 1675 "reserved" 1674 "reserved" 1673 "reserved" 1672 "reserved" 1671 "reserved" 1670 "reserved" 1669 "reserved" 1668 "reserved" 1667 "reserved" 1666 "reserved" 1665 "reserved" 1664 "reserved" 1663 "reserved" 1662 "reserved" 1661 "reserved" 1660 "reserved" 1659 "reserved" 1658 "reserved" 1657 "reserved" 1656 "reserved" 1655 "reserved" 1654 "reserved" 1653 "reserved" 1652 "reserved" 1651 "reserved" 1650 "reserved" 1649 "reserved" 1648 "reserved" 1647 "reserved" 1646 "reserved" 1645 "reserved" 1644 "reserved" 1643 "reserved" 1642 "reserved" 1641 "reserved" 1640 "reserved" 1639 "reserved" 1638 "reserved" 1637 "reserved" 1636 "reserved" 1635 "reserved" 1634 "reserved" 1633 "reserved" 1632 "reserved" 1631 "reserved" 1630 "reserved" 1629 "reserved" 1628 "reserved" 1627 "reserved" 1626 "reserved" 1625 "reserved" 1624 "reserved" 1623 "reserved" 1622 "reserved" 1621 "reserved" 1620 "reserved" 1619 "reserved" 1618 "reserved" 1617 "reserved" 1616 "reserved" 1615 "reserved" 1614 "reserved" 1613 "reserved" 1612 "reserved" 1611 "reserved" 1610 "reserved" 1609 "reserved" 1608 "reserved" 1607 "reserved" 1606 "reserved" 1605 "reserved" 1604 "reserved" 1603 "reserved" 1602 "reserved" 1601 "reserved" ;
VAL_ 337 EQ_Preset 2047 "reserved" 2046 "reserved" 2045 "reserved" 2044 "reserved" 2043 "reserved" 2042 "reserved" 2041 "reserved" 2040 "reserved" 2039 "reserved" 2038 "reserved" 2037 "reserved" 2036 "reserved" 2035 "reserved" 2034 "reserved" 2033 "reserved" 2032 "reserved" 2031 "reserved" 2030 "reserved" 2029 "reserved" 2028 "reserved" 2027 "reserved" 2026 "reserved" 2025 "reserved" 2024 "reserved" 2023 "reserved" 2022 "reserved" 2021 "reserved" 2020 "reserved" 2019 "reserved" 2018 "reserved" 2017 "reserved" 2016 "reserved" 2015 "reserved" 2014 "reserved" 2013 "reserved" 2012 "reserved" 2011 "reserved" 2010 "reserved" 2009 "reserved" 2008 "reserved" 2007 "reserved" 2006 "reserved" 2005 "reserved" 2004 "reserved" 2003 "reserved" 2002 "reserved" 2001 "reserved" 2000 "reserved" 1999 "reserved" 1998 "reserved" 1997 "reserved" 1996 "reserved" 1995 "reserved" 1994 "reserved" 1993 "reserved" 1992 "reserved" 1991 "reserved" 1990 "reserved" 1989 "reserved" 1988 "reserved" 1987 "reserved" 1986 "reserved" 1985 "reserved" 1984 "reserved" 1983 "reserved" 1982 "reserved" 1981 "reserved" 1980 "reserved" 1979 "reserved" 1978 "reserved" 1977 "reserved" 1976 "reserved" 1975 "reserved" 1974 "reserved" 1973 "reserved" 1972 "reserved" 1971 "reserved" 1970 "reserved" 1969 "reserved" 1968 "reserved" 1967 "reserved" 1966 "reserved" 1965 "reserved" 1964 "reserved" 1963 "reserved" 1962 "reserved" 1961 "reserved" 1960 "reserved" 1959 "reserved" 1958 "reserved" 1957 "reserved" 1956 "reserved" 1955 "reserved" 1954 "reserved" 1953 "reserved" 1952 "reserved" 1951 "reserved" 1950 "reserved" 1949 "reserved" 1948 "reserved" 1947 "reserved" 1946 "reserved" 1945 "reserved" 1944 "reserved" 1943 "reserved" 1942 "reserved" 1941 "reserved" 1940 "reserved" 1939 "reserved" 1938 "reserved" 1937 "reserved" 1936 "reserved" 1935 "reserved" 1934 "reserved" 1933 "reserved" 1932 "reserved" 1931 "reserved" 1930 "reserved" 1929 "reserved" 1928 "reserved" 1927 "reserved" 1926 "reserved" 1925 "reserved" 1924 "reserved" 1923 "reserved" 1922 "reserved" 1921 "reserved" 1920 "reserved" 1919 "reserved" 1918 "reserved" 1917 "reserved" 1916 "reserved" 1915 "reserved" 1914 "reserved" 1913 "reserved" 1912 "reserved" 1911 "reserved" 1910 "reserved" 1909 "reserved" 1908 "reserved" 1907 "reserved" 1906 "reserved" 1905 "reserved" 1904 "reserved" 1903 "reserved" 1902 "reserved" 1901 "reserved" 1900 "reserved" 1899 "reserved" 1898 "reserved" 1897 "reserved" 1896 "reserved" 1895 "reserved" 1894 "reserved" 1893 "reserved" 1892 "reserved" 1891 "reserved" 1890 "reserved" 1889 "reserved" 1888 "reserved" 1887 "reserved" 1886 "reserved" 1885 "reserved" 1884 "reserved" 1883 "reserved" 1882 "reserved" 1881 "reserved" 1880 "reserved" 1879 "reserved" 1878 "reserved" 1877 "reserved" 1876 "reserved" 1875 "reserved" 1874 "reserved" 1873 "reserved" 1872 "reserved" 1871 "reserved" 1870 "reserved" 1869 "reserved" 1868 "reserved" 1867 "reserved" 1866 "reserved" 1865 "reserved" 1864 "reserved" 1863 "reserved" 1862 "reserved" 1861 "reserved" 1860 "reserved" 1859 "reserved" 1858 "reserved" 1857 "reserved" 1856 "reserved" 1855 "reserved" 1854 "reserved" 1853 "reserved" 1852 "reserved" 1851 "reserved" 1850 "reserved" 1849 "reserved" 1848 "reserved" 1847 "reserved" 1846 "reserved" 1845 "reserved" 1844 "reserved" 1843 "reserved" 1842 "reserved" 1841 "reserved" 1840 "reserved" 1839 "reserved" 1838 "reserved" 1837 "reserved" 1836 "reserved" 1835 "reserved" 1834 "reserved" 1833 "reserved" 1832 "reserved" 1831 "reserved" 1830 "reserved" 1829 "reserved" 1828 "reserved" 1827 "reserved" 1826 "reserved" 1825 "reserved" 1824 "reserved" 1823 "reserved" 1822 "reserved" 1821 "reserved" 1820 "reserved" 1819 "reserved" 1818 "reserved" 1817 "reserved" 1816 "reserved" 1815 "reserved" 1814 "reserved" 1813 "reserved" 1812 "reserved" 1811 "reserved" 1810 "reserved" 1809 "reserved" 1808 "reserved" 1807 "reserved" 1806 "reserved" 1805 "reserved" 1804 "reserved" 1803 "reserved" 1802 "reserved" 1801 "reserved" 1800 "reserved" 1799 "reserved" 1798 "reserved" 1797 "reserved" 1796 "reserved" 1795 "reserved" 1794 "reserved" 1793 "reserved" 1792 "reserved" 1791 "reserved" 1790 "reserved" 1789 "reserved" 1788 "reserved" 1787 "reserved" 1786 "reserved" 1785 "reserved" 1784 "reserved" 1783 "reserved" 1782 "reserved" 1781 "reserved" 1780 "reserved" 1779 "reserved" 1778 "reserved" 1777 "reserved" 1776 "reserved" 1775 "reserved" 1774 "reserved" 1773 "reserved" 1772 "reserved" 1771 "reserved" 1770 "reserved" 1769 "reserved" 1768 "reserved" 1767 "reserved" 1766 "reserved" 1765 "reserved" 1764 "reserved" 1763 "reserved" 1762 "reserved" 1761 "reserved" 1760 "reserved" 1759 "reserved" 1758 "reserved" 1757 "reserved" 1756 "reserved" 1755 "reserved" 1754 "reserved" 1753 "reserved" 1752 "reserved" 1751 "reserved" 1750 "reserved" 1749 "reserved" 1748 "reserved" 1747 "reserved" 1746 "reserved" 1745 "reserved" 1744 "reserved" 1743 "reserved" 1742 "reserved" 1741 "reserved" 1740 "reserved" 1739 "reserved" 1738 "reserved" 1737 "reserved" 1736 "reserved" 1735 "reserved" 1734 "reserved" 1733 "reserved" 1732 "reserved" 1731 "reserved" 1730 "reserved" 1729 "reserved" 1728 "reserved" 1727 "reserved" 1726 "reserved" 1725 "reserved" 1724 "reserved" 1723 "reserved" 1722 "reserved" 1721 "reserved" 1720 "reserved" 1719 "reserved" 1718 "reserved" 1717 "reserved" 1716 "reserved" 1715 "reserved" 1714 "reserved" 1713 "reserved" 1712 "reserved" 1711 "reserved" 1710 "reserved" 1709 "reserved" 1708 "reserved" 1707 "reserved" 1706 "reserved" 1705 "reserved" 1704 "reserved" 1703 "reserved" 1702 "reserved" 1701 "reserved" 1700 "reserved" 1699 "reserved" 1698 "reserved" 1697 "reserved" 1696 "reserved" 1695 "reserved" 1694 "reserved" 1693 "reserved" 1692 "reserved" 1691 "reserved" 1690 "reserved" 1689 "reserved" 1688 "reserved" 1687 "reserved" 1686 "reserved" 1685 "reserved" 1684 "reserved" 1683 "reserved" 1682 "reserved" 1681 "reserved" 1680 "reserved" 1679 "reserved" 1678 "reserved" 1677 "reserved" 1676 "reserved" 1675 "reserved" 1674 "reserved" 1673 "reserved" 1672 "reserved" 1671 "reserved" 1670 "reserved" 1669 "reserved" 1668 "reserved" 1667 "reserved" 1666 "reserved" 1665 "reserved" 1664 "reserved" 1663 "reserved" 1662 "reserved" 1661 "reserved" 1660 "reserved" 1659 "reserved" 1658 "reserved" 1657 "reserved" 1656 "reserved" 1655 "reserved" 1654 "reserved" 1653 "reserved" 1652 "reserved" 1651 "reserved" 1650 "reserved" 1649 "reserved" 1648 "reserved" 1647 "reserved" 1646 "reserved" 1645 "reserved" 1644 "reserved" 1643 "reserved" 1642 "reserved" 1641 "reserved" 1640 "reserved" 1639 "reserved" 1638 "reserved" 1637 "reserved" 1636 "reserved" 1635 "reserved" 1634 "reserved" 1633 "reserved" 1632 "reserved" 1631 "reserved" 1630 "reserved" 1629 "reserved" 1628 "reserved" 1627 "reserved" 1626 "reserved" 1625 "reserved" 1624 "reserved" 1623 "reserved" 1622 "reserved" 1621 "reserved" 1620 "reserved" 1619 "reserved" 1618 "reserved" 1617 "reserved" 1616 "reserved" 1615 "reserved" 1614 "reserved" 1613 "reserved" 1612 "reserved" 1611 "reserved" 1610 "reserved" 1609 "reserved" 1608 "reserved" 1607 "reserved" 1606 "reserved" 1605 "reserved" 1604 "reserved" 1603 "reserved" 1602 "reserved" 1601 "reserved" ;
VAL_ 337 EQ_Custom 1023 "reserved" 1022 "reserved" 1021 "reserved" 1020 "reserved" 1019 "reserved" 1018 "reserved" 1017 "reserved" 1016 "reserved" 1015 "reserved" 1014 "reserved" 1013 "reserved" 1012 "reserved" 1011 "reserved" 1010 "reserved" 1009 "reserved" 1008 "reserved" 1007 "reserved" 1006 "reserved" 1005 "reserved" 1004 "reserved" 1003 "reserved" 1002 "reserved" 1001 "reserved" ;
VAL_ 337 Loudness_On 3 "Others" 2 "Preceding" 1 "Oncoming" 0 "Idle" ;
VAL_ 338 Media3_CRC 63 " Not Available" 62 " Initating" 0 " No Object" ;
VAL_ 338 Media3_RollCnt 12 " β��˫��" 11 " β�Ƶ���" 10 " ǰ��˫��" 9 " ǰ�Ƶ���" 8 " Unknown" 7 " Billboard" 6 " Mixed" 5 " Pedestrain" 4 " Bike" 3 " Bus" 2 " Truck" 1 " Car" 0 " NoVehicle" ;
VAL_ 338 Nav_ZoomOut 2047 "reserved" 2046 "reserved" 2045 "reserved" 2044 "reserved" 2043 "reserved" 2042 "reserved" 2041 "reserved" 2040 "reserved" 2039 "reserved" 2038 "reserved" 2037 "reserved" 2036 "reserved" 2035 "reserved" 2034 "reserved" 2033 "reserved" 2032 "reserved" 2031 "reserved" 2030 "reserved" 2029 "reserved" 2028 "reserved" 2027 "reserved" 2026 "reserved" 2025 "reserved" 2024 "reserved" 2023 "reserved" 2022 "reserved" 2021 "reserved" 2020 "reserved" 2019 "reserved" 2018 "reserved" 2017 "reserved" 2016 "reserved" 2015 "reserved" 2014 "reserved" 2013 "reserved" 2012 "reserved" 2011 "reserved" 2010 "reserved" 2009 "reserved" 2008 "reserved" 2007 "reserved" 2006 "reserved" 2005 "reserved" 2004 "reserved" 2003 "reserved" 2002 "reserved" 2001 "reserved" 2000 "reserved" 1999 "reserved" 1998 "reserved" 1997 "reserved" 1996 "reserved" 1995 "reserved" 1994 "reserved" 1993 "reserved" 1992 "reserved" 1991 "reserved" 1990 "reserved" 1989 "reserved" 1988 "reserved" 1987 "reserved" 1986 "reserved" 1985 "reserved" 1984 "reserved" 1983 "reserved" 1982 "reserved" 1981 "reserved" 1980 "reserved" 1979 "reserved" 1978 "reserved" 1977 "reserved" 1976 "reserved" 1975 "reserved" 1974 "reserved" 1973 "reserved" 1972 "reserved" 1971 "reserved" 1970 "reserved" 1969 "reserved" 1968 "reserved" 1967 "reserved" 1966 "reserved" 1965 "reserved" 1964 "reserved" 1963 "reserved" 1962 "reserved" 1961 "reserved" 1960 "reserved" 1959 "reserved" 1958 "reserved" 1957 "reserved" 1956 "reserved" 1955 "reserved" 1954 "reserved" 1953 "reserved" 1952 "reserved" 1951 "reserved" 1950 "reserved" 1949 "reserved" 1948 "reserved" 1947 "reserved" 1946 "reserved" 1945 "reserved" 1944 "reserved" 1943 "reserved" 1942 "reserved" 1941 "reserved" 1940 "reserved" 1939 "reserved" 1938 "reserved" 1937 "reserved" 1936 "reserved" 1935 "reserved" 1934 "reserved" 1933 "reserved" 1932 "reserved" 1931 "reserved" 1930 "reserved" 1929 "reserved" 1928 "reserved" 1927 "reserved" 1926 "reserved" 1925 "reserved" 1924 "reserved" 1923 "reserved" 1922 "reserved" 1921 "reserved" 1920 "reserved" 1919 "reserved" 1918 "reserved" 1917 "reserved" 1916 "reserved" 1915 "reserved" 1914 "reserved" 1913 "reserved" 1912 "reserved" 1911 "reserved" 1910 "reserved" 1909 "reserved" 1908 "reserved" 1907 "reserved" 1906 "reserved" 1905 "reserved" 1904 "reserved" 1903 "reserved" 1902 "reserved" 1901 "reserved" 1900 "reserved" 1899 "reserved" 1898 "reserved" 1897 "reserved" 1896 "reserved" 1895 "reserved" 1894 "reserved" 1893 "reserved" 1892 "reserved" 1891 "reserved" 1890 "reserved" 1889 "reserved" 1888 "reserved" 1887 "reserved" 1886 "reserved" 1885 "reserved" 1884 "reserved" 1883 "reserved" 1882 "reserved" 1881 "reserved" 1880 "reserved" 1879 "reserved" 1878 "reserved" 1877 "reserved" 1876 "reserved" 1875 "reserved" 1874 "reserved" 1873 "reserved" 1872 "reserved" 1871 "reserved" 1870 "reserved" 1869 "reserved" 1868 "reserved" 1867 "reserved" 1866 "reserved" 1865 "reserved" 1864 "reserved" 1863 "reserved" 1862 "reserved" 1861 "reserved" 1860 "reserved" 1859 "reserved" 1858 "reserved" 1857 "reserved" 1856 "reserved" 1855 "reserved" 1854 "reserved" 1853 "reserved" 1852 "reserved" 1851 "reserved" 1850 "reserved" 1849 "reserved" 1848 "reserved" 1847 "reserved" 1846 "reserved" 1845 "reserved" 1844 "reserved" 1843 "reserved" 1842 "reserved" 1841 "reserved" 1840 "reserved" 1839 "reserved" 1838 "reserved" 1837 "reserved" 1836 "reserved" 1835 "reserved" 1834 "reserved" 1833 "reserved" 1832 "reserved" 1831 "reserved" 1830 "reserved" 1829 "reserved" 1828 "reserved" 1827 "reserved" 1826 "reserved" 1825 "reserved" 1824 "reserved" 1823 "reserved" 1822 "reserved" 1821 "reserved" 1820 "reserved" 1819 "reserved" 1818 "reserved" 1817 "reserved" 1816 "reserved" 1815 "reserved" 1814 "reserved" 1813 "reserved" 1812 "reserved" 1811 "reserved" 1810 "reserved" 1809 "reserved" 1808 "reserved" 1807 "reserved" 1806 "reserved" 1805 "reserved" 1804 "reserved" 1803 "reserved" 1802 "reserved" 1801 "reserved" 1800 "reserved" 1799 "reserved" 1798 "reserved" 1797 "reserved" 1796 "reserved" 1795 "reserved" 1794 "reserved" 1793 "reserved" 1792 "reserved" 1791 "reserved" 1790 "reserved" 1789 "reserved" 1788 "reserved" 1787 "reserved" 1786 "reserved" 1785 "reserved" 1784 "reserved" 1783 "reserved" 1782 "reserved" 1781 "reserved" 1780 "reserved" 1779 "reserved" 1778 "reserved" 1777 "reserved" 1776 "reserved" 1775 "reserved" 1774 "reserved" 1773 "reserved" 1772 "reserved" 1771 "reserved" 1770 "reserved" 1769 "reserved" 1768 "reserved" 1767 "reserved" 1766 "reserved" 1765 "reserved" 1764 "reserved" 1763 "reserved" 1762 "reserved" 1761 "reserved" 1760 "reserved" 1759 "reserved" 1758 "reserved" 1757 "reserved" 1756 "reserved" 1755 "reserved" 1754 "reserved" 1753 "reserved" 1752 "reserved" 1751 "reserved" 1750 "reserved" 1749 "reserved" 1748 "reserved" 1747 "reserved" 1746 "reserved" 1745 "reserved" 1744 "reserved" 1743 "reserved" 1742 "reserved" 1741 "reserved" 1740 "reserved" 1739 "reserved" 1738 "reserved" 1737 "reserved" 1736 "reserved" 1735 "reserved" 1734 "reserved" 1733 "reserved" 1732 "reserved" 1731 "reserved" 1730 "reserved" 1729 "reserved" 1728 "reserved" 1727 "reserved" 1726 "reserved" 1725 "reserved" 1724 "reserved" 1723 "reserved" 1722 "reserved" 1721 "reserved" 1720 "reserved" 1719 "reserved" 1718 "reserved" 1717 "reserved" 1716 "reserved" 1715 "reserved" 1714 "reserved" 1713 "reserved" 1712 "reserved" 1711 "reserved" 1710 "reserved" 1709 "reserved" 1708 "reserved" 1707 "reserved" 1706 "reserved" 1705 "reserved" 1704 "reserved" 1703 "reserved" 1702 "reserved" 1701 "reserved" 1700 "reserved" 1699 "reserved" 1698 "reserved" 1697 "reserved" 1696 "reserved" 1695 "reserved" 1694 "reserved" 1693 "reserved" 1692 "reserved" 1691 "reserved" 1690 "reserved" 1689 "reserved" 1688 "reserved" 1687 "reserved" 1686 "reserved" 1685 "reserved" 1684 "reserved" 1683 "reserved" 1682 "reserved" 1681 "reserved" 1680 "reserved" 1679 "reserved" 1678 "reserved" 1677 "reserved" 1676 "reserved" 1675 "reserved" 1674 "reserved" 1673 "reserved" 1672 "reserved" 1671 "reserved" 1670 "reserved" 1669 "reserved" 1668 "reserved" 1667 "reserved" 1666 "reserved" 1665 "reserved" 1664 "reserved" 1663 "reserved" 1662 "reserved" 1661 "reserved" 1660 "reserved" 1659 "reserved" 1658 "reserved" 1657 "reserved" 1656 "reserved" 1655 "reserved" 1654 "reserved" 1653 "reserved" 1652 "reserved" 1651 "reserved" 1650 "reserved" 1649 "reserved" 1648 "reserved" 1647 "reserved" 1646 "reserved" 1645 "reserved" 1644 "reserved" 1643 "reserved" 1642 "reserved" 1641 "reserved" 1640 "reserved" 1639 "reserved" 1638 "reserved" 1637 "reserved" 1636 "reserved" 1635 "reserved" 1634 "reserved" 1633 "reserved" 1632 "reserved" 1631 "reserved" 1630 "reserved" 1629 "reserved" 1628 "reserved" 1627 "reserved" 1626 "reserved" 1625 "reserved" 1624 "reserved" 1623 "reserved" 1622 "reserved" 1621 "reserved" 1620 "reserved" 1619 "reserved" 1618 "reserved" 1617 "reserved" 1616 "reserved" 1615 "reserved" 1614 "reserved" 1613 "reserved" 1612 "reserved" 1611 "reserved" 1610 "reserved" 1609 "reserved" 1608 "reserved" 1607 "reserved" 1606 "reserved" 1605 "reserved" 1604 "reserved" 1603 "reserved" 1602 "reserved" 1601 "reserved" ;
VAL_ 338 Nav_Menu 2047 "reserved" 2046 "reserved" 2045 "reserved" 2044 "reserved" 2043 "reserved" 2042 "reserved" 2041 "reserved" 2040 "reserved" 2039 "reserved" 2038 "reserved" 2037 "reserved" 2036 "reserved" 2035 "reserved" 2034 "reserved" 2033 "reserved" 2032 "reserved" 2031 "reserved" 2030 "reserved" 2029 "reserved" 2028 "reserved" 2027 "reserved" 2026 "reserved" 2025 "reserved" 2024 "reserved" 2023 "reserved" 2022 "reserved" 2021 "reserved" 2020 "reserved" 2019 "reserved" 2018 "reserved" 2017 "reserved" 2016 "reserved" 2015 "reserved" 2014 "reserved" 2013 "reserved" 2012 "reserved" 2011 "reserved" 2010 "reserved" 2009 "reserved" 2008 "reserved" 2007 "reserved" 2006 "reserved" 2005 "reserved" 2004 "reserved" 2003 "reserved" 2002 "reserved" 2001 "reserved" 2000 "reserved" 1999 "reserved" 1998 "reserved" 1997 "reserved" 1996 "reserved" 1995 "reserved" 1994 "reserved" 1993 "reserved" 1992 "reserved" 1991 "reserved" 1990 "reserved" 1989 "reserved" 1988 "reserved" 1987 "reserved" 1986 "reserved" 1985 "reserved" 1984 "reserved" 1983 "reserved" 1982 "reserved" 1981 "reserved" 1980 "reserved" 1979 "reserved" 1978 "reserved" 1977 "reserved" 1976 "reserved" 1975 "reserved" 1974 "reserved" 1973 "reserved" 1972 "reserved" 1971 "reserved" 1970 "reserved" 1969 "reserved" 1968 "reserved" 1967 "reserved" 1966 "reserved" 1965 "reserved" 1964 "reserved" 1963 "reserved" 1962 "reserved" 1961 "reserved" 1960 "reserved" 1959 "reserved" 1958 "reserved" 1957 "reserved" 1956 "reserved" 1955 "reserved" 1954 "reserved" 1953 "reserved" 1952 "reserved" 1951 "reserved" 1950 "reserved" 1949 "reserved" 1948 "reserved" 1947 "reserved" 1946 "reserved" 1945 "reserved" 1944 "reserved" 1943 "reserved" 1942 "reserved" 1941 "reserved" 1940 "reserved" 1939 "reserved" 1938 "reserved" 1937 "reserved" 1936 "reserved" 1935 "reserved" 1934 "reserved" 1933 "reserved" 1932 "reserved" 1931 "reserved" 1930 "reserved" 1929 "reserved" 1928 "reserved" 1927 "reserved" 1926 "reserved" 1925 "reserved" 1924 "reserved" 1923 "reserved" 1922 "reserved" 1921 "reserved" 1920 "reserved" 1919 "reserved" 1918 "reserved" 1917 "reserved" 1916 "reserved" 1915 "reserved" 1914 "reserved" 1913 "reserved" 1912 "reserved" 1911 "reserved" 1910 "reserved" 1909 "reserved" 1908 "reserved" 1907 "reserved" 1906 "reserved" 1905 "reserved" 1904 "reserved" 1903 "reserved" 1902 "reserved" 1901 "reserved" 1900 "reserved" 1899 "reserved" 1898 "reserved" 1897 "reserved" 1896 "reserved" 1895 "reserved" 1894 "reserved" 1893 "reserved" 1892 "reserved" 1891 "reserved" 1890 "reserved" 1889 "reserved" 1888 "reserved" 1887 "reserved" 1886 "reserved" 1885 "reserved" 1884 "reserved" 1883 "reserved" 1882 "reserved" 1881 "reserved" 1880 "reserved" 1879 "reserved" 1878 "reserved" 1877 "reserved" 1876 "reserved" 1875 "reserved" 1874 "reserved" 1873 "reserved" 1872 "reserved" 1871 "reserved" 1870 "reserved" 1869 "reserved" 1868 "reserved" 1867 "reserved" 1866 "reserved" 1865 "reserved" 1864 "reserved" 1863 "reserved" 1862 "reserved" 1861 "reserved" 1860 "reserved" 1859 "reserved" 1858 "reserved" 1857 "reserved" 1856 "reserved" 1855 "reserved" 1854 "reserved" 1853 "reserved" 1852 "reserved" 1851 "reserved" 1850 "reserved" 1849 "reserved" 1848 "reserved" 1847 "reserved" 1846 "reserved" 1845 "reserved" 1844 "reserved" 1843 "reserved" 1842 "reserved" 1841 "reserved" 1840 "reserved" 1839 "reserved" 1838 "reserved" 1837 "reserved" 1836 "reserved" 1835 "reserved" 1834 "reserved" 1833 "reserved" 1832 "reserved" 1831 "reserved" 1830 "reserved" 1829 "reserved" 1828 "reserved" 1827 "reserved" 1826 "reserved" 1825 "reserved" 1824 "reserved" 1823 "reserved" 1822 "reserved" 1821 "reserved" 1820 "reserved" 1819 "reserved" 1818 "reserved" 1817 "reserved" 1816 "reserved" 1815 "reserved" 1814 "reserved" 1813 "reserved" 1812 "reserved" 1811 "reserved" 1810 "reserved" 1809 "reserved" 1808 "reserved" 1807 "reserved" 1806 "reserved" 1805 "reserved" 1804 "reserved" 1803 "reserved" 1802 "reserved" 1801 "reserved" 1800 "reserved" 1799 "reserved" 1798 "reserved" 1797 "reserved" 1796 "reserved" 1795 "reserved" 1794 "reserved" 1793 "reserved" 1792 "reserved" 1791 "reserved" 1790 "reserved" 1789 "reserved" 1788 "reserved" 1787 "reserved" 1786 "reserved" 1785 "reserved" 1784 "reserved" 1783 "reserved" 1782 "reserved" 1781 "reserved" 1780 "reserved" 1779 "reserved" 1778 "reserved" 1777 "reserved" 1776 "reserved" 1775 "reserved" 1774 "reserved" 1773 "reserved" 1772 "reserved" 1771 "reserved" 1770 "reserved" 1769 "reserved" 1768 "reserved" 1767 "reserved" 1766 "reserved" 1765 "reserved" 1764 "reserved" 1763 "reserved" 1762 "reserved" 1761 "reserved" 1760 "reserved" 1759 "reserved" 1758 "reserved" 1757 "reserved" 1756 "reserved" 1755 "reserved" 1754 "reserved" 1753 "reserved" 1752 "reserved" 1751 "reserved" 1750 "reserved" 1749 "reserved" 1748 "reserved" 1747 "reserved" 1746 "reserved" 1745 "reserved" 1744 "reserved" 1743 "reserved" 1742 "reserved" 1741 "reserved" 1740 "reserved" 1739 "reserved" 1738 "reserved" 1737 "reserved" 1736 "reserved" 1735 "reserved" 1734 "reserved" 1733 "reserved" 1732 "reserved" 1731 "reserved" 1730 "reserved" 1729 "reserved" 1728 "reserved" 1727 "reserved" 1726 "reserved" 1725 "reserved" 1724 "reserved" 1723 "reserved" 1722 "reserved" 1721 "reserved" 1720 "reserved" 1719 "reserved" 1718 "reserved" 1717 "reserved" 1716 "reserved" 1715 "reserved" 1714 "reserved" 1713 "reserved" 1712 "reserved" 1711 "reserved" 1710 "reserved" 1709 "reserved" 1708 "reserved" 1707 "reserved" 1706 "reserved" 1705 "reserved" 1704 "reserved" 1703 "reserved" 1702 "reserved" 1701 "reserved" 1700 "reserved" 1699 "reserved" 1698 "reserved" 1697 "reserved" 1696 "reserved" 1695 "reserved" 1694 "reserved" 1693 "reserved" 1692 "reserved" 1691 "reserved" 1690 "reserved" 1689 "reserved" 1688 "reserved" 1687 "reserved" 1686 "reserved" 1685 "reserved" 1684 "reserved" 1683 "reserved" 1682 "reserved" 1681 "reserved" 1680 "reserved" 1679 "reserved" 1678 "reserved" 1677 "reserved" 1676 "reserved" 1675 "reserved" 1674 "reserved" 1673 "reserved" 1672 "reserved" 1671 "reserved" 1670 "reserved" 1669 "reserved" 1668 "reserved" 1667 "reserved" 1666 "reserved" 1665 "reserved" 1664 "reserved" 1663 "reserved" 1662 "reserved" 1661 "reserved" 1660 "reserved" 1659 "reserved" 1658 "reserved" 1657 "reserved" 1656 "reserved" 1655 "reserved" 1654 "reserved" 1653 "reserved" 1652 "reserved" 1651 "reserved" 1650 "reserved" 1649 "reserved" 1648 "reserved" 1647 "reserved" 1646 "reserved" 1645 "reserved" 1644 "reserved" 1643 "reserved" 1642 "reserved" 1641 "reserved" 1640 "reserved" 1639 "reserved" 1638 "reserved" 1637 "reserved" 1636 "reserved" 1635 "reserved" 1634 "reserved" 1633 "reserved" 1632 "reserved" 1631 "reserved" 1630 "reserved" 1629 "reserved" 1628 "reserved" 1627 "reserved" 1626 "reserved" 1625 "reserved" 1624 "reserved" 1623 "reserved" 1622 "reserved" 1621 "reserved" 1620 "reserved" 1619 "reserved" 1618 "reserved" 1617 "reserved" 1616 "reserved" 1615 "reserved" 1614 "reserved" 1613 "reserved" 1612 "reserved" 1611 "reserved" 1610 "reserved" 1609 "reserved" 1608 "reserved" 1607 "reserved" 1606 "reserved" 1605 "reserved" 1604 "reserved" 1603 "reserved" 1602 "reserved" 1601 "reserved" ;
VAL_ 338 Nav_Favorite 1023 "reserved" 1022 "reserved" 1021 "reserved" 1020 "reserved" 1019 "reserved" 1018 "reserved" 1017 "reserved" 1016 "reserved" 1015 "reserved" 1014 "reserved" 1013 "reserved" 1012 "reserved" 1011 "reserved" 1010 "reserved" 1009 "reserved" 1008 "reserved" 1007 "reserved" 1006 "reserved" 1005 "reserved" 1004 "reserved" 1003 "reserved" 1002 "reserved" 1001 "reserved" ;
VAL_ 338 Nav_Home 3 "Others" 2 "Preceding" 1 "Oncoming" 0 "Idle" ;
VAL_ 338 Nav_RouteCalc 63 " Not Available" 62 " Initating" 0 " No Object" ;
VAL_ 338 Nav_MuteGuidance 12 " β��˫��" 11 " β�Ƶ���" 10 " ǰ��˫��" 9 " ǰ�Ƶ���" 8 " Unknown" 7 " Billboard" 6 " Mixed" 5 " Pedestrain" 4 " Bike" 3 " Bus" 2 " Truck" 1 " Car" 0 " NoVehicle" ;
VAL_ 338 Map_DayNight 2047 "reserved" 2046 "reserved" 2045 "reserved" 2044 "reserved" 2043 "reserved" 2042 "reserved" 2041 "reserved" 2040 "reserved" 2039 "reserved" 2038 "reserved" 2037 "reserved" 2036 "reserved" 2035 "reserved" 2034 "reserved" 2033 "reserved" 2032 "reserved" 2031 "reserved" 2030 "reserved" 2029 "reserved" 2028 "reserved" 2027 "reserved" 2026 "reserved" 2025 "reserved" 2024 "reserved" 2023 "reserved" 2022 "reserved" 2021 "reserved" 2020 "reserved" 2019 "reserved" 2018 "reserved" 2017 "reserved" 2016 "reserved" 2015 "reserved" 2014 "reserved" 2013 "reserved" 2012 "reserved" 2011 "reserved" 2010 "reserved" 2009 "reserved" 2008 "reserved" 2007 "reserved" 2006 "reserved" 2005 "reserved" 2004 "reserved" 2003 "reserved" 2002 "reserved" 2001 "reserved" 2000 "reserved" 1999 "reserved" 1998 "reserved" 1997 "reserved" 1996 "reserved" 1995 "reserved" 1994 "reserved" 1993 "reserved" 1992 "reserved" 1991 "reserved" 1990 "reserved" 1989 "reserved" 1988 "reserved" 1987 "reserved" 1986 "reserved" 1985 "reserved" 1984 "reserved" 1983 "reserved" 1982 "reserved" 1981 "reserved" 1980 "reserved" 1979 "reserved" 1978 "reserved" 1977 "reserved" 1976 "reserved" 1975 "reserved" 1974 "reserved" 1973 "reserved" 1972 "reserved" 1971 "reserved" 1970 "reserved" 1969 "reserved" 1968 "reserved" 1967 "reserved" 1966 "reserved" 1965 "reserved" 1964 "reserved" 1963 "reserved" 1962 "reserved" 1961 "reserved" 1960 "reserved" 1959 "reserved" 1958 "reserved" 1957 "reserved" 1956 "reserved" 1955 "reserved" 1954 "reserved" 1953 "reserved" 1952 "reserved" 1951 "reserved" 1950 "reserved" 1949 "reserved" 1948 "reserved" 1947 "reserved" 1946 "reserved" 1945 "reserved" 1944 "reserved" 1943 "reserved" 1942 "reserved" 1941 "reserved" 1940 "reserved" 1939 "reserved" 1938 "reserved" 1937 "reserved" 1936 "reserved" 1935 "reserved" 1934 "reserved" 1933 "reserved" 1932 "reserved" 1931 "reserved" 1930 "reserved" 1929 "reserved" 1928 "reserved" 1927 "reserved" 1926 "reserved" 1925 "reserved" 1924 "reserved" 1923 "reserved" 1922 "reserved" 1921 "reserved" 1920 "reserved" 1919 "reserved" 1918 "reserved" 1917 "reserved" 1916 "reserved" 1915 "reserved" 1914 "reserved" 1913 "reserved" 1912 "reserved" 1911 "reserved" 1910 "reserved" 1909 "reserved" 1908 "reserved" 1907 "reserved" 1906 "reserved" 1905 "reserved" 1904 "reserved" 1903 "reserved" 1902 "reserved" 1901 "reserved" 1900 "reserved" 1899 "reserved" 1898 "reserved" 1897 "reserved" 1896 "reserved" 1895 "reserved" 1894 "reserved" 1893 "reserved" 1892 "reserved" 1891 "reserved" 1890 "reserved" 1889 "reserved" 1888 "reserved" 1887 "reserved" 1886 "reserved" 1885 "reserved" 1884 "reserved" 1883 "reserved" 1882 "reserved" 1881 "reserved" 1880 "reserved" 1879 "reserved" 1878 "reserved" 1877 "reserved" 1876 "reserved" 1875 "reserved" 1874 "reserved" 1873 "reserved" 1872 "reserved" 1871 "reserved" 1870 "reserved" 1869 "reserved" 1868 "reserved" 1867 "reserved" 1866 "reserved" 1865 "reserved" 1864 "reserved" 1863 "reserved" 1862 "reserved" 1861 "reserved" 1860 "reserved" 1859 "reserved" 1858 "reserved" 1857 "reserved" 1856 "reserved" 1855 "reserved" 1854 "reserved" 1853 "reserved" 1852 "reserved" 1851 "reserved" 1850 "reserved" 1849 "reserved" 1848 "reserved" 1847 "reserved" 1846 "reserved" 1845 "reserved" 1844 "reserved" 1843 "reserved" 1842 "reserved" 1841 "reserved" 1840 "reserved" 1839 "reserved" 1838 "reserved" 1837 "reserved" 1836 "reserved" 1835 "reserved" 1834 "reserved" 1833 "reserved" 1832 "reserved" 1831 "reserved" 1830 "reserved" 1829 "reserved" 1828 "reserved" 1827 "reserved" 1826 "reserved" 1825 "reserved" 1824 "reserved" 1823 "reserved" 1822 "reserved" 1821 "reserved" 1820 "reserved" 1819 "reserved" 1818 "reserved" 1817 "reserved" 1816 "reserved" 1815 "reserved" 1814 "reserved" 1813 "reserved" 1812 "reserved" 1811 "reserved" 1810 "reserved" 1809 "reserved" 1808 "reserved" 1807 "reserved" 1806 "reserved" 1805 "reserved" 1804 "reserved" 1803 "reserved" 1802 "reserved" 1801 "reserved" 1800 "reserved" 1799 "reserved" 1798 "reserved" 1797 "reserved" 1796 "reserved" 1795 "reserved" 1794 "reserved" 1793 "reserved" 1792 "reserved" 1791 "reserved" 1790 "reserved" 1789 "reserved" 1788 "reserved" 1787 "reserved" 1786 "reserved" 1785 "reserved" 1784 "reserved" 1783 "reserved" 1782 "reserved" 1781 "reserved" 1780 "reserved" 1779 "reserved" 1778 "reserved" 1777 "reserved" 1776 "reserved" 1775 "reserved" 1774 "reserved" 1773 "reserved" 1772 "reserved" 1771 "reserved" 1770 "reserved" 1769 "reserved" 1768 "reserved" 1767 "reserved" 1766 "reserved" 1765 "reserved" 1764 "reserved" 1763 "reserved" 1762 "reserved" 1761 "reserved" 1760 "reserved" 1759 "reserved" 1758 "reserved" 1757 "reserved" 1756 "reserved" 1755 "reserved" 1754 "reserved" 1753 "reserved" 1752 "reserved" 1751 "reserved" 1750 "reserved" 1749 "reserved" 1748 "reserved" 1747 "reserved" 1746 "reserved" 1745 "reserved" 1744 "reserved" 1743 "reserved" 1742 "reserved" 1741 "reserved" 1740 "reserved" 1739 "reserved" 1738 "reserved" 1737 "reserved" 1736 "reserved" 1735 "reserved" 1734 "reserved" 1733 "reserved" 1732 "reserved" 1731 "reserved" 1730 "reserved" 1729 "reserved" 1728 "reserved" 1727 "reserved" 1726 "reserved" 1725 "reserved" 1724 "reserved" 1723 "reserved" 1722 "reserved" 1721 "reserved" 1720 "reserved" 1719 "reserved" 1718 "reserved" 1717 "reserved" 1716 "reserved" 1715 "reserved" 1714 "reserved" 1713 "reserved" 1712 "reserved" 1711 "reserved" 1710 "reserved" 1709 "reserved" 1708 "reserved" 1707 "reserved" 1706 "reserved" 1705 "reserved" 1704 "reserved" 1703 "reserved" 1702 "reserved" 1701 "reserved" 1700 "reserved" 1699 "reserved" 1698 "reserved" 1697 "reserved" 1696 "reserved" 1695 "reserved" 1694 "reserved" 1693 "reserved" 1692 "reserved" 1691 "reserved" 1690 "reserved" 1689 "reserved" 1688 "reserved" 1687 "reserved" 1686 "reserved" 1685 "reserved" 1684 "reserved" 1683 "reserved" 1682 "reserved" 1681 "reserved" 1680 "reserved" 1679 "reserved" 1678 "reserved" 1677 "reserved" 1676 "reserved" 1675 "reserved" 1674 "reserved" 1673 "reserved" 1672 "reserved" 1671 "reserved" 1670 "reserved" 1669 "reserved" 1668 "reserved" 1667 "reserved" 1666 "reserved" 1665 "reserved" 1664 "reserved" 1663 "reserved" 1662 "reserved" 1661 "reserved" 1660 "reserved" 1659 "reserved" 1658 "reserved" 1657 "reserved" 1656 "reserved" 1655 "reserved" 1654 "reserved" 1653 "reserved" 1652 "reserved" 1651 "reserved" 1650 "reserved" 1649 "reserved" 1648 "reserved" 1647 "reserved" 1646 "reserved" 1645 "reserved" 1644 "reserved" 1643 "reserved" 1642 "reserved" 1641 "reserved" 1640 "reserved" 1639 "reserved" 1638 "reserved" 1637 "reserved" 1636 "reserved" 1635 "reserved" 1634 "reserved" 1633 "reserved" 1632 "reserved" 1631 "reserved" 1630 "reserved" 1629 "reserved" 1628 "reserved" 1627 "reserved" 1626 "reserved" 1625 "reserved" 1624 "reserved" 1623 "reserved" 1622 "reserved" 1621 "reserved" 1620 "reserved" 1619 "reserved" 1618 "reserved" 1617 "reserved" 1616 "reserved" 1615 "reserved" 1614 "reserved" 1613 "reserved" 1612 "reserved" 1611 "reserved" 1610 "reserved" 1609 "reserved" 1608 "reserved" 1607 "reserved" 1606 "reserved" 1605 "reserved" 1604 "reserved" 1603 "reserved" 1602 "reserved" 1601 "reserved" ;
VAL_ 338 Map_TrafficOn 2047 "reserved" 2046 "reserved" 2045 "reserved" 2044 "reserved" 2043 "reserved" 2042 "reserved" 2041 "reserved" 2040 "reserved" 2039 "reserved" 2038 "reserved" 2037 "reserved" 2036 "reserved" 2035 "reserved" 2034 "reserved" 2033 "reserved" 2032 "reserved" 2031 "reserved" 2030 "reserved" 2029 "reserved" 2028 "reserved" 2027 "reserved" 2026 "reserved" 2025 "reserved" 2024 "reserved" 2023 "reserved" 2022 "reserved" 2021 "reserved" 2020 "reserved" 2019 "reserved" 2018 "reserved" 2017 "reserved" 2016 "reserved" 2015 "reserved" 2014 "reserved" 2013 "reserved" 2012 "reserved" 2011 "reserved" 2010 "reserved" 2009 "reserved" 2008 "reserved" 2007 "reserved" 2006 "reserved" 2005 "reserved" 2004 "reserved" 2003 "reserved" 2002 "reserved" 2001 "reserved" 2000 "reserved" 1999 "reserved" 1998 "reserved" 1997 "reserved" 1996 "reserved" 1995 "reserved" 1994 "reserved" 1993 "reserved" 1992 "reserved" 1991 "reserved" 1990 "reserved" 1989 "reserved" 1988 "reserved" 1987 "reserved" 1986 "reserved" 1985 "reserved" 1984 "reserved" 1983 "reserved" 1982 "reserved" 1981 "reserved" 1980 "reserved" 1979 "reserved" 1978 "reserved" 1977 "reserved" 1976 "reserved" 1975 "reserved" 1974 "reserved" 1973 "reserved" 1972 "reserved" 1971 "reserved" 1970 "reserved" 1969 "reserved" 1968 "reserved" 1967 "reserved" 1966 "reserved" 1965 "reserved" 1964 "reserved" 1963 "reserved" 1962 "reserved" 1961 "reserved" 1960 "reserved" 1959 "reserved" 1958 "reserved" 1957 "reserved" 1956 "reserved" 1955 "reserved" 1954 "reserved" 1953 "reserved" 1952 "reserved" 1951 "reserved" 1950 "reserved" 1949 "reserved" 1948 "reserved" 1947 "reserved" 1946 "reserved" 1945 "reserved" 1944 "reserved" 1943 "reserved" 1942 "reserved" 1941 "reserved" 1940 "reserved" 1939 "reserved" 1938 "reserved" 1937 "reserved" 1936 "reserved" 1935 "reserved" 1934 "reserved" 1933 "reserved" 1932 "reserved" 1931 "reserved" 1930 "reserved" 1929 "reserved" 1928 "reserved" 1927 "reserved" 1926 "reserved" 1925 "reserved" 1924 "reserved" 1923 "reserved" 1922 "reserved" 1921 "reserved" 1920 "reserved" 1919 "reserved" 1918 "reserved" 1917 "reserved" 1916 "reserved" 1915 "reserved" 1914 "reserved" 1913 "reserved" 1912 "reserved" 1911 "reserved" 1910 "reserved" 1909 "reserved" 1908 "reserved" 1907 "reserved" 1906 "reserved" 1905 "reserved" 1904 "reserved" 1903 "reserved" 1902 "reserved" 1901 "reserved" 1900 "reserved" 1899 "reserved" 1898 "reserved" 1897 "reserved" 1896 "reserved" 1895 "reserved" 1894 "reserved" 1893 "reserved" 1892 "reserved" 1891 "reserved" 1890 "reserved" 1889 "reserved" 1888 "reserved" 1887 "reserved" 1886 "reserved" 1885 "reserved" 1884 "reserved" 1883 "reserved" 1882 "reserved" 1881 "reserved" 1880 "reserved" 1879 "reserved" 1878 "reserved" 1877 "reserved" 1876 "reserved" 1875 "reserved" 1874 "reserved" 1873 "reserved" 1872 "reserved" 1871 "reserved" 1870 "reserved" 1869 "reserved" 1868 "reserved" 1867 "reserved" 1866 "reserved" 1865 "reserved" 1864 "reserved" 1863 "reserved" 1862 "reserved" 1861 "reserved" 1860 "reserved" 1859 "reserved" 1858 "reserved" 1857 "reserved" 1856 "reserved" 1855 "reserved" 1854 "reserved" 1853 "reserved" 1852 "reserved" 1851 "reserved" 1850 "reserved" 1849 "reserved" 1848 "reserved" 1847 "reserved" 1846 "reserved" 1845 "reserved" 1844 "reserved" 1843 "reserved" 1842 "reserved" 1841 "reserved" 1840 "reserved" 1839 "reserved" 1838 "reserved" 1837 "reserved" 1836 "reserved" 1835 "reserved" 1834 "reserved" 1833 "reserved" 1832 "reserved" 1831 "reserved" 1830 "reserved" 1829 "reserved" 1828 "reserved" 1827 "reserved" 1826 "reserved" 1825 "reserved" 1824 "reserved" 1823 "reserved" 1822 "reserved" 1821 "reserved" 1820 "reserved" 1819 "reserved" 1818 "reserved" 1817 "reserved" 1816 "reserved" 1815 "reserved" 1814 "reserved" 1813 "reserved" 1812 "reserved" 1811 "reserved" 1810 "reserved" 1809 "reserved" 1808 "reserved" 1807 "reserved" 1806 "reserved" 1805 "reserved" 1804 "reserved" 1803 "reserved" 1802 "reserved" 1801 "reserved" 1800 "reserved" 1799 "reserved" 1798 "reserved" 1797 "reserved" 1796 "reserved" 1795 "reserved" 1794 "reserved" 1793 "reserved" 1792 "reserved" 1791 "reserved" 1790 "reserved" 1789 "reserved" 1788 "reserved" 1787 "reserved" 1786 "reserved" 1785 "reserved" 1784 "reserved" 1783 "reserved" 1782 "reserved" 1781 "reserved" 1780 "reserved" 1779 "reserved" 1778 "reserved" 1777 "reserved" 1776 "reserved" 1775 "reserved" 1774 "reserved" 1773 "reserved" 1772 "reserved" 1771 "reserved" 1770 "reserved" 1769 "reserved" 1768 "reserved" 1767 "reserved" 1766 "reserved" 1765 "reserved" 1764 "reserved" 1763 "reserved" 1762 "reserved" 1761 "reserved" 1760 "reserved" 1759 "reserved" 1758 "reserved" 1757 "reserved" 1756 "reserved" 1755 "reserved" 1754 "reserved" 1753 "reserved" 1752 "reserved" 1751 "reserved" 1750 "reserved" 1749 "reserved" 1748 "reserved" 1747 "reserved" 1746 "reserved" 1745 "reserved" 1744 "reserved" 1743 "reserved" 1742 "reserved" 1741 "reserved" 1740 "reserved" 1739 "reserved" 1738 "reserved" 1737 "reserved" 1736 "reserved" 1735 "reserved" 1734 "reserved" 1733 "reserved" 1732 "reserved" 1731 "reserved" 1730 "reserved" 1729 "reserved" 1728 "reserved" 1727 "reserved" 1726 "reserved" 1725 "reserved" 1724 "reserved" 1723 "reserved" 1722 "reserved" 1721 "reserved" 1720 "reserved" 1719 "reserved" 1718 "reserved" 1717 "reserved" 1716 "reserved" 1715 "reserved" 1714 "reserved" 1713 "reserved" 1712 "reserved" 1711 "reserved" 1710 "reserved" 1709 "reserved" 1708 "reserved" 1707 "reserved" 1706 "reserved" 1705 "reserved" 1704 "reserved" 1703 "reserved" 1702 "reserved" 1701 "reserved" 1700 "reserved" 1699 "reserved" 1698 "reserved" 1697 "reserved" 1696 "reserved" 1695 "reserved" 1694 "reserved" 1693 "reserved" 1692 "reserved" 1691 "reserved" 1690 "reserved" 1689 "reserved" 1688 "reserved" 1687 "reserved" 1686 "reserved" 1685 "reserved" 1684 "reserved" 1683 "reserved" 1682 "reserved" 1681 "reserved" 1680 "reserved" 1679 "reserved" 1678 "reserved" 1677 "reserved" 1676 "reserved" 1675 "reserved" 1674 "reserved" 1673 "reserved" 1672 "reserved" 1671 "reserved" 1670 "reserved" 1669 "reserved" 1668 "reserved" 1667 "reserved" 1666 "reserved" 1665 "reserved" 1664 "reserved" 1663 "reserved" 1662 "reserved" 1661 "reserved" 1660 "reserved" 1659 "reserved" 1658 "reserved" 1657 "reserved" 1656 "reserved" 1655 "reserved" 1654 "reserved" 1653 "reserved" 1652 "reserved" 1651 "reserved" 1650 "reserved" 1649 "reserved" 1648 "reserved" 1647 "reserved" 1646 "reserved" 1645 "reserved" 1644 "reserved" 1643 "reserved" 1642 "reserved" 1641 "reserved" 1640 "reserved" 1639 "reserved" 1638 "reserved" 1637 "reserved" 1636 "reserved" 1635 "reserved" 1634 "reserved" 1633 "reserved" 1632 "reserved" 1631 "reserved" 1630 "reserved" 1629 "reserved" 1628 "reserved" 1627 "reserved" 1626 "reserved" 1625 "reserved" 1624 "reserved" 1623 "reserved" 1622 "reserved" 1621 "reserved" 1620 "reserved" 1619 "reserved" 1618 "reserved" 1617 "reserved" 1616 "reserved" 1615 "reserved" 1614 "reserved" 1613 "reserved" 1612 "reserved" 1611 "reserved" 1610 "reserved" 1609 "reserved" 1608 "reserved" 1607 "reserved" 1606 "reserved" 1605 "reserved" 1604 "reserved" 1603 "reserved" 1602 "reserved" 1601 "reserved" ;
VAL_ 338 Map_POI_Select 1023 "reserved" 1022 "reserved" 1021 "reserved" 1020 "reserved" 1019 "reserved" 1018 "reserved" 1017 "reserved" 1016 "reserved" 1015 "reserved" 1014 "reserved" 1013 "reserved" 1012 "reserved" 1011 "reserved" 1010 "reserved" 1009 "reserved" 1008 "reserved" 1007 "reserved" 1006 "reserved" 1005 "reserved" 1004 "reserved" 1003 "reserved" 1002 "reserved" 1001 "reserved" ;
VAL_ 338 SpeedLimit_Display 3 "Others" 2 "Preceding" 1 "Oncoming" 0 "Idle" ;
VAL_ 338 LaneGuidance_On 63 " Not Available" 62 " Initating" 0 " No Object" ;
VAL_ 338 LaneGuidance_Brightness 12 " β��˫��" 11 " β�Ƶ���" 10 " ǰ��˫��" 9 " ǰ�Ƶ���" 8 " Unknown" 7 " Billboard" 6 " Mixed" 5 " Pedestrain" 4 " Bike" 3 " Bus" 2 " Truck" 1 " Car" 0 " NoVehicle" ;
VAL_ 338 HeadUpDisplay_Brightness 2047 "reserved" 2046 "reserved" 2045 "reserved" 2044 "reserved" 2043 "reserved" 2042 "reserved" 2041 "reserved" 2040 "reserved" 2039 "reserved" 2038 "reserved" 2037 "reserved" 2036 "reserved" 2035 "reserved" 2034 "reserved" 2033 "reserved" 2032 "reserved" 2031 "reserved" 2030 "reserved" 2029 "reserved" 2028 "reserved" 2027 "reserved" 2026 "reserved" 2025 "reserved" 2024 "reserved" 2023 "reserved" 2022 "reserved" 2021 "reserved" 2020 "reserved" 2019 "reserved" 2018 "reserved" 2017 "reserved" 2016 "reserved" 2015 "reserved" 2014 "reserved" 2013 "reserved" 2012 "reserved" 2011 "reserved" 2010 "reserved" 2009 "reserved" 2008 "reserved" 2007 "reserved" 2006 "reserved" 2005 "reserved" 2004 "reserved" 2003 "reserved" 2002 "reserved" 2001 "reserved" 2000 "reserved" 1999 "reserved" 1998 "reserved" 1997 "reserved" 1996 "reserved" 1995 "reserved" 1994 "reserved" 1993 "reserved" 1992 "reserved" 1991 "reserved" 1990 "reserved" 1989 "reserved" 1988 "reserved" 1987 "reserved" 1986 "reserved" 1985 "reserved" 1984 "reserved" 1983 "reserved" 1982 "reserved" 1981 "reserved" 1980 "reserved" 1979 "reserved" 1978 "reserved" 1977 "reserved" 1976 "reserved" 1975 "reserved" 1974 "reserved" 1973 "reserved" 1972 "reserved" 1971 "reserved" 1970 "reserved" 1969 "reserved" 1968 "reserved" 1967 "reserved" 1966 "reserved" 1965 "reserved" 1964 "reserved" 1963 "reserved" 1962 "reserved" 1961 "reserved" 1960 "reserved" 1959 "reserved" 1958 "reserved" 1957 "reserved" 1956 "reserved" 1955 "reserved" 1954 "reserved" 1953 "reserved" 1952 "reserved" 1951 "reserved" 1950 "reserved" 1949 "reserved" 1948 "reserved" 1947 "reserved" 1946 "reserved" 1945 "reserved" 1944 "reserved" 1943 "reserved" 1942 "reserved" 1941 "reserved" 1940 "reserved" 1939 "reserved" 1938 "reserved" 1937 "reserved" 1936 "reserved" 1935 "reserved" 1934 "reserved" 1933 "reserved" 1932 "reserved" 1931 "reserved" 1930 "reserved" 1929 "reserved" 1928 "reserved" 1927 "reserved" 1926 "reserved" 1925 "reserved" 1924 "reserved" 1923 "reserved" 1922 "reserved" 1921 "reserved" 1920 "reserved" 1919 "reserved" 1918 "reserved" 1917 "reserved" 1916 "reserved" 1915 "reserved" 1914 "reserved" 1913 "reserved" 1912 "reserved" 1911 "reserved" 1910 "reserved" 1909 "reserved" 1908 "reserved" 1907 "reserved" 1906 "reserved" 1905 "reserved" 1904 "reserved" 1903 "reserved" 1902 "reserved" 1901 "reserved" 1900 "reserved" 1899 "reserved" 1898 "reserved" 1897 "reserved" 1896 "reserved" 1895 "reserved" 1894 "reserved" 1893 "reserved" 1892 "reserved" 1891 "reserved" 1890 "reserved" 1889 "reserved" 1888 "reserved" 1887 "reserved" 1886 "reserved" 1885 "reserved" 1884 "reserved" 1883 "reserved" 1882 "reserved" 1881 "reserved" 1880 "reserved" 1879 "reserved" 1878 "reserved" 1877 "reserved" 1876 "reserved" 1875 "reserved" 1874 "reserved" 1873 "reserved" 1872 "reserved" 1871 "reserved" 1870 "reserved" 1869 "reserved" 1868 "reserved" 1867 "reserved" 1866 "reserved" 1865 "reserved" 1864 "reserved" 1863 "reserved" 1862 "reserved" 1861 "reserved" 1860 "reserved" 1859 "reserved" 1858 "reserved" 1857 "reserved" 1856 "reserved" 1855 "reserved" 1854 "reserved" 1853 "reserved" 1852 "reserved" 1851 "reserved" 1850 "reserved" 1849 "reserved" 1848 "reserved" 1847 "reserved" 1846 "reserved" 1845 "reserved" 1844 "reserved" 1843 "reserved" 1842 "reserved" 1841 "reserved" 1840 "reserved" 1839 "reserved" 1838 "reserved" 1837 "reserved" 1836 "reserved" 1835 "reserved" 1834 "reserved" 1833 "reserved" 1832 "reserved" 1831 "reserved" 1830 "reserved" 1829 "reserved" 1828 "reserved" 1827 "reserved" 1826 "reserved" 1825 "reserved" 1824 "reserved" 1823 "reserved" 1822 "reserved" 1821 "reserved" 1820 "reserved" 1819 "reserved" 1818 "reserved" 1817 "reserved" 1816 "reserved" 1815 "reserved" 1814 "reserved" 1813 "reserved" 1812 "reserved" 1811 "reserved" 1810 "reserved" 1809 "reserved" 1808 "reserved" 1807 "reserved" 1806 "reserved" 1805 "reserved" 1804 "reserved" 1803 "reserved" 1802 "reserved" 1801 "reserved" 1800 "reserved" 1799 "reserved" 1798 "reserved" 1797 "reserved" 1796 "reserved" 1795 "reserved" 1794 "reserved" 1793 "reserved" 1792 "reserved" 1791 "reserved" 1790 "reserved" 1789 "reserved" 1788 "reserved" 1787 "reserved" 1786 "reserved" 1785 "reserved" 1784 "reserved" 1783 "reserved" 1782 "reserved" 1781 "reserved" 1780 "reserved" 1779 "reserved" 1778 "reserved" 1777 "reserved" 1776 "reserved" 1775 "reserved" 1774 "reserved" 1773 "reserved" 1772 "reserved" 1771 "reserved" 1770 "reserved" 1769 "reserved" 1768 "reserved" 1767 "reserved" 1766 "reserved" 1765 "reserved" 1764 "reserved" 1763 "reserved" 1762 "reserved" 1761 "reserved" 1760 "reserved" 1759 "reserved" 1758 "reserved" 1757 "reserved" 1756 "reserved" 1755 "reserved" 1754 "reserved" 1753 "reserved" 1752 "reserved" 1751 "reserved" 1750 "reserved" 1749 "reserved" 1748 "reserved" 1747 "reserved" 1746 "reserved" 1745 "reserved" 1744 "reserved" 1743 "reserved" 1742 "reserved" 1741 "reserved" 1740 "reserved" 1739 "reserved" 1738 "reserved" 1737 "reserved" 1736 "reserved" 1735 "reserved" 1734 "reserved" 1733 "reserved" 1732 "reserved" 1731 "reserved" 1730 "reserved" 1729 "reserved" 1728 "reserved" 1727 "reserved" 1726 "reserved" 1725 "reserved" 1724 "reserved" 1723 "reserved" 1722 "reserved" 1721 "reserved" 1720 "reserved" 1719 "reserved" 1718 "reserved" 1717 "reserved" 1716 "reserved" 1715 "reserved" 1714 "reserved" 1713 "reserved" 1712 "reserved" 1711 "reserved" 1710 "reserved" 1709 "reserved" 1708 "reserved" 1707 "reserved" 1706 "reserved" 1705 "reserved" 1704 "reserved" 1703 "reserved" 1702 "reserved" 1701 "reserved" 1700 "reserved" 1699 "reserved" 1698 "reserved" 1697 "reserved" 1696 "reserved" 1695 "reserved" 1694 "reserved" 1693 "reserved" 1692 "reserved" 1691 "reserved" 1690 "reserved" 1689 "reserved" 1688 "reserved" 1687 "reserved" 1686 "reserved" 1685 "reserved" 1684 "reserved" 1683 "reserved" 1682 "reserved" 1681 "reserved" 1680 "reserved" 1679 "reserved" 1678 "reserved" 1677 "reserved" 1676 "reserved" 1675 "reserved" 1674 "reserved" 1673 "reserved" 1672 "reserved" 1671 "reserved" 1670 "reserved" 1669 "reserved" 1668 "reserved" 1667 "reserved" 1666 "reserved" 1665 "reserved" 1664 "reserved" 1663 "reserved" 1662 "reserved" 1661 "reserved" 1660 "reserved" 1659 "reserved" 1658 "reserved" 1657 "reserved" 1656 "reserved" 1655 "reserved" 1654 "reserved" 1653 "reserved" 1652 "reserved" 1651 "reserved" 1650 "reserved" 1649 "reserved" 1648 "reserved" 1647 "reserved" 1646 "reserved" 1645 "reserved" 1644 "reserved" 1643 "reserved" 1642 "reserved" 1641 "reserved" 1640 "reserved" 1639 "reserved" 1638 "reserved" 1637 "reserved" 1636 "reserved" 1635 "reserved" 1634 "reserved" 1633 "reserved" 1632 "reserved" 1631 "reserved" 1630 "reserved" 1629 "reserved" 1628 "reserved" 1627 "reserved" 1626 "reserved" 1625 "reserved" 1624 "reserved" 1623 "reserved" 1622 "reserved" 1621 "reserved" 1620 "reserved" 1619 "reserved" 1618 "reserved" 1617 "reserved" 1616 "reserved" 1615 "reserved" 1614 "reserved" 1613 "reserved" 1612 "reserved" 1611 "reserved" 1610 "reserved" 1609 "reserved" 1608 "reserved" 1607 "reserved" 1606 "reserved" 1605 "reserved" 1604 "reserved" 1603 "reserved" 1602 "reserved" 1601 "reserved" ;
VAL_ 338 HeadUpDisplay_Pos 2047 "reserved" 2046 "reserved" 2045 "reserved" 2044 "reserved" 2043 "reserved" 2042 "reserved" 2041 "reserved" 2040 "reserved" 2039 "reserved" 2038 "reserved" 2037 "reserved" 2036 "reserved" 2035 "reserved" 2034 "reserved" 2033 "reserved" 2032 "reserved" 2031 "reserved" 2030 "reserved" 2029 "reserved" 2028 "reserved" 2027 "reserved" 2026 "reserved" 2025 "reserved" 2024 "reserved" 2023 "reserved" 2022 "reserved" 2021 "reserved" 2020 "reserved" 2019 "reserved" 2018 "reserved" 2017 "reserved" 2016 "reserved" 2015 "reserved" 2014 "reserved" 2013 "reserved" 2012 "reserved" 2011 "reserved" 2010 "reserved" 2009 "reserved" 2008 "reserved" 2007 "reserved" 2006 "reserved" 2005 "reserved" 2004 "reserved" 2003 "reserved" 2002 "reserved" 2001 "reserved" 2000 "reserved" 1999 "reserved" 1998 "reserved" 1997 "reserved" 1996 "reserved" 1995 "reserved" 1994 "reserved" 1993 "reserved" 1992 "reserved" 1991 "reserved" 1990 "reserved" 1989 "reserved" 1988 "reserved" 1987 "reserved" 1986 "reserved" 1985 "reserved" 1984 "reserved" 1983 "reserved" 1982 "reserved" 1981 "reserved" 1980 "reserved" 1979 "reserved" 1978 "reserved" 1977 "reserved" 1976 "reserved" 1975 "reserved" 1974 "reserved" 1973 "reserved" 1972 "reserved" 1971 "reserved" 1970 "reserved" 1969 "reserved" 1968 "reserved" 1967 "reserved" 1966 "reserved" 1965 "reserved" 1964 "reserved" 1963 "reserved" 1962 "reserved" 1961 "reserved" 1960 "reserved" 1959 "reserved" 1958 "reserved" 1957 "reserved" 1956 "reserved" 1955 "reserved" 1954 "reserved" 1953 "reserved" 1952 "reserved" 1951 "reserved" 1950 "reserved" 1949 "reserved" 1948 "reserved" 1947 "reserved" 1946 "reserved" 1945 "reserved" 1944 "reserved" 1943 "reserved" 1942 "reserved" 1941 "reserved" 1940 "reserved" 1939 "reserved" 1938 "reserved" 1937 "reserved" 1936 "reserved" 1935 "reserved" 1934 "reserved" 1933 "reserved" 1932 "reserved" 1931 "reserved" 1930 "reserved" 1929 "reserved" 1928 "reserved" 1927 "reserved" 1926 "reserved" 1925 "reserved" 1924 "reserved" 1923 "reserved" 1922 "reserved" 1921 "reserved" 1920 "reserved" 1919 "reserved" 1918 "reserved" 1917 "reserved" 1916 "reserved" 1915 "reserved" 1914 "reserved" 1913 "reserved" 1912 "reserved" 1911 "reserved" 1910 "reserved" 1909 "reserved" 1908 "reserved" 1907 "reserved" 1906 "reserved" 1905 "reserved" 1904 "reserved" 1903 "reserved" 1902 "reserved" 1901 "reserved" 1900 "reserved" 1899 "reserved" 1898 "reserved" 1897 "reserved" 1896 "reserved" 1895 "reserved" 1894 "reserved" 1893 "reserved" 1892 "reserved" 1891 "reserved" 1890 "reserved" 1889 "reserved" 1888 "reserved" 1887 "reserved" 1886 "reserved" 1885 "reserved" 1884 "reserved" 1883 "reserved" 1882 "reserved" 1881 "reserved" 1880 "reserved" 1879 "reserved" 1878 "reserved" 1877 "reserved" 1876 "reserved" 1875 "reserved" 1874 "reserved" 1873 "reserved" 1872 "reserved" 1871 "reserved" 1870 "reserved" 1869 "reserved" 1868 "reserved" 1867 "reserved" 1866 "reserved" 1865 "reserved" 1864 "reserved" 1863 "reserved" 1862 "reserved" 1861 "reserved" 1860 "reserved" 1859 "reserved" 1858 "reserved" 1857 "reserved" 1856 "reserved" 1855 "reserved" 1854 "reserved" 1853 "reserved" 1852 "reserved" 1851 "reserved" 1850 "reserved" 1849 "reserved" 1848 "reserved" 1847 "reserved" 1846 "reserved" 1845 "reserved" 1844 "reserved" 1843 "reserved" 1842 "reserved" 1841 "reserved" 1840 "reserved" 1839 "reserved" 1838 "reserved" 1837 "reserved" 1836 "reserved" 1835 "reserved" 1834 "reserved" 1833 "reserved" 1832 "reserved" 1831 "reserved" 1830 "reserved" 1829 "reserved" 1828 "reserved" 1827 "reserved" 1826 "reserved" 1825 "reserved" 1824 "reserved" 1823 "reserved" 1822 "reserved" 1821 "reserved" 1820 "reserved" 1819 "reserved" 1818 "reserved" 1817 "reserved" 1816 "reserved" 1815 "reserved" 1814 "reserved" 1813 "reserved" 1812 "reserved" 1811 "reserved" 1810 "reserved" 1809 "reserved" 1808 "reserved" 1807 "reserved" 1806 "reserved" 1805 "reserved" 1804 "reserved" 1803 "reserved" 1802 "reserved" 1801 "reserved" 1800 "reserved" 1799 "reserved" 1798 "reserved" 1797 "reserved" 1796 "reserved" 1795 "reserved" 1794 "reserved" 1793 "reserved" 1792 "reserved" 1791 "reserved" 1790 "reserved" 1789 "reserved" 1788 "reserved" 1787 "reserved" 1786 "reserved" 1785 "reserved" 1784 "reserved" 1783 "reserved" 1782 "reserved" 1781 "reserved" 1780 "reserved" 1779 "reserved" 1778 "reserved" 1777 "reserved" 1776 "reserved" 1775 "reserved" 1774 "reserved" 1773 "reserved" 1772 "reserved" 1771 "reserved" 1770 "reserved" 1769 "reserved" 1768 "reserved" 1767 "reserved" 1766 "reserved" 1765 "reserved" 1764 "reserved" 1763 "reserved" 1762 "reserved" 1761 "reserved" 1760 "reserved" 1759 "reserved" 1758 "reserved" 1757 "reserved" 1756 "reserved" 1755 "reserved" 1754 "reserved" 1753 "reserved" 1752 "reserved" 1751 "reserved" 1750 "reserved" 1749 "reserved" 1748 "reserved" 1747 "reserved" 1746 "reserved" 1745 "reserved" 1744 "reserved" 1743 "reserved" 1742 "reserved" 1741 "reserved" 1740 "reserved" 1739 "reserved" 1738 "reserved" 1737 "reserved" 1736 "reserved" 1735 "reserved" 1734 "reserved" 1733 "reserved" 1732 "reserved" 1731 "reserved" 1730 "reserved" 1729 "reserved" 1728 "reserved" 1727 "reserved" 1726 "reserved" 1725 "reserved" 1724 "reserved" 1723 "reserved" 1722 "reserved" 1721 "reserved" 1720 "reserved" 1719 "reserved" 1718 "reserved" 1717 "reserved" 1716 "reserved" 1715 "reserved" 1714 "reserved" 1713 "reserved" 1712 "reserved" 1711 "reserved" 1710 "reserved" 1709 "reserved" 1708 "reserved" 1707 "reserved" 1706 "reserved" 1705 "reserved" 1704 "reserved" 1703 "reserved" 1702 "reserved" 1701 "reserved" 1700 "reserved" 1699 "reserved" 1698 "reserved" 1697 "reserved" 1696 "reserved" 1695 "reserved" 1694 "reserved" 1693 "reserved" 1692 "reserved" 1691 "reserved" 1690 "reserved" 1689 "reserved" 1688 "reserved" 1687 "reserved" 1686 "reserved" 1685 "reserved" 1684 "reserved" 1683 "reserved" 1682 "reserved" 1681 "reserved" 1680 "reserved" 1679 "reserved" 1678 "reserved" 1677 "reserved" 1676 "reserved" 1675 "reserved" 1674 "reserved" 1673 "reserved" 1672 "reserved" 1671 "reserved" 1670 "reserved" 1669 "reserved" 1668 "reserved" 1667 "reserved" 1666 "reserved" 1665 "reserved" 1664 "reserved" 1663 "reserved" 1662 "reserved" 1661 "reserved" 1660 "reserved" 1659 "reserved" 1658 "reserved" 1657 "reserved" 1656 "reserved" 1655 "reserved" 1654 "reserved" 1653 "reserved" 1652 "reserved" 1651 "reserved" 1650 "reserved" 1649 "reserved" 1648 "reserved" 1647 "reserved" 1646 "reserved" 1645 "reserved" 1644 "reserved" 1643 "reserved" 1642 "reserved" 1641 "reserved" 1640 "reserved" 1639 "reserved" 1638 "reserved" 1637 "reserved" 1636 "reserved" 1635 "reserved" 1634 "reserved" 1633 "reserved" 1632 "reserved" 1631 "reserved" 1630 "reserved" 1629 "reserved" 1628 "reserved" 1627 "reserved" 1626 "reserved" 1625 "reserved" 1624 "reserved" 1623 "reserved" 1622 "reserved" 1621 "reserved" 1620 "reserved" 1619 "reserved" 1618 "reserved" 1617 "reserved" 1616 "reserved" 1615 "reserved" 1614 "reserved" 1613 "reserved" 1612 "reserved" 1611 "reserved" 1610 "reserved" 1609 "reserved" 1608 "reserved" 1607 "reserved" 1606 "reserved" 1605 "reserved" 1604 "reserved" 1603 "reserved" 1602 "reserved" 1601 "reserved" ;
VAL_ 338 HeadUpDisplay_Rotation 1023 "reserved" 1022 "reserved" 1021 "reserved" 1020 "reserved" 1019 "reserved" 1018 "reserved" 1017 "reserved" 1016 "reserved" 1015 "reserved" 1014 "reserved" 1013 "reserved" 1012 "reserved" 1011 "reserved" 1010 "reserved" 1009 "reserved" 1008 "reserved" 1007 "reserved" 1006 "reserved" 1005 "reserved" 1004 "reserved" 1003 "reserved" 1002 "reserved" 1001 "reserved" ;
VAL_ 338 ClusterNav_On 3 "Others" 2 "Preceding" 1 "Oncoming" 0 "Idle" ;
VAL_ 339 Media4_CRC 63 " Not Available" 62 " Initating" 0 " No Object" ;
VAL_ 339 Media4_RollCnt 12 " β��˫��" 11 " β�Ƶ���" 10 " ǰ��˫��" 9 " ǰ�Ƶ���" 8 " Unknown" 7 " Billboard" 6 " Mixed" 5 " Pedestrain" 4 " Bike" 3 " Bus" 2 " Truck" 1 " Car" 0 " NoVehicle" ;
VAL_ 339 ADAS_LDWS_Sensitivity 2047 "reserved" 2046 "reserved" 2045 "reserved" 2044 "reserved" 2043 "reserved" 2042 "reserved" 2041 "reserved" 2040 "reserved" 2039 "reserved" 2038 "reserved" 2037 "reserved" 2036 "reserved" 2035 "reserved" 2034 "reserved" 2033 "reserved" 2032 "reserved" 2031 "reserved" 2030 "reserved" 2029 "reserved" 2028 "reserved" 2027 "reserved" 2026 "reserved" 2025 "reserved" 2024 "reserved" 2023 "reserved" 2022 "reserved" 2021 "reserved" 2020 "reserved" 2019 "reserved" 2018 "reserved" 2017 "reserved" 2016 "reserved" 2015 "reserved" 2014 "reserved" 2013 "reserved" 2012 "reserved" 2011 "reserved" 2010 "reserved" 2009 "reserved" 2008 "reserved" 2007 "reserved" 2006 "reserved" 2005 "reserved" 2004 "reserved" 2003 "reserved" 2002 "reserved" 2001 "reserved" 2000 "reserved" 1999 "reserved" 1998 "reserved" 1997 "reserved" 1996 "reserved" 1995 "reserved" 1994 "reserved" 1993 "reserved" 1992 "reserved" 1991 "reserved" 1990 "reserved" 1989 "reserved" 1988 "reserved" 1987 "reserved" 1986 "reserved" 1985 "reserved" 1984 "reserved" 1983 "reserved" 1982 "reserved" 1981 "reserved" 1980 "reserved" 1979 "reserved" 1978 "reserved" 1977 "reserved" 1976 "reserved" 1975 "reserved" 1974 "reserved" 1973 "reserved" 1972 "reserved" 1971 "reserved" 1970 "reserved" 1969 "reserved" 1968 "reserved" 1967 "reserved" 1966 "reserved" 1965 "reserved" 1964 "reserved" 1963 "reserved" 1962 "reserved" 1961 "reserved" 1960 "reserved" 1959 "reserved" 1958 "reserved" 1957 "reserved" 1956 "reserved" 1955 "reserved" 1954 "reserved" 1953 "reserved" 1952 "reserved" 1951 "reserved" 1950 "reserved" 1949 "reserved" 1948 "reserved" 1947 "reserved" 1946 "reserved" 1945 "reserved" 1944 "reserved" 1943 "reserved" 1942 "reserved" 1941 "reserved" 1940 "reserved" 1939 "reserved" 1938 "reserved" 1937 "reserved" 1936 "reserved" 1935 "reserved" 1934 "reserved" 1933 "reserved" 1932 "reserved" 1931 "reserved" 1930 "reserved" 1929 "reserved" 1928 "reserved" 1927 "reserved" 1926 "reserved" 1925 "reserved" 1924 "reserved" 1923 "reserved" 1922 "reserved" 1921 "reserved" 1920 "reserved" 1919 "reserved" 1918 "reserved" 1917 "reserved" 1916 "reserved" 1915 "reserved" 1914 "reserved" 1913 "reserved" 1912 "reserved" 1911 "reserved" 1910 "reserved" 1909 "reserved" 1908 "reserved" 1907 "reserved" 1906 "reserved" 1905 "reserved" 1904 "reserved" 1903 "reserved" 1902 "reserved" 1901 "reserved" 1900 "reserved" 1899 "reserved" 1898 "reserved" 1897 "reserved" 1896 "reserved" 1895 "reserved" 1894 "reserved" 1893 "reserved" 1892 "reserved" 1891 "reserved" 1890 "reserved" 1889 "reserved" 1888 "reserved" 1887 "reserved" 1886 "reserved" 1885 "reserved" 1884 "reserved" 1883 "reserved" 1882 "reserved" 1881 "reserved" 1880 "reserved" 1879 "reserved" 1878 "reserved" 1877 "reserved" 1876 "reserved" 1875 "reserved" 1874 "reserved" 1873 "reserved" 1872 "reserved" 1871 "reserved" 1870 "reserved" 1869 "reserved" 1868 "reserved" 1867 "reserved" 1866 "reserved" 1865 "reserved" 1864 "reserved" 1863 "reserved" 1862 "reserved" 1861 "reserved" 1860 "reserved" 1859 "reserved" 1858 "reserved" 1857 "reserved" 1856 "reserved" 1855 "reserved" 1854 "reserved" 1853 "reserved" 1852 "reserved" 1851 "reserved" 1850 "reserved" 1849 "reserved" 1848 "reserved" 1847 "reserved" 1846 "reserved" 1845 "reserved" 1844 "reserved" 1843 "reserved" 1842 "reserved" 1841 "reserved" 1840 "reserved" 1839 "reserved" 1838 "reserved" 1837 "reserved" 1836 "reserved" 1835 "reserved" 1834 "reserved" 1833 "reserved" 1832 "reserved" 1831 "reserved" 1830 "reserved" 1829 "reserved" 1828 "reserved" 1827 "reserved" 1826 "reserved" 1825 "reserved" 1824 "reserved" 1823 "reserved" 1822 "reserved" 1821 "reserved" 1820 "reserved" 1819 "reserved" 1818 "reserved" 1817 "reserved" 1816 "reserved" 1815 "reserved" 1814 "reserved" 1813 "reserved" 1812 "reserved" 1811 "reserved" 1810 "reserved" 1809 "reserved" 1808 "reserved" 1807 "reserved" 1806 "reserved" 1805 "reserved" 1804 "reserved" 1803 "reserved" 1802 "reserved" 1801 "reserved" 1800 "reserved" 1799 "reserved" 1798 "reserved" 1797 "reserved" 1796 "reserved" 1795 "reserved" 1794 "reserved" 1793 "reserved" 1792 "reserved" 1791 "reserved" 1790 "reserved" 1789 "reserved" 1788 "reserved" 1787 "reserved" 1786 "reserved" 1785 "reserved" 1784 "reserved" 1783 "reserved" 1782 "reserved" 1781 "reserved" 1780 "reserved" 1779 "reserved" 1778 "reserved" 1777 "reserved" 1776 "reserved" 1775 "reserved" 1774 "reserved" 1773 "reserved" 1772 "reserved" 1771 "reserved" 1770 "reserved" 1769 "reserved" 1768 "reserved" 1767 "reserved" 1766 "reserved" 1765 "reserved" 1764 "reserved" 1763 "reserved" 1762 "reserved" 1761 "reserved" 1760 "reserved" 1759 "reserved" 1758 "reserved" 1757 "reserved" 1756 "reserved" 1755 "reserved" 1754 "reserved" 1753 "reserved" 1752 "reserved" 1751 "reserved" 1750 "reserved" 1749 "reserved" 1748 "reserved" 1747 "reserved" 1746 "reserved" 1745 "reserved" 1744 "reserved" 1743 "reserved" 1742 "reserved" 1741 "reserved" 1740 "reserved" 1739 "reserved" 1738 "reserved" 1737 "reserved" 1736 "reserved" 1735 "reserved" 1734 "reserved" 1733 "reserved" 1732 "reserved" 1731 "reserved" 1730 "reserved" 1729 "reserved" 1728 "reserved" 1727 "reserved" 1726 "reserved" 1725 "reserved" 1724 "reserved" 1723 "reserved" 1722 "reserved" 1721 "reserved" 1720 "reserved" 1719 "reserved" 1718 "reserved" 1717 "reserved" 1716 "reserved" 1715 "reserved" 1714 "reserved" 1713 "reserved" 1712 "reserved" 1711 "reserved" 1710 "reserved" 1709 "reserved" 1708 "reserved" 1707 "reserved" 1706 "reserved" 1705 "reserved" 1704 "reserved" 1703 "reserved" 1702 "reserved" 1701 "reserved" 1700 "reserved" 1699 "reserved" 1698 "reserved" 1697 "reserved" 1696 "reserved" 1695 "reserved" 1694 "reserved" 1693 "reserved" 1692 "reserved" 1691 "reserved" 1690 "reserved" 1689 "reserved" 1688 "reserved" 1687 "reserved" 1686 "reserved" 1685 "reserved" 1684 "reserved" 1683 "reserved" 1682 "reserved" 1681 "reserved" 1680 "reserved" 1679 "reserved" 1678 "reserved" 1677 "reserved" 1676 "reserved" 1675 "reserved" 1674 "reserved" 1673 "reserved" 1672 "reserved" 1671 "reserved" 1670 "reserved" 1669 "reserved" 1668 "reserved" 1667 "reserved" 1666 "reserved" 1665 "reserved" 1664 "reserved" 1663 "reserved" 1662 "reserved" 1661 "reserved" 1660 "reserved" 1659 "reserved" 1658 "reserved" 1657 "reserved" 1656 "reserved" 1655 "reserved" 1654 "reserved" 1653 "reserved" 1652 "reserved" 1651 "reserved" 1650 "reserved" 1649 "reserved" 1648 "reserved" 1647 "reserved" 1646 "reserved" 1645 "reserved" 1644 "reserved" 1643 "reserved" 1642 "reserved" 1641 "reserved" 1640 "reserved" 1639 "reserved" 1638 "reserved" 1637 "reserved" 1636 "reserved" 1635 "reserved" 1634 "reserved" 1633 "reserved" 1632 "reserved" 1631 "reserved" 1630 "reserved" 1629 "reserved" 1628 "reserved" 1627 "reserved" 1626 "reserved" 1625 "reserved" 1624 "reserved" 1623 "reserved" 1622 "reserved" 1621 "reserved" 1620 "reserved" 1619 "reserved" 1618 "reserved" 1617 "reserved" 1616 "reserved" 1615 "reserved" 1614 "reserved" 1613 "reserved" 1612 "reserved" 1611 "reserved" 1610 "reserved" 1609 "reserved" 1608 "reserved" 1607 "reserved" 1606 "reserved" 1605 "reserved" 1604 "reserved" 1603 "reserved" 1602 "reserved" 1601 "reserved" ;
VAL_ 339 ADAS_FCW_On 2047 "reserved" 2046 "reserved" 2045 "reserved" 2044 "reserved" 2043 "reserved" 2042 "reserved" 2041 "reserved" 2040 "reserved" 2039 "reserved" 2038 "reserved" 2037 "reserved" 2036 "reserved" 2035 "reserved" 2034 "reserved" 2033 "reserved" 2032 "reserved" 2031 "reserved" 2030 "reserved" 2029 "reserved" 2028 "reserved" 2027 "reserved" 2026 "reserved" 2025 "reserved" 2024 "reserved" 2023 "reserved" 2022 "reserved" 2021 "reserved" 2020 "reserved" 2019 "reserved" 2018 "reserved" 2017 "reserved" 2016 "reserved" 2015 "reserved" 2014 "reserved" 2013 "reserved" 2012 "reserved" 2011 "reserved" 2010 "reserved" 2009 "reserved" 2008 "reserved" 2007 "reserved" 2006 "reserved" 2005 "reserved" 2004 "reserved" 2003 "reserved" 2002 "reserved" 2001 "reserved" 2000 "reserved" 1999 "reserved" 1998 "reserved" 1997 "reserved" 1996 "reserved" 1995 "reserved" 1994 "reserved" 1993 "reserved" 1992 "reserved" 1991 "reserved" 1990 "reserved" 1989 "reserved" 1988 "reserved" 1987 "reserved" 1986 "reserved" 1985 "reserved" 1984 "reserved" 1983 "reserved" 1982 "reserved" 1981 "reserved" 1980 "reserved" 1979 "reserved" 1978 "reserved" 1977 "reserved" 1976 "reserved" 1975 "reserved" 1974 "reserved" 1973 "reserved" 1972 "reserved" 1971 "reserved" 1970 "reserved" 1969 "reserved" 1968 "reserved" 1967 "reserved" 1966 "reserved" 1965 "reserved" 1964 "reserved" 1963 "reserved" 1962 "reserved" 1961 "reserved" 1960 "reserved" 1959 "reserved" 1958 "reserved" 1957 "reserved" 1956 "reserved" 1955 "reserved" 1954 "reserved" 1953 "reserved" 1952 "reserved" 1951 "reserved" 1950 "reserved" 1949 "reserved" 1948 "reserved" 1947 "reserved" 1946 "reserved" 1945 "reserved" 1944 "reserved" 1943 "reserved" 1942 "reserved" 1941 "reserved" 1940 "reserved" 1939 "reserved" 1938 "reserved" 1937 "reserved" 1936 "reserved" 1935 "reserved" 1934 "reserved" 1933 "reserved" 1932 "reserved" 1931 "reserved" 1930 "reserved" 1929 "reserved" 1928 "reserved" 1927 "reserved" 1926 "reserved" 1925 "reserved" 1924 "reserved" 1923 "reserved" 1922 "reserved" 1921 "reserved" 1920 "reserved" 1919 "reserved" 1918 "reserved" 1917 "reserved" 1916 "reserved" 1915 "reserved" 1914 "reserved" 1913 "reserved" 1912 "reserved" 1911 "reserved" 1910 "reserved" 1909 "reserved" 1908 "reserved" 1907 "reserved" 1906 "reserved" 1905 "reserved" 1904 "reserved" 1903 "reserved" 1902 "reserved" 1901 "reserved" 1900 "reserved" 1899 "reserved" 1898 "reserved" 1897 "reserved" 1896 "reserved" 1895 "reserved" 1894 "reserved" 1893 "reserved" 1892 "reserved" 1891 "reserved" 1890 "reserved" 1889 "reserved" 1888 "reserved" 1887 "reserved" 1886 "reserved" 1885 "reserved" 1884 "reserved" 1883 "reserved" 1882 "reserved" 1881 "reserved" 1880 "reserved" 1879 "reserved" 1878 "reserved" 1877 "reserved" 1876 "reserved" 1875 "reserved" 1874 "reserved" 1873 "reserved" 1872 "reserved" 1871 "reserved" 1870 "reserved" 1869 "reserved" 1868 "reserved" 1867 "reserved" 1866 "reserved" 1865 "reserved" 1864 "reserved" 1863 "reserved" 1862 "reserved" 1861 "reserved" 1860 "reserved" 1859 "reserved" 1858 "reserved" 1857 "reserved" 1856 "reserved" 1855 "reserved" 1854 "reserved" 1853 "reserved" 1852 "reserved" 1851 "reserved" 1850 "reserved" 1849 "reserved" 1848 "reserved" 1847 "reserved" 1846 "reserved" 1845 "reserved" 1844 "reserved" 1843 "reserved" 1842 "reserved" 1841 "reserved" 1840 "reserved" 1839 "reserved" 1838 "reserved" 1837 "reserved" 1836 "reserved" 1835 "reserved" 1834 "reserved" 1833 "reserved" 1832 "reserved" 1831 "reserved" 1830 "reserved" 1829 "reserved" 1828 "reserved" 1827 "reserved" 1826 "reserved" 1825 "reserved" 1824 "reserved" 1823 "reserved" 1822 "reserved" 1821 "reserved" 1820 "reserved" 1819 "reserved" 1818 "reserved" 1817 "reserved" 1816 "reserved" 1815 "reserved" 1814 "reserved" 1813 "reserved" 1812 "reserved" 1811 "reserved" 1810 "reserved" 1809 "reserved" 1808 "reserved" 1807 "reserved" 1806 "reserved" 1805 "reserved" 1804 "reserved" 1803 "reserved" 1802 "reserved" 1801 "reserved" 1800 "reserved" 1799 "reserved" 1798 "reserved" 1797 "reserved" 1796 "reserved" 1795 "reserved" 1794 "reserved" 1793 "reserved" 1792 "reserved" 1791 "reserved" 1790 "reserved" 1789 "reserved" 1788 "reserved" 1787 "reserved" 1786 "reserved" 1785 "reserved" 1784 "reserved" 1783 "reserved" 1782 "reserved" 1781 "reserved" 1780 "reserved" 1779 "reserved" 1778 "reserved" 1777 "reserved" 1776 "reserved" 1775 "reserved" 1774 "reserved" 1773 "reserved" 1772 "reserved" 1771 "reserved" 1770 "reserved" 1769 "reserved" 1768 "reserved" 1767 "reserved" 1766 "reserved" 1765 "reserved" 1764 "reserved" 1763 "reserved" 1762 "reserved" 1761 "reserved" 1760 "reserved" 1759 "reserved" 1758 "reserved" 1757 "reserved" 1756 "reserved" 1755 "reserved" 1754 "reserved" 1753 "reserved" 1752 "reserved" 1751 "reserved" 1750 "reserved" 1749 "reserved" 1748 "reserved" 1747 "reserved" 1746 "reserved" 1745 "reserved" 1744 "reserved" 1743 "reserved" 1742 "reserved" 1741 "reserved" 1740 "reserved" 1739 "reserved" 1738 "reserved" 1737 "reserved" 1736 "reserved" 1735 "reserved" 1734 "reserved" 1733 "reserved" 1732 "reserved" 1731 "reserved" 1730 "reserved" 1729 "reserved" 1728 "reserved" 1727 "reserved" 1726 "reserved" 1725 "reserved" 1724 "reserved" 1723 "reserved" 1722 "reserved" 1721 "reserved" 1720 "reserved" 1719 "reserved" 1718 "reserved" 1717 "reserved" 1716 "reserved" 1715 "reserved" 1714 "reserved" 1713 "reserved" 1712 "reserved" 1711 "reserved" 1710 "reserved" 1709 "reserved" 1708 "reserved" 1707 "reserved" 1706 "reserved" 1705 "reserved" 1704 "reserved" 1703 "reserved" 1702 "reserved" 1701 "reserved" 1700 "reserved" 1699 "reserved" 1698 "reserved" 1697 "reserved" 1696 "reserved" 1695 "reserved" 1694 "reserved" 1693 "reserved" 1692 "reserved" 1691 "reserved" 1690 "reserved" 1689 "reserved" 1688 "reserved" 1687 "reserved" 1686 "reserved" 1685 "reserved" 1684 "reserved" 1683 "reserved" 1682 "reserved" 1681 "reserved" 1680 "reserved" 1679 "reserved" 1678 "reserved" 1677 "reserved" 1676 "reserved" 1675 "reserved" 1674 "reserved" 1673 "reserved" 1672 "reserved" 1671 "reserved" 1670 "reserved" 1669 "reserved" 1668 "reserved" 1667 "reserved" 1666 "reserved" 1665 "reserved" 1664 "reserved" 1663 "reserved" 1662 "reserved" 1661 "reserved" 1660 "reserved" 1659 "reserved" 1658 "reserved" 1657 "reserved" 1656 "reserved" 1655 "reserved" 1654 "reserved" 1653 "reserved" 1652 "reserved" 1651 "reserved" 1650 "reserved" 1649 "reserved" 1648 "reserved" 1647 "reserved" 1646 "reserved" 1645 "reserved" 1644 "reserved" 1643 "reserved" 1642 "reserved" 1641 "reserved" 1640 "reserved" 1639 "reserved" 1638 "reserved" 1637 "reserved" 1636 "reserved" 1635 "reserved" 1634 "reserved" 1633 "reserved" 1632 "reserved" 1631 "reserved" 1630 "reserved" 1629 "reserved" 1628 "reserved" 1627 "reserved" 1626 "reserved" 1625 "reserved" 1624 "reserved" 1623 "reserved" 1622 "reserved" 1621 "reserved" 1620 "reserved" 1619 "reserved" 1618 "reserved" 1617 "reserved" 1616 "reserved" 1615 "reserved" 1614 "reserved" 1613 "reserved" 1612 "reserved" 1611 "reserved" 1610 "reserved" 1609 "reserved" 1608 "reserved" 1607 "reserved" 1606 "reserved" 1605 "reserved" 1604 "reserved" 1603 "reserved" 1602 "reserved" 1601 "reserved" ;
VAL_ 339 ADAS_FCW_Distance 1023 "reserved" 1022 "reserved" 1021 "reserved" 1020 "reserved" 1019 "reserved" 1018 "reserved" 1017 "reserved" 1016 "reserved" 1015 "reserved" 1014 "reserved" 1013 "reserved" 1012 "reserved" 1011 "reserved" 1010 "reserved" 1009 "reserved" 1008 "reserved" 1007 "reserved" 1006 "reserved" 1005 "reserved" 1004 "reserved" 1003 "reserved" 1002 "reserved" 1001 "reserved" ;
VAL_ 339 ADAS_AEB_On 3 "Others" 2 "Preceding" 1 "Oncoming" 0 "Idle" ;
VAL_ 1312 DTC_Severity 7 "Reserved" 6 "Reserved" 5 "Reserved" 4 "Reserved" 3 "Reserved" 2 "����" 1 "��������" 0 "Initial" ;
VAL_ 1041 MDL_FL_RepeatMessageRequestBit 1 "�ñ��ķ��ͽڵ����������ڵ�����ظ�����״̬" 0 "�ñ��ķ��ͽڵ�δ���������ڵ�����ظ�����״̬" ;
VAL_ 1041 MDL_FL_ActiveWakeupBit 1 "�ñ��ķ��ͽڵ�������������" 0 "�ñ��ķ��ͽڵ�δ�����������磨�������ڵ㻽�ѣ�" ;
VAL_ 1041 MDL_FL_RepeatSts 1 "�ڵ㴦���ظ�����״̬" 0 "�ڵ㲻���ظ�����״̬" ;
VAL_ 1041 MDL_FL_NMReq_Poweron 1 " Active" 0 " Inactive" ;
VAL_ 1041 MDL_FL_NMReq_Diag 1 " Active" 0 " Inactive" ;
VAL_ 1041 MDL_FL_NMReq_NM 1 " Active" 0 " Inactive" ;
VAL_ 1041 MDL_FL_NMReq_WelcomeUpd 1 " Active" 0 " Inactive" ;
VAL_ 1041 MDL_FL_FirstWakeupReason 63 " Invalid" 2 " NM����" 1 " ����Ӳ��ON" 0 " Initial" ;
VAL_ 1042 MDL_FR_RepeatMessageRequestBit 1 "�ñ��ķ��ͽڵ����������ڵ�����ظ�����״̬" 0 "�ñ��ķ��ͽڵ�δ���������ڵ�����ظ�����״̬" ;
VAL_ 1042 MDL_FR_ActiveWakeupBit 1 "�ñ��ķ��ͽڵ�������������" 0 "�ñ��ķ��ͽڵ�δ�����������磨�������ڵ㻽�ѣ�" ;
VAL_ 1042 MDL_FR_RepeatSts 1 "�ڵ㴦���ظ�����״̬" 0 "�ڵ㲻���ظ�����״̬" ;
VAL_ 1042 MDL_FR_NMReq_Poweron 1 " Active" 0 " Inactive" ;
VAL_ 1042 MDL_FR_NMReq_Diag 1 " Active" 0 " Inactive" ;
VAL_ 1042 MDL_FR_NMReq_NM 1 " Active" 0 " Inactive" ;
VAL_ 1042 MDL_FL_NMReq_WelcomeUpd_2 1 " Active" 0 " Inactive" ;
VAL_ 1042 MDL_FR_FirstWakeupReason 63 " Invalid" 2 " NM����" 1 " ����Ӳ��ON" 0 " Initial" ;
VAL_ 1344 TimeSync_Format 3 "Reserved" 2 "West" 1 "East" 0 "Initial" ;
VAL_ 1344 TimeSync_Valid 31 "Reserved" 30 "Reserved" 29 "Reserved" 28 "Reserved" 27 "Reserved" 26 "Reserved" 25 "Reserved" 24 "Reserved" 23 "Reserved" 22 "Reserved" 21 "Reserved" 20 "Reserved" 19 "Reserved" 18 "Reserved" 17 "Reserved" 16 "Reserved" 15 "Reserved" 14 "Reserved" 13 "Reserved" 12 "TimeZone 12" 11 "TimeZone 11" 10 "TimeZone 10" 9 "TimeZone 9" 8 "TimeZone 8" 7 "TimeZone 7" 6 "TimeZone 6" 5 "TimeZone 5" 4 "TimeZone 4" 3 "TimeZone 3" 2 "TimeZone 2" 1 "TimeZone 1" 0 "Initial" ;
VAL_ 1344 TimeFlag 3 "Reserved" 2 "With Offset(Reserved)" 1 "Valid" 0 "Invalid" ;
